VERSION "Arrival Ver 3.3"

NS_ :

BS_:

BU_: VCU EPS IBC
VAL_TABLE_ GlobalRealTime 1 "Valid" 0 "Invalid" ;
VAL_TABLE_ Driver_Intervention 3 "SNA" 2 "ERROR" 1 "INTERVENTION" 0 "NO INTERVENTION" ;
VAL_TABLE_ DM_AD_Activation 3 "SNA" 2 "ERROR" 1 "ON" 0 "OFF" ;
VAL_TABLE_ DM_Mode_AD_HMI 4 "AD ERROR" 3 "AD MEAS ON" 2 "AD ON" 1 "AD READY" 0 "AD OFF" ;
VAL_TABLE_ MOTLmtd 1 "MOT_Limited" 0 "MOT_NotLimited" ;
VAL_TABLE_ SPCLmtd 1 "SPC_Limited" 0 "SPC_NotLimited" ;
VAL_TABLE_ BCUIntLghtSt 3 "sna" 2 "on" 1 "dimmed" 0 "off" ;
VAL_TABLE_ CCUClInf 1 "active" 0 "not active" ;
VAL_TABLE_ PositiveNegative 1 "Negative" 0 "Positive" ;
VAL_TABLE_ ActiveNot 1 "Active" 0 "Not Active" ;
VAL_TABLE_ EPSTrqOvrly 3 "Permanently Failed" 2 "Temporarily Limited" 1 "Active" 0 "Inactive" ;
VAL_TABLE_ HandsOnDetected 1 "TakeOverDetected" 0 "NoTakeOverDetected" ;
VAL_TABLE_ EPSCurrState 9 "EPS_Failed" 8 "EPS_ShutDown" 7 "EPS_ReadyToSleep" 6 "EPS_AutoAndPosHold" 5 "EPS_AutoAndPosServoActive" 4 "EPS_ManualAndPosServoFail" 3 "EPS_ManualAndPosServoInhibit" 2 "EPS_ManualAndPosServoReady" 1 "EPS_Init" 0 "EPS_Off" ;
VAL_TABLE_ Vldt1 1 "Invalid" 0 "Valid" ;
VAL_TABLE_ Vldt2 3 "sna" 2 "error" 1 "Invalid" 0 "Valid" ;
VAL_TABLE_ ADSt 15 "sna" 14 "error" 5 "Autonomous Drive" 4 "Failure" 3 "Shutdown" 2 "Inhibit" 1 "Active" 0 "Init" ;
VAL_TABLE_ SNAERRneg 1 "error" 0 "sna" ;
VAL_TABLE_ SNAERR3 7 "sna" 6 "error" ;
VAL_TABLE_ SNAERR4 15 "sna" 14 "error" ;
VAL_TABLE_ SNAERR5 31 "sna" 30 "error" ;
VAL_TABLE_ SNAERR6 63 "sna" 62 "error" ;
VAL_TABLE_ SNAERR7 127 "sna" 126 "error" ;
VAL_TABLE_ SNAERR8 255 "sna" 254 "error" ;
VAL_TABLE_ SNAERR9 511 "sna" 510 "error" ;
VAL_TABLE_ SNAERR10 1023 "sna" 1022 "error" ;
VAL_TABLE_ SNAERR11 2047 "sna" 2046 "error" ;
VAL_TABLE_ SNAERR12 4095 "sna" 4094 "error" ;
VAL_TABLE_ SNAERR13 8191 "sna" 8190 "error" ;
VAL_TABLE_ SNAERR14 16383 "sna" 16382 "error" ;
VAL_TABLE_ SNAERR15 32767 "sna" 32766 "error" ;
VAL_TABLE_ SNAERR16 65535 "sna" 65534 "error" ;
VAL_TABLE_ SNAERR17 131071 "sna" 131070 "error" ;
VAL_TABLE_ SNAERR18 262143 "sna" 262142 "error" ;
VAL_TABLE_ SNAERR19 524287 "sna" 524286 "error" ;
VAL_TABLE_ SNAERR20 1048575 "sna" 1048574 "error" ;
VAL_TABLE_ SNAERR21 2097151 "sna" 2097150 "error" ;
VAL_TABLE_ SNAERR22 4194303 "sna" 4194302 "error" ;
VAL_TABLE_ SNAERR23 8388607 "sna" 8388606 "error" ;
VAL_TABLE_ SNAERR24 16777215 "sna" 16777214 "error" ;
VAL_TABLE_ SNAERR32 -1 "sna" -2 "error" ;
VAL_TABLE_ IBCRegenBrkSt 1 "active" 0 "passive" ;
VAL_TABLE_ IntErr 3 "sna" 2 "red" 1 "yellow" 0 "green" ;
VAL_TABLE_ VhclLckSt 1 "locked" 0 "unlocked" ;

BO_ 1 New_Message_59: 8 Vector__XXX
 SG_ New_Signal_483 : 32|8@1+ (1,0) [0|0] "" Vector__XXX

BO_ 0 New_Message_58: 8 Vector__XXX
 SG_ New_Signal_482 : 0|8@1+ (1,0) [0|0] "" Vector__XXX

BO_ 168 EPS_FD_Data: 8 EPS
 SG_ EPS_Data_Export_1 : 39|32@0+ (1,0) [0|4294967295] "" Vector__XXX
 SG_ EPS_Data_Export_0 : 7|32@0+ (1,0) [0|4294967295] "" Vector__XXX

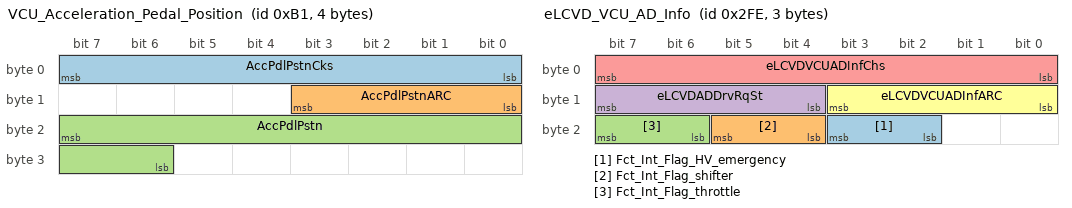
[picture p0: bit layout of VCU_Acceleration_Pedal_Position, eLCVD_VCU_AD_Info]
BO_ 177 VCU_Acceleration_Pedal_Position: 4 VCU
 SG_ AccPdlPstnCks : 7|8@0+ (1,0) [0|255] ""  IBC
 SG_ AccPdlPstnARC : 11|4@0+ (1,0) [0|15] ""  IBC
 SG_ AccPdlPstn : 23|10@0+ (0.1,0) [0|102.3] "%"  IBC

BO_ 766 eLCVD_VCU_AD_Info: 3 VCU
 SG_ Fct_Int_Flag_HV_emergency : 19|2@0+ (1,0) [0|3] ""  EPS,IBC
 SG_ Fct_Int_Flag_shifter : 21|2@0+ (1,0) [0|3] ""  EPS,IBC
 SG_ Fct_Int_Flag_throttle : 23|2@0+ (1,0) [0|3] ""  EPS,IBC
 SG_ eLCVDADDrvRqSt : 15|4@0+ (1,0) [0|15] ""  EPS,IBC
 SG_ eLCVDVCUADInfChs : 7|8@0+ (1,0) [0|255] ""  EPS,IBC
 SG_ eLCVDVCUADInfARC : 11|4@0+ (1,0) [0|15] ""  EPS,IBC

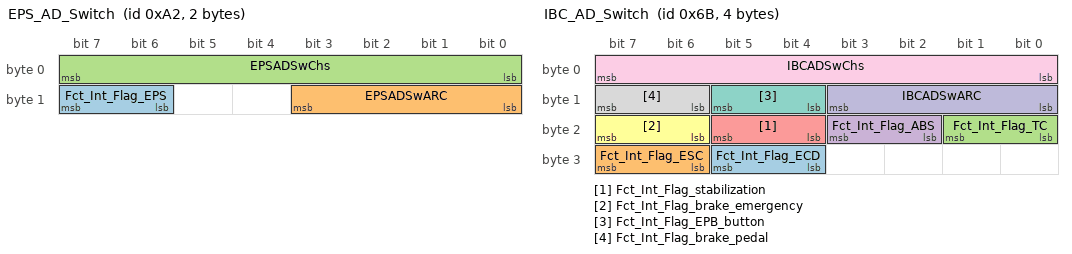
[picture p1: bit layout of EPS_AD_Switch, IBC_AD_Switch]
BO_ 162 EPS_AD_Switch: 2 EPS
 SG_ Fct_Int_Flag_EPS : 15|2@0+ (1,0) [0|3] ""  IBC,VCU
 SG_ EPSADSwARC : 11|4@0+ (1,0) [0|15] ""  IBC,VCU
 SG_ EPSADSwChs : 7|8@0+ (1,0) [0|255] ""  IBC,VCU

BO_ 107 IBC_AD_Switch: 4 IBC
 SG_ Fct_Int_Flag_ECD : 29|2@0+ (1,0) [0|3] ""  EPS,VCU
 SG_ Fct_Int_Flag_ESC : 31|2@0+ (1,0) [0|3] ""  EPS,VCU
 SG_ Fct_Int_Flag_TC : 17|2@0+ (1,0) [0|3] ""  EPS,VCU
 SG_ Fct_Int_Flag_ABS : 19|2@0+ (1,0) [0|3] ""  EPS,VCU
 SG_ Fct_Int_Flag_stabilization : 21|2@0+ (1,0) [0|3] ""  EPS,VCU
 SG_ Fct_Int_Flag_brake_emergency : 23|2@0+ (1,0) [0|3] ""  EPS,VCU
 SG_ Fct_Int_Flag_EPB_button : 13|2@0+ (1,0) [0|3] ""  EPS,VCU
 SG_ Fct_Int_Flag_brake_pedal : 15|2@0+ (1,0) [0|3] ""  EPS,VCU
 SG_ IBCADSwChs : 7|8@0+ (1,0) [0|255] ""  EPS,VCU
 SG_ IBCADSwARC : 11|4@0+ (1,0) [0|15] ""  EPS,VCU

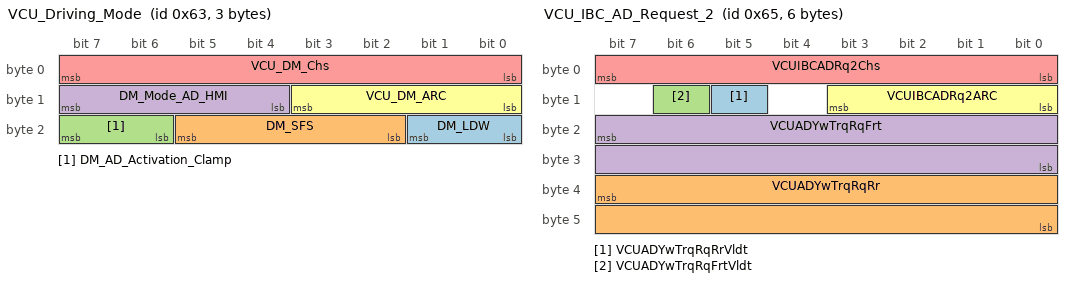
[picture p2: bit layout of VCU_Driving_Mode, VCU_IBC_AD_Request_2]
BO_ 99 VCU_Driving_Mode: 3 VCU
 SG_ DM_LDW : 17|2@0+ (1,0) [0|3] ""  EPS,IBC
 SG_ DM_SFS : 21|4@0+ (1,0) [0|15] ""  EPS,IBC
 SG_ DM_AD_Activation_Clamp : 23|2@0+ (1,0) [0|3] ""  EPS,IBC
 SG_ DM_Mode_AD_HMI : 15|4@0+ (1,0) [0|15] ""  EPS,IBC
 SG_ VCU_DM_Chs : 7|8@0+ (1,0) [0|255] ""  EPS,IBC
 SG_ VCU_DM_ARC : 11|4@0+ (1,0) [0|15] ""  EPS,IBC

BO_ 101 VCU_IBC_AD_Request_2: 6 VCU
 SG_ VCUADYwTrqRqRrVldt : 13|1@0+ (1,0) [0|1] ""  IBC
 SG_ VCUADYwTrqRqRr : 39|16@0+ (1,-32768) [-32768|32767] "Nm"  IBC
 SG_ VCUADYwTrqRqFrtVldt : 14|1@0+ (1,0) [0|1] ""  IBC
 SG_ VCUADYwTrqRqFrt : 23|16@0+ (1,-32768) [-32768|32767] "Nm"  IBC
 SG_ VCUIBCADRq2Chs : 7|8@0+ (1,0) [0|255] ""  IBC
 SG_ VCUIBCADRq2ARC : 11|4@0+ (1,0) [0|15] ""  IBC

BO_ 800 TPMS_Info: 8 VCU
 SG_ ExTirePressSupport : 38|2@1+ (1,0) [0|3] ""  IBC
 SG_ TirePressThresholdDetection_13 m19 : 61|3@1+ (1,0) [0|7] ""  IBC
 SG_ TirePressThresholdDetection_12 m18 : 61|3@1+ (1,0) [0|7] ""  IBC
 SG_ TirePressThresholdDetection_11 m17 : 61|3@1+ (1,0) [0|7] ""  IBC
 SG_ TirePressThresholdDetection_10 m16 : 61|3@1+ (1,0) [0|7] ""  IBC
 SG_ TirePressThresholdDetection_01 m1 : 61|3@1+ (1,0) [0|7] ""  IBC
 SG_ TirePress_33 m51 : 8|8@1+ (4,0) [0|1000] "kPa"  IBC
 SG_ TirePress_32 m50 : 8|8@1+ (4,0) [0|1000] "kPa"  IBC
 SG_ TirePress_31 m49 : 8|8@1+ (4,0) [0|1000] "kPa"  IBC
 SG_ TirePress_30 m48 : 8|8@1+ (4,0) [0|1000] "kPa"  IBC
 SG_ TirePress_23 m35 : 8|8@1+ (4,0) [0|1000] "kPa"  IBC
 SG_ TirePress_22 m34 : 8|8@1+ (4,0) [0|1000] "kPa"  IBC
 SG_ TirePress_21 m33 : 8|8@1+ (4,0) [0|1000] "kPa"  IBC
 SG_ TirePress_20 m32 : 8|8@1+ (4,0) [0|1000] "kPa"  IBC
 SG_ TirePress_13 m19 : 8|8@1+ (4,0) [0|1000] "kPa"  IBC
 SG_ TirePress_12 m18 : 8|8@1+ (4,0) [0|1000] "kPa"  IBC
 SG_ TirePress_11 m17 : 8|8@1+ (4,0) [0|1000] "kPa"  IBC
 SG_ TirePress_10 m16 : 8|8@1+ (4,0) [0|1000] "kPa"  IBC
 SG_ TireAirLeakageRate_33 m51 : 40|16@1+ (0.1,0) [0|6425.5] "Pa/s"  IBC
 SG_ TireAirLeakageRate_32 m50 : 40|16@1+ (0.1,0) [0|6425.5] "Pa/s"  IBC
 SG_ TireAirLeakageRate_31 m49 : 40|16@1+ (0.1,0) [0|6425.5] "Pa/s"  IBC
 SG_ TireAirLeakageRate_30 m48 : 40|16@1+ (0.1,0) [0|6425.5] "Pa/s"  IBC
 SG_ TireAirLeakageRate_23 m35 : 40|16@1+ (0.1,0) [0|6425.5] "Pa/s"  IBC
 SG_ TireAirLeakageRate_22 m34 : 40|16@1+ (0.1,0) [0|6425.5] "Pa/s"  IBC
 SG_ TireAirLeakageRate_21 m33 : 40|16@1+ (0.1,0) [0|6425.5] "Pa/s"  IBC
 SG_ TireAirLeakageRate_20 m32 : 40|16@1+ (0.1,0) [0|6425.5] "Pa/s"  IBC
 SG_ TireAirLeakageRate_13 m19 : 40|16@1+ (0.1,0) [0|6425.5] "Pa/s"  IBC
 SG_ TireAirLeakageRate_12 m18 : 40|16@1+ (0.1,0) [0|6425.5] "Pa/s"  IBC
 SG_ TireAirLeakageRate_11 m17 : 40|16@1+ (0.1,0) [0|6425.5] "Pa/s"  IBC
 SG_ TireAirLeakageRate_10 m16 : 40|16@1+ (0.1,0) [0|6425.5] "Pa/s"  IBC
 SG_ TireAirLeakageRate_01 m1 : 40|16@1+ (0.1,0) [0|6425.5] "Pa/s"  IBC
 SG_ TireAirLeakageRate_00 m0 : 40|16@1+ (0.1,0) [0|6425.5] "Pa/s"  IBC
 SG_ CTIWheelSensorStatus_33 m51 : 32|2@1+ (1,0) [0|3] ""  IBC
 SG_ CTIWheelSensorStatus_32 m50 : 32|2@1+ (1,0) [0|3] ""  IBC
 SG_ CTIWheelSensorStatus_31 m49 : 32|2@1+ (1,0) [0|3] ""  IBC
 SG_ CTIWheelSensorStatus_30 m48 : 32|2@1+ (1,0) [0|3] ""  IBC
 SG_ CTIWheelSensorStatus_23 m35 : 32|2@1+ (1,0) [0|3] ""  IBC
 SG_ CTIWheelSensorStatus_22 m34 : 32|2@1+ (1,0) [0|3] ""  IBC
 SG_ CTIWheelSensorStatus_21 m33 : 32|2@1+ (1,0) [0|3] ""  IBC
 SG_ CTIWheelSensorStatus_20 m32 : 32|2@1+ (1,0) [0|3] ""  IBC
 SG_ CTIWheelSensorStatus_13 m19 : 32|2@1+ (1,0) [0|3] ""  IBC
 SG_ CTIWheelSensorStatus_12 m18 : 32|2@1+ (1,0) [0|3] ""  IBC
 SG_ CTIWheelSensorStatus_11 m17 : 32|2@1+ (1,0) [0|3] ""  IBC
 SG_ CTIWheelSensorStatus_10 m16 : 32|2@1+ (1,0) [0|3] ""  IBC
 SG_ CTIWheelSensorStatus_01 m1 : 32|2@1+ (1,0) [0|3] ""  IBC
 SG_ CTIWheelEndElectricalFault_33 m51 : 36|2@1+ (1,0) [0|3] ""  IBC
 SG_ CTIWheelEndElectricalFault_32 m50 : 36|2@1+ (1,0) [0|3] ""  IBC
 SG_ CTIWheelEndElectricalFault_31 m49 : 36|2@1+ (1,0) [0|3] ""  IBC
 SG_ CTIWheelEndElectricalFault_30 m48 : 36|2@1+ (1,0) [0|3] ""  IBC
 SG_ CTIWheelEndElectricalFault_23 m35 : 36|2@1+ (1,0) [0|3] ""  IBC
 SG_ CTIWheelEndElectricalFault_22 m34 : 36|2@1+ (1,0) [0|3] ""  IBC
 SG_ CTIWheelEndElectricalFault_21 m33 : 36|2@1+ (1,0) [0|3] ""  IBC
 SG_ CTIWheelEndElectricalFault_20 m32 : 36|2@1+ (1,0) [0|3] ""  IBC
 SG_ CTIWheelEndElectricalFault_13 m19 : 36|2@1+ (1,0) [0|3] ""  IBC
 SG_ CTIWheelEndElectricalFault_12 m18 : 36|2@1+ (1,0) [0|3] ""  IBC
 SG_ CTIWheelEndElectricalFault_11 m17 : 36|2@1+ (1,0) [0|3] ""  IBC
 SG_ CTIWheelEndElectricalFault_10 m16 : 36|2@1+ (1,0) [0|3] ""  IBC
 SG_ CTIWheelEndElectricalFault_01 m1 : 36|2@1+ (1,0) [0|3] ""  IBC
 SG_ CTITireStatus_33 m51 : 34|2@1+ (1,0) [0|3] ""  IBC
 SG_ CTITireStatus_32 m50 : 34|2@1+ (1,0) [0|3] ""  IBC
 SG_ CTITireStatus_31 m49 : 34|2@1+ (1,0) [0|3] ""  IBC
 SG_ CTITireStatus_30 m48 : 34|2@1+ (1,0) [0|3] ""  IBC
 SG_ CTITireStatus_23 m35 : 34|2@1+ (1,0) [0|3] ""  IBC
 SG_ CTITireStatus_22 m34 : 34|2@1+ (1,0) [0|3] ""  IBC
 SG_ CTITireStatus_21 m33 : 34|2@1+ (1,0) [0|3] ""  IBC
 SG_ CTITireStatus_20 m32 : 34|2@1+ (1,0) [0|3] ""  IBC
 SG_ CTITireStatus_13 m19 : 34|2@1+ (1,0) [0|3] ""  IBC
 SG_ CTITireStatus_12 m18 : 34|2@1+ (1,0) [0|3] ""  IBC
 SG_ CTITireStatus_11 m17 : 34|2@1+ (1,0) [0|3] ""  IBC
 SG_ CTITireStatus_10 m16 : 34|2@1+ (1,0) [0|3] ""  IBC
 SG_ CTITireStatus_01 m1 : 34|2@1+ (1,0) [0|3] ""  IBC
 SG_ TireTemp_11 m17 : 16|16@1+ (0.03125,-273) [-273|1735] "°C"  IBC
 SG_ TireTemp_33 m51 : 16|16@1+ (0.03125,-273) [-273|1735] "°C"  IBC
 SG_ TireTemp_32 m50 : 16|16@1+ (0.03125,-273) [-273|1735] "°C"  IBC
 SG_ TireTemp_31 m49 : 16|16@1+ (0.03125,-273) [-273|1735] "°C"  IBC
 SG_ TireTemp_30 m48 : 16|16@1+ (0.03125,-273) [-273|1735] "°C"  IBC
 SG_ TireTemp_23 m35 : 16|16@1+ (0.03125,-273) [-273|1735] "°C"  IBC
 SG_ TireTemp_22 m34 : 16|16@1+ (0.03125,-273) [-273|1735] "°C"  IBC
 SG_ TireTemp_21 m33 : 16|16@1+ (0.03125,-273) [-273|1735] "°C"  IBC
 SG_ TireTemp_20 m32 : 16|16@1+ (0.03125,-273) [-273|1735] "°C"  IBC
 SG_ TireTemp_13 m19 : 16|16@1+ (0.03125,-273) [-273|1735] "°C"  IBC
 SG_ TireTemp_12 m18 : 16|16@1+ (0.03125,-273) [-273|1735] "°C"  IBC
 SG_ TireTemp_10 m16 : 16|16@1+ (0.03125,-273) [-273|1735] "°C"  IBC
 SG_ TireTemp_01 m1 : 16|16@1+ (0.03125,-273) [-273|1735] "°C"  IBC
 SG_ TireTemp_00 m0 : 16|16@1+ (0.03125,-273) [-273|1735] "°C"  IBC
 SG_ TirePressThresholdDetection_33 m51 : 61|3@1+ (1,0) [0|7] ""  IBC
 SG_ TirePressThresholdDetection_32 m50 : 61|3@1+ (1,0) [0|7] ""  IBC
 SG_ TirePressThresholdDetection_31 m49 : 61|3@1+ (1,0) [0|7] ""  IBC
 SG_ TirePressThresholdDetection_30 m48 : 61|3@1+ (1,0) [0|7] ""  IBC
 SG_ TirePressThresholdDetection_23 m35 : 61|3@1+ (1,0) [0|7] ""  IBC
 SG_ TirePressThresholdDetection_22 m34 : 61|3@1+ (1,0) [0|7] ""  IBC
 SG_ TirePressThresholdDetection_21 m33 : 61|3@1+ (1,0) [0|7] ""  IBC
 SG_ TirePressThresholdDetection_20 m32 : 61|3@1+ (1,0) [0|7] ""  IBC
 SG_ TirePressThresholdDetection_00 m0 : 61|3@1+ (1,0) [0|7] ""  IBC
 SG_ TirePress_01 m1 : 8|8@1+ (4,0) [0|1000] "kPa"  IBC
 SG_ TirePress_00 m0 : 8|8@1+ (4,0) [0|1000] "kPa"  IBC
 SG_ CTIWheelSensorStatus_00 m0 : 32|2@1+ (1,0) [0|3] ""  IBC
 SG_ CTIWheelEndElectricalFault_00 m0 : 36|2@1+ (1,0) [0|3] ""  IBC
 SG_ CTITireStatus_00 m0 : 34|2@1+ (1,0) [0|3] ""  IBC
 SG_ TireLocation M : 0|8@1+ (1,0) [0|255] ""  IBC

BO_ 1985 EPS_CCP_RX_CRO: 8 Vector__XXX
 SG_ CRO_data_field : 23|48@0+ (1,0) [0|0] ""  EPS
 SG_ CTR : 15|8@0+ (1,0) [0|0] ""  EPS
 SG_ CMD : 7|8@0+ (1,0) [0|0] ""  EPS

BO_ 2001 EPS_CCP_TX_DTO: 8 EPS
 SG_ PID : 7|8@0+ (1,0) [0|0] "" Vector__XXX

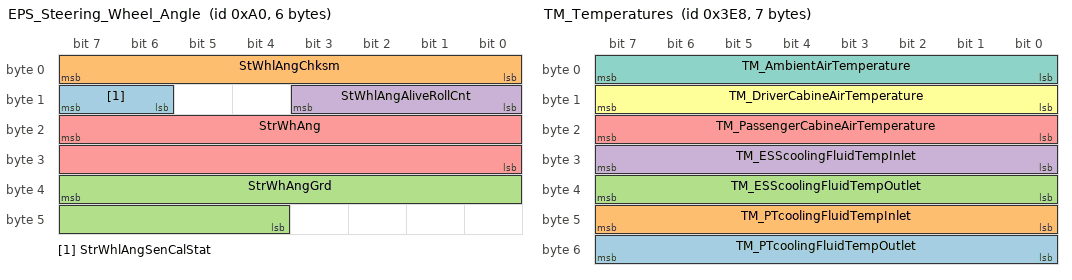
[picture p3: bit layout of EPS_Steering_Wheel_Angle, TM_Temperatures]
BO_ 160 EPS_Steering_Wheel_Angle: 6 EPS
 SG_ StrWhlAngSenCalStat : 15|2@0+ (1,0) [0|3] ""  IBC,VCU
 SG_ StWhlAngChksm : 7|8@0+ (1,0) [0|255] ""  VCU,IBC
 SG_ StrWhAngGrd : 39|12@0+ (1,-2048) [-2048|2047] "deg/sec"  VCU,IBC
 SG_ StWhlAngAliveRollCnt : 11|4@0+ (1,0) [0|15] ""  VCU,IBC
 SG_ StrWhAng : 23|16@0+ (0.025,-819) [-819|819.375] "deg"  VCU,IBC

BO_ 1000 TM_Temperatures: 7 VCU
 SG_ TM_PTcoolingFluidTempOutlet : 55|8@0+ (1,-40) [-40|215] "°C"  IBC
 SG_ TM_PTcoolingFluidTempInlet : 47|8@0+ (1,-40) [-40|215] "°C"  IBC
 SG_ TM_ESScoolingFluidTempOutlet : 39|8@0+ (1,-40) [-40|215] "°C"  IBC
 SG_ TM_ESScoolingFluidTempInlet : 31|8@0+ (1,-40) [-40|215] "°C"  IBC
 SG_ TM_PassengerCabineAirTemperature : 23|8@0+ (1,-40) [-40|215] "°C"  IBC
 SG_ TM_DriverCabineAirTemperature : 15|8@0+ (1,-40) [-40|215] "°C"  IBC
 SG_ TM_AmbientAirTemperature : 7|8@0+ (1,-40) [-40|215] "°C"  IBC

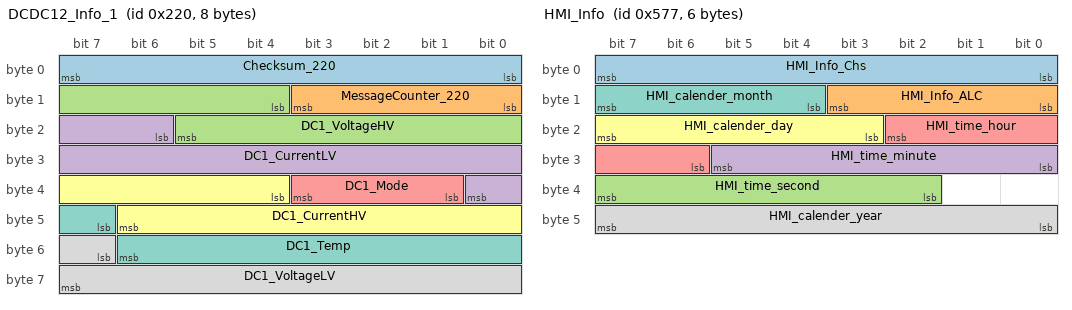
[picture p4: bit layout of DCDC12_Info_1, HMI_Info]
BO_ 544 DCDC12_Info_1: 8 VCU
 SG_ Checksum_220 : 0|8@1+ (1,0) [0|255] "-"  EPS,IBC
 SG_ MessageCounter_220 : 8|4@1+ (1,0) [0|15] "-"  EPS,IBC
 SG_ DC1_VoltageHV : 12|10@1+ (1,0) [0|1021] "V"  EPS,IBC
 SG_ DC1_CurrentLV : 22|11@1+ (1,-1023) [-1023|1022] "A"  EPS,IBC
 SG_ DC1_Mode : 33|3@1+ (1,0) [0|7] "-"  EPS,IBC
 SG_ DC1_CurrentHV : 36|11@1+ (0.0625,-63.90625) [-63.90625|63.90625] "A"  EPS,IBC
 SG_ DC1_Temp : 47|8@1+ (1,-40) [-40|213] "°C"  EPS,IBC
 SG_ DC1_VoltageLV : 55|9@1+ (0.125,0) [0|63.625] "V"  EPS,IBC

BO_ 1399 HMI_Info: 6 VCU
 SG_ HMI_Info_Chs : 7|8@0+ (1,0) [0|255] ""  EPS,IBC
 SG_ HMI_Info_ALC : 11|4@0+ (1,0) [0|15] "Counts"  EPS,IBC
 SG_ HMI_time_second : 39|6@0+ (1,1) [1|64] "s"  EPS,IBC
 SG_ HMI_time_minute : 29|6@0+ (1,1) [1|64] "min"  EPS,IBC
 SG_ HMI_time_hour : 18|5@0+ (1,1) [1|32] "h"  EPS,IBC
 SG_ HMI_calender_day : 23|5@0+ (1,1) [1|32] ""  EPS,IBC
 SG_ HMI_calender_month : 15|4@0+ (1,1) [1|16] ""  EPS,IBC
 SG_ HMI_calender_year : 47|8@0+ (1,2000) [2000|2255] ""  EPS,IBC

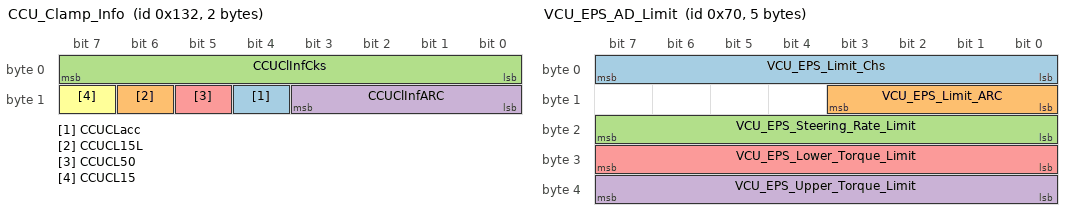
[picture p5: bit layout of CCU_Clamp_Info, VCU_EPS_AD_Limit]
BO_ 306 CCU_Clamp_Info: 2 VCU
 SG_ CCUCLacc : 12|1@0+ (1,0) [0|1] ""  IBC
 SG_ CCUCL15L : 14|1@0+ (1,0) [0|1] ""  IBC
 SG_ CCUClInfCks : 7|8@0+ (1,0) [0|255] ""  IBC
 SG_ CCUClInfARC : 11|4@0+ (1,0) [0|15] ""  IBC
 SG_ CCUCL50 : 13|1@0+ (1,0) [0|1] ""  IBC
 SG_ CCUCL15 : 15|1@0+ (1,0) [0|1] ""  IBC

BO_ 112 VCU_EPS_AD_Limit: 5 VCU
 SG_ VCU_EPS_Limit_Chs : 7|8@0+ (1,0) [0|255] "" Vector__XXX
 SG_ VCU_EPS_Limit_ARC : 11|4@0+ (1,0) [0|15] "" Vector__XXX
 SG_ VCU_EPS_Steering_Rate_Limit : 23|8@0+ (10,-1275) [-1275|1275] "Deg/s" Vector__XXX
 SG_ VCU_EPS_Upper_Torque_Limit : 39|8@0+ (0.1,-12.8) [-12.8|12.7] "Nm" Vector__XXX
 SG_ VCU_EPS_Lower_Torque_Limit : 31|8@0+ (0.1,-12.8) [-12.8|12.7] "Nm" Vector__XXX

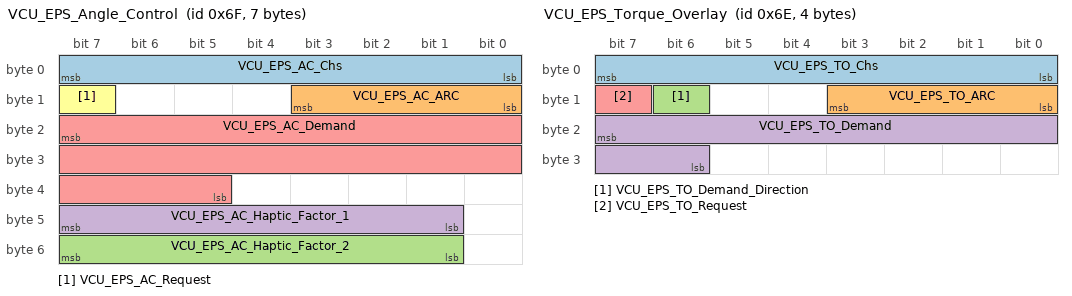
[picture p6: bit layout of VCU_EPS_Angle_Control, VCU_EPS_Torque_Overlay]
BO_ 111 VCU_EPS_Angle_Control: 7 VCU
 SG_ VCU_EPS_AC_Chs : 7|8@0+ (1,0) [0|255] ""  EPS
 SG_ VCU_EPS_AC_ARC : 11|4@0+ (1,0) [0|15] ""  EPS
 SG_ VCU_EPS_AC_Haptic_Factor_2 : 55|7@0+ (0.00787402,0) [0|1.00000054] ""  EPS
 SG_ VCU_EPS_AC_Haptic_Factor_1 : 47|7@0+ (0.00787402,0) [0|1.00000054] ""  EPS
 SG_ VCU_EPS_AC_Demand : 23|19@0+ (0.005,-1310.72) [-720|720] "Deg"  EPS
 SG_ VCU_EPS_AC_Request : 15|1@0+ (1,0) [0|1] ""  EPS

BO_ 110 VCU_EPS_Torque_Overlay: 4 VCU
 SG_ VCU_EPS_TO_Chs : 7|8@0+ (1,0) [0|255] "" Vector__XXX
 SG_ VCU_EPS_TO_ARC : 11|4@0+ (1,0) [0|15] "" Vector__XXX
 SG_ VCU_EPS_TO_Demand_Direction : 14|1@0+ (1,0) [0|1] "" Vector__XXX
 SG_ VCU_EPS_TO_Demand : 23|10@0+ (0.01,0) [0|10.23] "Nm" Vector__XXX
 SG_ VCU_EPS_TO_Request : 15|1@0+ (1,0) [0|1] "" Vector__XXX

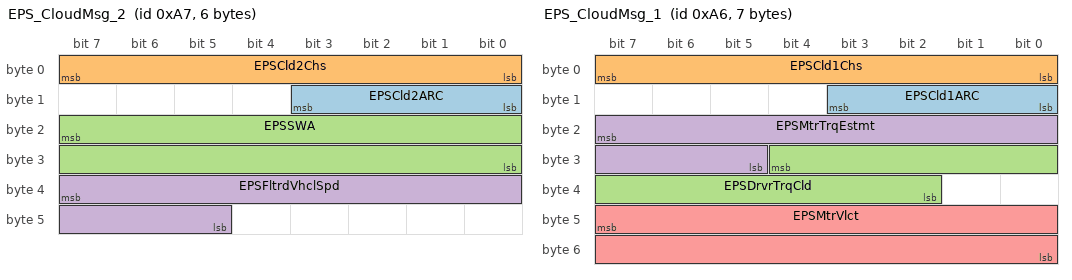
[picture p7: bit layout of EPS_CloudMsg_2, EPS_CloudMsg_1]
BO_ 167 EPS_CloudMsg_2: 6 EPS
 SG_ EPSCld2ARC : 11|4@0+ (1,0) [0|15] ""  VCU
 SG_ EPSCld2Chs : 7|8@0+ (1,0) [0|255] ""  VCU
 SG_ EPSSWA : 23|16@0+ (0.025,-819) [-819|819.375] "Deg"  VCU
 SG_ EPSFltrdVhclSpd : 39|11@0+ (0.1,0) [0|204.7] "km/h"  VCU

BO_ 166 EPS_CloudMsg_1: 7 EPS
 SG_ EPSCld1ARC : 11|4@0+ (1,0) [0|15] ""  VCU
 SG_ EPSCld1Chs : 7|8@0+ (1,0) [0|255] ""  VCU
 SG_ EPSDrvrTrqCld : 28|11@0+ (0.01,-10.23) [-10.23|10.24] "Nm"  VCU
 SG_ EPSMtrTrqEstmt : 23|11@0+ (0.01,-10.23) [-10.23|10.24] "Nm"  VCU
 SG_ EPSMtrVlct : 47|16@0+ (0.005,-163.34) [-163.34|164.335] "rev/s"  VCU

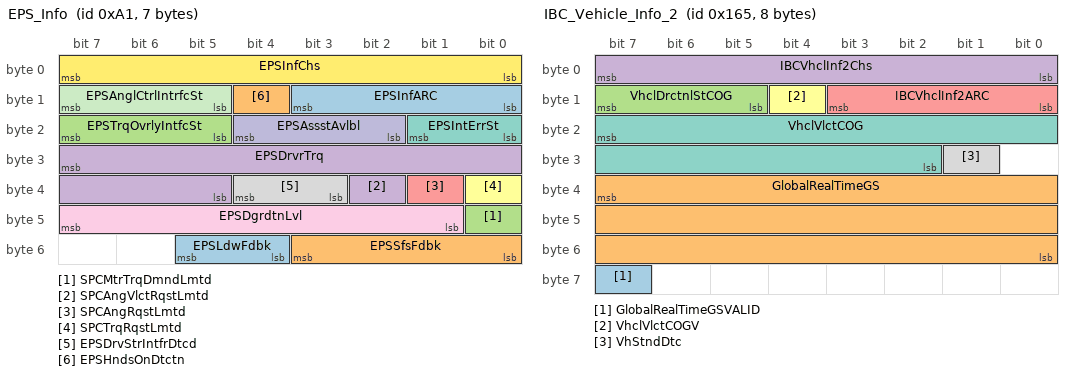
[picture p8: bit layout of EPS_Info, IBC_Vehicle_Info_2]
BO_ 161 EPS_Info: 7 EPS
 SG_ EPSLdwFdbk : 53|2@0+ (1,0) [0|3] "" Vector__XXX
 SG_ EPSSfsFdbk : 51|4@0+ (1,0) [0|15] ""  VCU
 SG_ SPCMtrTrqDmndLmtd : 40|1@0+ (1,0) [0|1] ""  VCU
 SG_ SPCAngVlctRqstLmtd : 34|1@0+ (1,0) [0|1] ""  VCU
 SG_ SPCAngRqstLmtd : 33|1@0+ (1,0) [0|1] ""  VCU
 SG_ SPCTrqRqstLmtd : 32|1@0+ (1,0) [0|1] ""  VCU
 SG_ EPSIntErrSt : 17|2@0+ (1,0) [0|3] ""  VCU
 SG_ EPSDrvStrIntfrDtcd : 36|2@0+ (1,0) [0|3] ""  VCU
 SG_ EPSDgrdtnLvl : 47|7@0+ (1,0) [0|100] "%"  VCU
 SG_ EPSAssstAvlbl : 20|3@0+ (1,0) [0|7] ""  VCU
 SG_ EPSAnglCtrlIntrfcSt : 15|3@0+ (1,0) [0|4] ""  VCU
 SG_ EPSInfChs : 7|8@0+ (1,0) [0|255] ""  VCU
 SG_ EPSInfARC : 11|4@0+ (1,0) [0|15] "Counts"  VCU
 SG_ EPSHndsOnDtctn : 12|1@0+ (1,0) [0|1] ""  VCU
 SG_ EPSTrqOvrlyIntfcSt : 23|3@0+ (1,0) [0|3] ""  VCU
 SG_ EPSDrvrTrq : 31|11@0+ (0.01,-10.24) [-10.24|10.23] "Nm"  VCU

BO_ 357 IBC_Vehicle_Info_2: 8 IBC
 SG_ GlobalRealTimeGSVALID : 63|1@0+ (1,0) [0|1] ""  EPS
 SG_ GlobalRealTimeGS : 39|24@0+ (1,0) [0|16777215] "min"  EPS
 SG_ VhclDrctnlStCOG : 15|3@0+ (1,0) [0|7] ""  EPS,VCU
 SG_ IBCVhclInf2Chs : 7|8@0+ (1,0) [0|255] ""  VCU,EPS
 SG_ IBCVhclInf2ARC : 11|4@0+ (1,0) [0|15] ""  VCU,EPS
 SG_ VhclVlctCOGV : 12|1@0+ (1,0) [0|1] ""  VCU,EPS
 SG_ VhclVlctCOG : 23|14@0+ (0.03125,0) [0|511.96875] "km / h"  VCU,EPS
 SG_ VhStndDtc : 25|1@0+ (1,0) [0|1] ""  EPS,VCU

BO_ 106 IBC_VCU_AD_Info_2: 4 IBC
 SG_ IBCADVhclActBrkTrq : 23|16@0+ (1,-32768) [-32768|32767] "Nm"  VCU
 SG_ IBCVCUADInf2Chs : 7|8@0+ (1,0) [0|255] ""  VCU
 SG_ IBCVCUADInf2ARC : 11|4@0+ (1,0) [0|15] ""  VCU

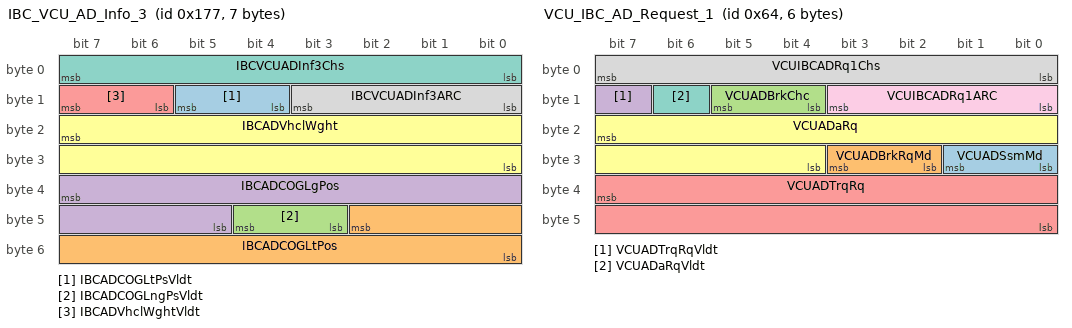
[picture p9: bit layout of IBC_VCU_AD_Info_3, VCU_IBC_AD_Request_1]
BO_ 375 IBC_VCU_AD_Info_3: 7 IBC
 SG_ IBCADCOGLtPsVldt : 13|2@0+ (1,0) [0|3] ""  VCU
 SG_ IBCADCOGLtPos : 42|11@0+ (0.01,-10.24) [-10.24|10.23] "m"  VCU
 SG_ IBCADCOGLngPsVldt : 44|2@0+ (1,0) [0|3] ""  VCU
 SG_ IBCADCOGLgPos : 39|11@0+ (0.01,-10.24) [-10.24|10.23] "m"  VCU
 SG_ IBCADVhclWghtVldt : 15|2@0+ (1,0) [0|3] ""  VCU
 SG_ IBCADVhclWght : 23|16@0+ (1,0) [0|65535] "kg"  VCU
 SG_ IBCVCUADInf3Chs : 7|8@0+ (1,0) [0|255] ""  VCU
 SG_ IBCVCUADInf3ARC : 11|4@0+ (1,0) [0|15] ""  VCU

BO_ 100 VCU_IBC_AD_Request_1: 6 VCU
 SG_ VCUADSsmMd : 25|2@0+ (1,0) [0|3] ""  IBC
 SG_ VCUADBrkRqMd : 27|2@0+ (1,0) [0|3] ""  IBC
 SG_ VCUADBrkChc : 13|2@0+ (1,0) [0|3] ""  IBC
 SG_ VCUADTrqRqVldt : 15|1@0+ (1,0) [0|1] ""  IBC
 SG_ VCUADTrqRq : 39|16@0+ (1,-32768) [-32768|32767] "Nm"  IBC
 SG_ VCUADaRq : 23|12@0+ (0.01,-20.48) [-20.48|20.47] "m/s^2"  IBC
 SG_ VCUADaRqVldt : 14|1@0+ (1,0) [0|1] ""  IBC
 SG_ VCUIBCADRq1Chs : 7|8@0+ (1,0) [0|255] ""  IBC
 SG_ VCUIBCADRq1ARC : 11|4@0+ (1,0) [0|15] ""  IBC

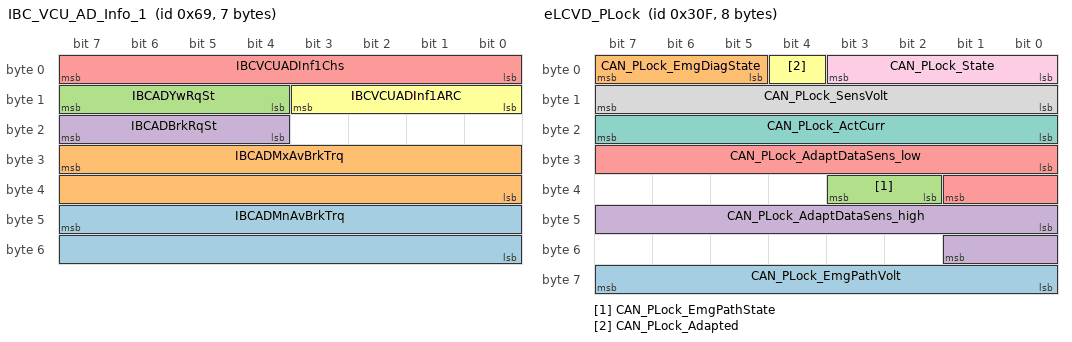
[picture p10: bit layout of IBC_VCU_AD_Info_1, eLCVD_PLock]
BO_ 105 IBC_VCU_AD_Info_1: 7 IBC
 SG_ IBCADMnAvBrkTrq : 47|16@0+ (1,-32768) [-32768|32767] "Nm"  VCU
 SG_ IBCADMxAvBrkTrq : 31|16@0+ (1,-32768) [-32768|32767] "Nm"  VCU
 SG_ IBCADYwRqSt : 15|4@0+ (1,0) [0|15] ""  VCU
 SG_ IBCADBrkRqSt : 23|4@0+ (1,0) [0|15] ""  VCU
 SG_ IBCVCUADInf1Chs : 7|8@0+ (1,0) [0|255] ""  VCU
 SG_ IBCVCUADInf1ARC : 11|4@0+ (1,0) [0|15] ""  VCU

BO_ 777 eLCVD_Driver_Torque_Request: 4 VCU
 SG_ eLCVDDrvTrqRqChs : 7|8@0+ (1,0) [0|255] ""  IBC
 SG_ eLCVDDrvTrqRqARC : 11|4@0+ (1,0) [0|15] ""  IBC
 SG_ eLCVDDrvTrqRq : 23|14@0+ (1,-16383) [-16383|0] "Nm"  IBC

BO_ 783 eLCVD_PLock: 8 VCU
 SG_ CAN_PLock_EmgPathVolt : 56|8@1+ (0.1,0) [0|24] "V"  IBC
 SG_ CAN_PLock_EmgDiagState : 5|3@1+ (1,0) [0|15] ""  IBC
 SG_ CAN_PLock_EmgPathState : 34|2@1+ (1,0) [0|3] ""  IBC
 SG_ CAN_PLock_AdaptDataSens_high : 40|10@1+ (0.005,0) [0|5] "V"  IBC
 SG_ CAN_PLock_AdaptDataSens_low : 24|10@1+ (0.005,0) [0|5] "V"  IBC
 SG_ CAN_PLock_Adapted : 4|1@1+ (1,0) [0|1] ""  IBC
 SG_ CAN_PLock_ActCurr : 16|8@1+ (0.04,0) [0|10] "A"  IBC
 SG_ CAN_PLock_SensVolt : 8|8@1+ (0.02,0) [0|5] "V"  IBC
 SG_ CAN_PLock_State : 0|4@1+ (1,0) [0|15] ""  IBC

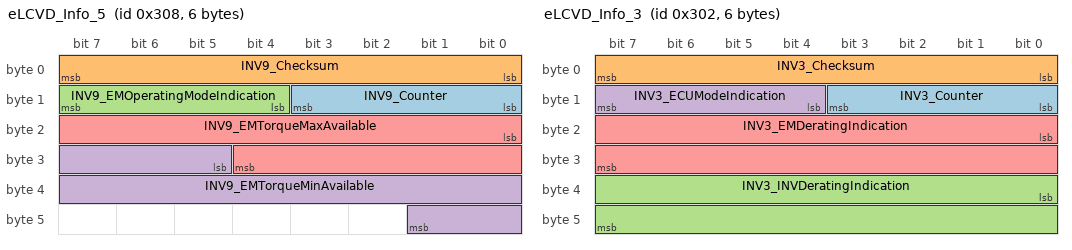
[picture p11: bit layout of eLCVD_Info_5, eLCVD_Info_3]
BO_ 776 eLCVD_Info_5: 6 VCU
 SG_ INV9_Counter : 8|4@1+ (1,0) [0|15] ""  IBC
 SG_ INV9_Checksum : 0|8@1+ (1,0) [0|255] ""  IBC
 SG_ INV9_EMOperatingModeIndication : 12|4@1+ (1,0) [0|15] "Coded"  IBC
 SG_ INV9_EMTorqueMinAvailable : 29|13@1+ (0.25,-2047) [-2047|0] "Nm"  IBC
 SG_ INV9_EMTorqueMaxAvailable : 16|13@1+ (0.25,0) [0|2047] "Nm"  IBC

BO_ 770 eLCVD_Info_3: 6 VCU
 SG_ INV3_Counter : 8|4@1+ (1,0) [0|15] ""  IBC
 SG_ INV3_Checksum : 0|8@1+ (1,0) [0|255] ""  IBC
 SG_ INV3_INVDeratingIndication : 32|16@1+ (1,0) [0|65535] "Coded"  IBC
 SG_ INV3_ECUModeIndication : 12|4@1+ (1,0) [0|15] "Coded"  IBC
 SG_ INV3_EMDeratingIndication : 16|16@1+ (1,0) [0|65535] "Coded"  IBC

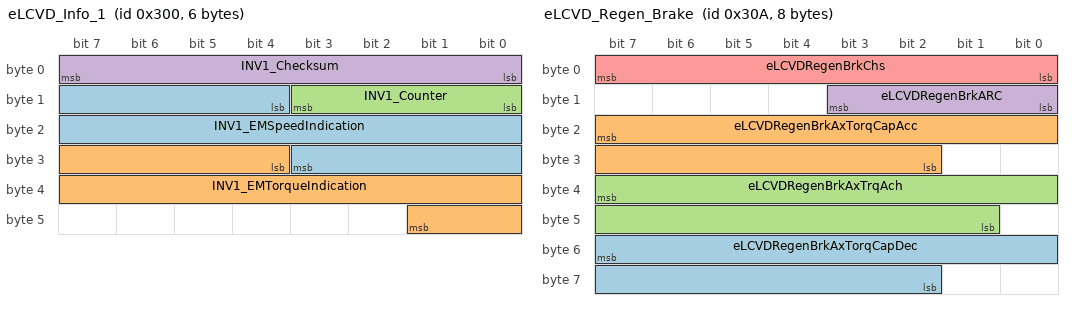
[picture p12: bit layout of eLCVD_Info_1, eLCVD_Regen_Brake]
BO_ 768 eLCVD_Info_1: 6 VCU
 SG_ INV1_EMSpeedIndication : 12|16@1+ (1,-32765) [-32765|32765] "1/min"  IBC
 SG_ INV1_EMTorqueIndication : 28|14@1+ (0.25,-2048) [-2048|2047] "Nm"  IBC
 SG_ INV1_Counter : 8|4@1+ (1,0) [0|15] ""  IBC
 SG_ INV1_Checksum : 0|8@1+ (1,0) [0|255] ""  IBC

BO_ 778 eLCVD_Regen_Brake: 8 VCU
 SG_ eLCVDRegenBrkAxTorqCapDec : 55|14@0+ (1,-16383) [-16383|0] "Nm"  IBC
 SG_ eLCVDRegenBrkAxTorqCapAcc : 23|14@0+ (1,0) [0|16383] "Nm"  IBC
 SG_ eLCVDRegenBrkAxTrqAch : 39|15@0+ (1,-16383) [-16383|16384] ""  IBC
 SG_ eLCVDRegenBrkARC : 11|4@0+ (1,0) [0|15] ""  IBC
 SG_ eLCVDRegenBrkChs : 7|8@0+ (1,0) [0|255] ""  IBC

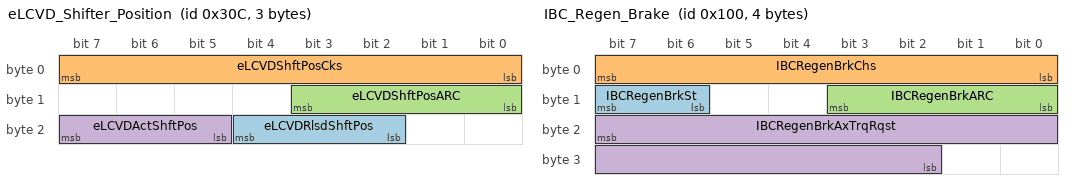
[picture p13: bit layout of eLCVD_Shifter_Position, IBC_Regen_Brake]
BO_ 780 eLCVD_Shifter_Position: 3 VCU
 SG_ eLCVDRlsdShftPos : 20|3@0+ (1,0) [0|7] ""  IBC
 SG_ eLCVDShftPosCks : 7|8@0+ (1,0) [0|255] ""  IBC
 SG_ eLCVDShftPosARC : 11|4@0+ (1,0) [0|15] ""  IBC
 SG_ eLCVDActShftPos : 23|3@0+ (1,0) [0|7] ""  IBC

BO_ 1402 IBC_Error: 2 IBC
 SG_ IBCIntErrChs : 7|8@0+ (1,0) [0|255] ""  VCU
 SG_ IBCIntErrARC : 11|4@0+ (1,0) [0|15] "Counts"  VCU
 SG_ IBCIntErrSt : 15|2@0+ (1,0) [0|3] ""  VCU

BO_ 256 IBC_Regen_Brake: 4 IBC
 SG_ IBCRegenBrkSt : 15|2@0+ (1,0) [0|3] ""  VCU
 SG_ IBCRegenBrkChs : 7|8@0+ (1,0) [0|255] ""  VCU
 SG_ IBCRegenBrkARC : 11|4@0+ (1,0) [0|15] ""  VCU
 SG_ IBCRegenBrkAxTrqRqst : 23|14@0+ (1,-16383) [-16383|0] "Nm"  VCU

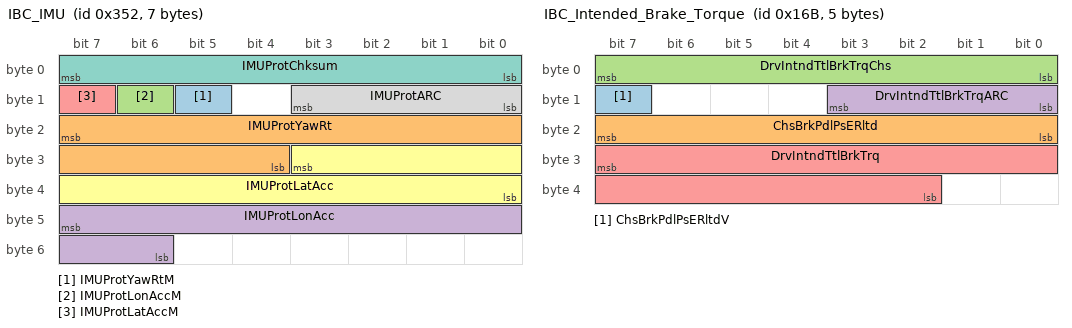
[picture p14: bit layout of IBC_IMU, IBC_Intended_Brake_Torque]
BO_ 850 IBC_IMU: 7 IBC
 SG_ IMUProtYawRtM : 13|1@0+ (1,0) [0|1] ""  EPS,VCU
 SG_ IMUProtYawRt : 23|12@0+ (0.0625,-128) [-128|127.9375] "deg/sec"  EPS,VCU
 SG_ IMUProtLonAccM : 14|1@0+ (1,0) [0|1] ""  EPS,VCU
 SG_ IMUProtLonAcc : 47|10@0+ (0.03,-15.36) [-15.36|15.33] "m/s^2"  EPS,VCU
 SG_ IMUProtLatAccM : 15|1@0+ (1,0) [0|1] ""  EPS,VCU
 SG_ IMUProtLatAcc : 27|12@0+ (0.015625,-32) [-32|31.984375] "m/s^2"  EPS,VCU
 SG_ IMUProtChksum : 7|8@0+ (1,0) [0|255] ""  EPS,VCU
 SG_ IMUProtARC : 11|4@0+ (1,0) [0|15] ""  EPS,VCU

BO_ 363 IBC_Intended_Brake_Torque: 5 IBC
 SG_ ChsBrkPdlPsERltdV : 15|1@0+ (1,0) [0|1] ""  VCU
 SG_ ChsBrkPdlPsERltd : 23|8@0+ (0.392157,0) [0|100.000035] "%"  VCU
 SG_ DrvIntndTtlBrkTrqChs : 7|8@0+ (1,0) [0|255] ""  VCU
 SG_ DrvIntndTtlBrkTrqARC : 11|4@0+ (1,0) [0|15] ""  VCU
 SG_ DrvIntndTtlBrkTrq : 31|14@0+ (2,0) [0|32766] "Nm"  VCU

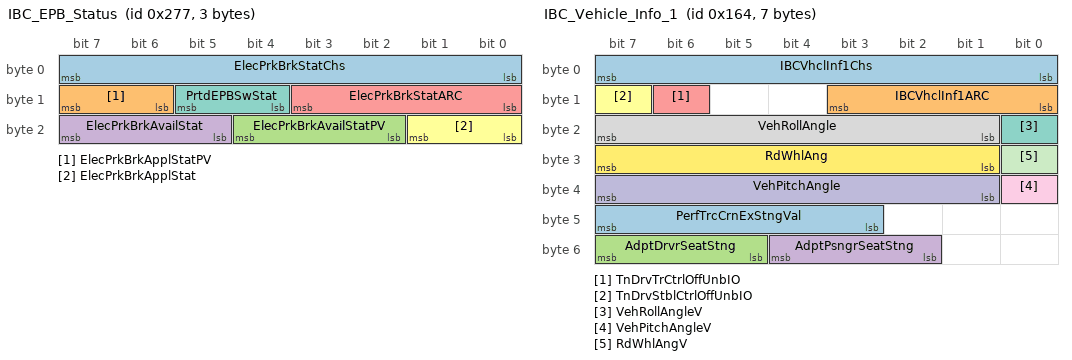
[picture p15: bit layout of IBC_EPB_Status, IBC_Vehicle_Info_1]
BO_ 631 IBC_EPB_Status: 3 IBC
 SG_ ElecPrkBrkStatChs : 7|8@0+ (1,0) [0|255] ""  VCU
 SG_ ElecPrkBrkApplStatPV : 15|2@0+ (1,0) [0|3] ""  VCU
 SG_ ElecPrkBrkAvailStatPV : 20|3@0+ (1,0) [0|7] ""  VCU
 SG_ ElecPrkBrkAvailStat : 23|3@0+ (1,0) [0|7] ""  VCU
 SG_ ElecPrkBrkStatARC : 11|4@0+ (1,0) [0|15] ""  VCU
 SG_ ElecPrkBrkApplStat : 17|2@0+ (1,0) [0|3] ""  VCU
 SG_ PrtdEPBSwStat : 13|2@0+ (1,0) [0|3] ""  VCU

BO_ 356 IBC_Vehicle_Info_1: 7 IBC
 SG_ IBCVhclInf1Chs : 7|8@0+ (1,0) [0|255] ""  VCU
 SG_ IBCVhclInf1ARC : 11|4@0+ (1,0) [0|15] ""  VCU
 SG_ AdptDrvrSeatStng : 55|3@0+ (1,0) [0|7] ""  VCU
 SG_ AdptPsngrSeatStng : 52|3@0+ (1,0) [0|7] ""  VCU
 SG_ TnDrvTrCtrlOffUnbIO : 14|1@0+ (1,0) [0|1] ""  VCU
 SG_ TnDrvStblCtrlOffUnbIO : 15|1@0+ (1,0) [0|1] ""  VCU
 SG_ VehRollAngleV : 16|1@0+ (1,0) [0|1] ""  VCU
 SG_ VehRollAngle : 23|7@0+ (0.703125,-45) [-45|44.296875] "deg"  VCU
 SG_ VehPitchAngleV : 32|1@0+ (1,0) [0|1] ""  VCU
 SG_ VehPitchAngle : 39|7@0+ (0.703125,-45) [-45|44.296875] "deg"  VCU
 SG_ RdWhlAngV : 24|1@0+ (1,0) [0|1] ""  VCU
 SG_ RdWhlAng : 31|7@0+ (0.703125,-45) [-45|44.296875] "deg"  VCU
 SG_ PerfTrcCrnExStngVal : 47|5@0+ (1,0) [0|31] ""  VCU

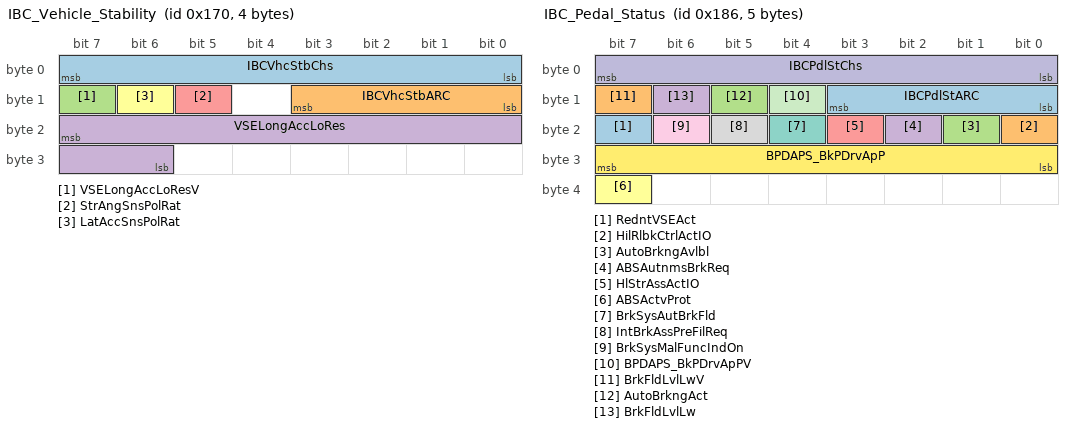
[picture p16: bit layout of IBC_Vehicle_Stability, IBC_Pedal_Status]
BO_ 368 IBC_Vehicle_Stability: 4 IBC
 SG_ IBCVhcStbChs : 7|8@0+ (1,0) [0|255] ""  VCU
 SG_ IBCVhcStbARC : 11|4@0+ (1,0) [0|15] ""  VCU
 SG_ VSELongAccLoResV : 15|1@0+ (1,0) [0|1] ""  VCU
 SG_ VSELongAccLoRes : 23|10@0+ (0.03,-15.36) [-15.36|15.33] "m/s^2"  VCU
 SG_ StrAngSnsPolRat : 13|1@0+ (1,0) [0|1] ""  VCU
 SG_ LatAccSnsPolRat : 14|1@0+ (1,0) [0|1] ""  VCU

BO_ 390 IBC_Pedal_Status: 5 IBC
 SG_ RedntVSEAct : 23|1@0+ (1,0) [0|1] ""  VCU
 SG_ HilRlbkCtrlActIO : 16|1@0+ (1,0) [0|1] ""  VCU
 SG_ AutoBrkngAvlbl : 17|1@0+ (1,0) [0|1] ""  VCU
 SG_ ABSAutnmsBrkReq : 18|1@0+ (1,0) [0|1] ""  VCU
 SG_ HlStrAssActIO : 19|1@0+ (1,0) [0|1] ""  VCU
 SG_ ABSActvProt : 39|1@0+ (1,0) [0|1] ""  VCU
 SG_ BrkSysAutBrkFld : 20|1@0+ (1,0) [0|1] ""  VCU
 SG_ IntBrkAssPreFilReq : 21|1@0+ (1,0) [0|1] "N/A"  VCU
 SG_ BrkSysMalFuncIndOn : 22|1@0+ (1,0) [0|1] ""  VCU
 SG_ IBCPdlStChs : 7|8@0+ (1,0) [0|255] ""  VCU
 SG_ BPDAPS_BkPDrvApPV : 12|1@0+ (1,0) [0|1] ""  VCU
 SG_ BPDAPS_BkPDrvApP : 31|8@0+ (75,0) [0|19125] "kPa"  VCU
 SG_ IBCPdlStARC : 11|4@0+ (1,0) [0|15] ""  VCU
 SG_ BrkFldLvlLwV : 15|1@0+ (1,0) [0|1] ""  VCU
 SG_ AutoBrkngAct : 13|1@0+ (1,0) [0|1] ""  VCU
 SG_ BrkFldLvlLw : 14|1@0+ (1,0) [0|1] ""  VCU

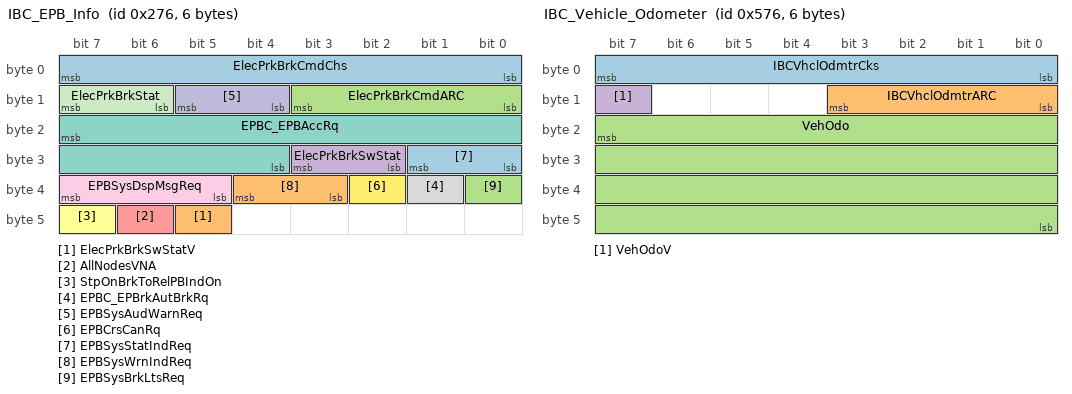
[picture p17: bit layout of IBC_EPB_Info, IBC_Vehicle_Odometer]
BO_ 630 IBC_EPB_Info: 6 IBC
 SG_ ElecPrkBrkCmdChs : 7|8@0+ (1,0) [0|255] ""  VCU
 SG_ ElecPrkBrkSwStatV : 45|1@0+ (1,0) [0|1] ""  VCU
 SG_ ElecPrkBrkCmdARC : 11|4@0+ (1,0) [0|15] ""  VCU
 SG_ ElecPrkBrkSwStat : 27|2@0+ (1,0) [0|3] ""  VCU
 SG_ AllNodesVNA : 46|1@0+ (1,0) [0|1] ""  VCU
 SG_ StpOnBrkToRelPBIndOn : 47|1@0+ (1,0) [0|1] ""  VCU
 SG_ EPBC_EPBAccRq : 23|12@0+ (0.01,-20.48) [-20.48|20.47] "m/s^2"  VCU
 SG_ EPBC_EPBrkAutBrkRq : 33|1@0+ (1,0) [0|1] ""  VCU
 SG_ EPBSysDspMsgReq : 39|3@0+ (1,0) [0|7] ""  VCU
 SG_ EPBSysAudWarnReq : 13|2@0+ (1,0) [0|3] ""  VCU
 SG_ ElecPrkBrkStat : 15|2@0+ (1,0) [0|3] ""  VCU
 SG_ EPBCrsCanRq : 34|1@0+ (1,0) [0|1] ""  VCU
 SG_ EPBSysStatIndReq : 25|2@0+ (1,0) [0|3] ""  VCU
 SG_ EPBSysWrnIndReq : 36|2@0+ (1,0) [0|3] ""  VCU
 SG_ EPBSysBrkLtsReq : 32|1@0+ (1,0) [0|1] ""  VCU

BO_ 1825 Tester_EPS_Request: 8 VCU
 SG_ DgnInf : 7|64@0+ (1,0) [0|1.84467440737096E+019] ""  EPS

BO_ 1502 Tester_IBC_Request: 8 VCU
 SG_ DgnInf : 7|64@0+ (1,0) [0|1.84467440737096E+019] ""  IBC

BO_ 1602 IBC_Tester_Response: 8 IBC
 SG_ DgnInf : 7|64@0+ (1,0) [0|1.84467440737096E+019] ""  VCU

BO_ 300 BCU_Info: 6 VCU
 SG_ WndscrnWshWtrSt : 44|1@0+ (1,0) [0|1] ""  IBC
 SG_ BCUIntLghtSt : 46|2@0+ (1,0) [0|3] ""  IBC
 SG_ DrStOccpncV : 47|1@0+ (1,0) [0|1] ""  IBC
 SG_ DrStOccpnc : 32|1@0+ (1,0) [0|1] ""  IBC
 SG_ BCUIntErrSt : 34|2@0+ (1,0) [0|3] ""  IBC
 SG_ BrkLtsAtv : 35|1@0+ (1,0) [0|1] ""  IBC
 SG_ RrFogLmpsAct : 36|1@0+ (1,0) [0|1] ""  IBC
 SG_ TrnSwAct : 38|2@0+ (1,0) [0|3] ""  IBC
 SG_ OtsdAmbtLtLvlStatV : 39|1@0+ (1,0) [0|1] ""  IBC
 SG_ OtsdAmbtLtLvlStat : 25|2@0+ (1,0) [0|3] ""  IBC
 SG_ MainLghtSw : 27|2@0+ (1,0) [0|3] "N/A"  IBC
 SG_ LowBmAct : 28|1@0+ (1,0) [0|1] ""  IBC
 SG_ HighBmAct : 18|1@0+ (1,0) [0|1] ""  IBC
 SG_ HdlmpBmSelectStat : 20|2@0+ (1,0) [0|3] ""  IBC
 SG_ FlToPsSwAtv : 21|1@0+ (1,0) [0|1] ""  IBC
 SG_ FrFogLmpsAct : 22|1@0+ (1,0) [0|1] ""  IBC
 SG_ AutLghtCtrl : 23|1@0+ (1,0) [0|1] "N/A"  IBC
 SG_ TCSysDisSwAtvV : 12|1@0+ (1,0) [0|1] ""  IBC
 SG_ TCSysDisSwAtv : 13|1@0+ (1,0) [0|1] ""  IBC
 SG_ WSWprAct : 14|1@0+ (1,0) [0|1] ""  IBC
 SG_ WSWshSwAtv : 15|1@0+ (1,0) [0|1] ""  IBC
 SG_ BCUInfCks : 7|8@0+ (1,0) [0|255] ""  IBC
 SG_ VhclLckSt : 29|1@0+ (1,0) [0|1] ""  IBC
 SG_ BCUInfARC : 11|4@0+ (1,0) [0|15] ""  IBC
 SG_ PsSbltAtcV : 30|1@0+ (1,0) [0|1] ""  IBC
 SG_ PsSbltAtc : 31|1@0+ (1,0) [0|1] ""  IBC
 SG_ DrSbltAtcV : 16|1@0+ (1,0) [0|1] ""  IBC
 SG_ DrSbltAtc : 17|1@0+ (1,0) [0|1] ""  IBC

BO_ 1350 BCU_VIN_Digits_2_to_9: 8 VCU
 SG_ VehIdNmDig2_9 : 7|64@0+ (1,0) [0|1.84467440737096E+019] ""  IBC

BO_ 1398 IBC_Vehicle_Odometer: 6 IBC
 SG_ IBCVhclOdmtrCks : 7|8@0+ (1,0) [0|255] ""  EPS,VCU
 SG_ IBCVhclOdmtrARC : 11|4@0+ (1,0) [0|15] ""  EPS,VCU
 SG_ VehOdo : 23|32@0+ (0.015625,0) [0|67108863.984375] "km"  EPS,VCU
 SG_ VehOdoV : 15|1@0+ (1,0) [0|1] ""  EPS,VCU

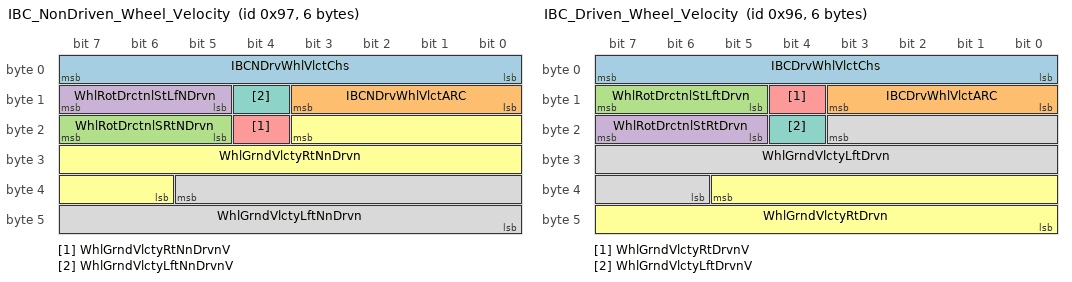
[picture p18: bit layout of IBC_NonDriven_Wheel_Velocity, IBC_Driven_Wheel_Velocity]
BO_ 151 IBC_NonDriven_Wheel_Velocity: 6 IBC
 SG_ IBCNDrvWhlVlctChs : 7|8@0+ (1,0) [0|255] ""  EPS,VCU
 SG_ IBCNDrvWhlVlctARC : 11|4@0+ (1,0) [0|15] ""  EPS,VCU
 SG_ WhlRotDrctnlSRtNDrvn : 23|3@0+ (1,0) [0|7] ""  EPS,VCU
 SG_ WhlRotDrctnlStLfNDrvn : 15|3@0+ (1,0) [0|7] ""  EPS,VCU
 SG_ WhlGrndVlctyRtNnDrvnV : 20|1@0+ (1,0) [0|1] ""  EPS,VCU
 SG_ WhlGrndVlctyRtNnDrvn : 19|14@0+ (0.03125,0) [0|511.96875] "km / h"  EPS,VCU
 SG_ WhlGrndVlctyLftNnDrvnV : 12|1@0+ (1,0) [0|1] ""  EPS,VCU
 SG_ WhlGrndVlctyLftNnDrvn : 37|14@0+ (0.03125,0) [0|511.96875] "km / h"  EPS,VCU

BO_ 1888 Tester_All_ECUs_Request: 8 VCU
 SG_ DgnInf : 7|64@0+ (1,0) [0|1.84467440737096E+019] ""  EPS,IBC

BO_ 1351 BCU_VIN_Digits_10_to_17: 8 VCU
 SG_ VehIdNmDig10_17 : 7|64@0+ (1,0) [0|1.84467440737096E+019] ""  IBC

BO_ 150 IBC_Driven_Wheel_Velocity: 6 IBC
 SG_ IBCDrvWhlVlctChs : 7|8@0+ (1,0) [0|255] ""  EPS,VCU
 SG_ IBCDrvWhlVlctARC : 11|4@0+ (1,0) [0|15] ""  EPS,VCU
 SG_ WhlRotDrctnlStLftDrvn : 15|3@0+ (1,0) [0|7] ""  EPS,VCU
 SG_ WhlRotDrctnlStRtDrvn : 23|3@0+ (1,0) [0|7] ""  EPS,VCU
 SG_ WhlGrndVlctyRtDrvnV : 12|1@0+ (1,0) [0|1] ""  EPS,VCU
 SG_ WhlGrndVlctyRtDrvn : 37|14@0+ (0.03125,0) [0|511.96875] "km / h"  EPS,VCU
 SG_ WhlGrndVlctyLftDrvnV : 20|1@0+ (1,0) [0|1] ""  EPS,VCU
 SG_ WhlGrndVlctyLftDrvn : 19|14@0+ (0.03125,0) [0|511.96875] "km / h"  EPS,VCU

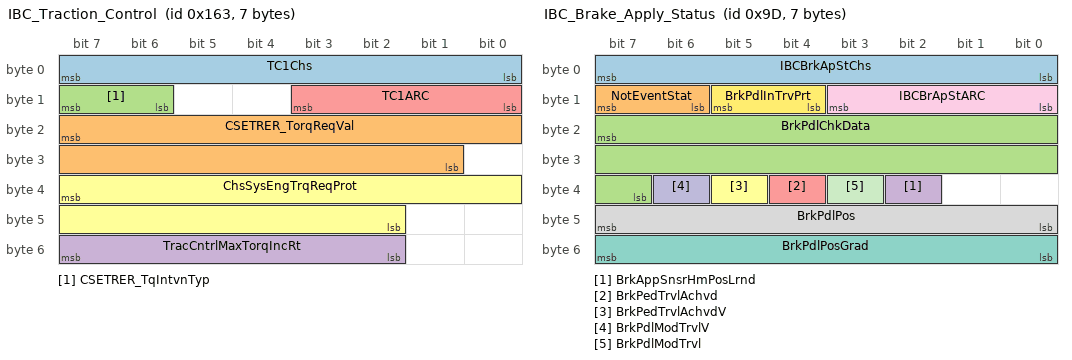
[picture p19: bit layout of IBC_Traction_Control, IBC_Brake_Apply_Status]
BO_ 355 IBC_Traction_Control: 7 IBC
 SG_ TC1Chs : 7|8@0+ (1,0) [0|255] ""  VCU
 SG_ CSETRER_TorqReqVal : 23|15@0+ (1,-16383) [-16383|16384] "Nm"  VCU
 SG_ CSETRER_TqIntvnTyp : 15|2@0+ (1,0) [0|3] ""  VCU
 SG_ TracCntrlMaxTorqIncRt : 55|6@0+ (16,0) [0|1008] "Nm/s"  VCU
 SG_ TC1ARC : 11|4@0+ (1,0) [0|15] ""  VCU
 SG_ ChsSysEngTrqReqProt : 39|14@0+ (1,0) [0|16383] ""  VCU

BO_ 360 IBC_Chassis_Status: 8 IBC
 SG_ EnhDrvMdSwChUseRq : 11|1@0+ (1,0) [0|1] ""  VCU
 SG_ IMUDataMsk : 12|1@0+ (1,0) [0|1] ""  VCU
 SG_ DrvIndpntBrkAppAct : 13|1@0+ (1,0) [0|1] ""  VCU
 SG_ WhlSlpSt : 61|2@0+ (1,0) [0|3] ""  VCU
 SG_ BSTGRReqdGear : 27|4@0+ (1,0) [0|15] ""  VCU
 SG_ BSTGRReqType : 42|2@0+ (1,0) [0|3] ""  VCU
 SG_ VehDynOvrUndrStr : 55|10@0+ (0.5,-256) [-256|255.5] "%"  VCU
 SG_ VSELatAccV : 14|1@0+ (1,0) [0|1] ""  VCU
 SG_ VSELatAcc : 39|12@0+ (0.015625,-32) [-32|31.984375] "m/s^2"  VCU
 SG_ VSEAct : 15|1@0+ (1,0) [0|1] ""  VCU
 SG_ VhDynCntlSysSt : 10|3@0+ (1,0) [0|7] ""  VCU
 SG_ VehDynYawRateV : 0|1@0+ (1,0) [0|1] ""  VCU
 SG_ VehDynYawRate : 23|12@0+ (0.0625,-128) [-128|127.9375] "deg/sec"  VCU
 SG_ TrnsBrkSysCltchRelRqd : 1|1@0+ (1,0) [0|1] ""  VCU
 SG_ TracCntrlSysDrIntnt : 2|1@0+ (1,0) [0|1] ""  VCU
 SG_ VehDynOvrUndrStrV : 3|1@0+ (1,0) [0|1] ""  VCU
 SG_ TCSysEnbld : 4|1@0+ (1,0) [0|1] ""  VCU
 SG_ TCSysAtv : 5|1@0+ (1,0) [0|1] ""  VCU
 SG_ BrkPdlDrvAppPrsDetcdV : 6|1@0+ (1,0) [0|1] ""  VCU
 SG_ BrkPdlDrvAppPrsDetcd : 7|1@0+ (1,0) [0|1] ""  VCU
 SG_ ACCBrkngAct : 59|1@0+ (1,0) [0|1] ""  VCU
 SG_ ABSFld : 40|1@0+ (1,0) [0|1] ""  VCU
 SG_ ABSAtv : 43|1@0+ (1,0) [0|1] ""  VCU

BO_ 350 IBC_ABS_Status: 8 IBC
 SG_ IBCABSStChs : 7|8@0+ (1,0) [0|255] ""  VCU
 SG_ IBCABSStARC : 11|4@0+ (1,0) [0|15] ""  VCU
 SG_ HillDesCtrlRedVehSpIO : 28|1@0+ (1,0) [0|1] ""  VCU
 SG_ EBDFailed : 29|1@0+ (1,0) [0|1] ""  VCU
 SG_ StWhAnVDA : 30|1@0+ (1,0) [0|1] ""  VCU
 SG_ TirePrsLowIO : 31|1@0+ (1,0) [0|1] ""  VCU
 SG_ VaccBoostFailure : 16|1@0+ (1,0) [0|1] ""  VCU
 SG_ VSESysPrs : 17|1@0+ (1,0) [0|1] ""  VCU
 SG_ HalfSysFail : 18|1@0+ (1,0) [0|1] ""  VCU
 SG_ ActVehAccel : 55|12@0+ (0.01,-20.48) [-20.48|20.47] "m/s^2"  VCU
 SG_ ActVehAccelV : 19|1@0+ (1,0) [0|1] ""  VCU
 SG_ BksOvht : 20|1@0+ (1,0) [0|1] ""  VCU
 SG_ TCSysPr : 21|1@0+ (1,0) [0|1] ""  VCU
 SG_ ABSPr : 22|1@0+ (1,0) [0|1] ""  VCU
 SG_ TreInfMonSysRstPrfmd : 23|1@0+ (1,0) [0|1] ""  VCU
 SG_ ABSIO : 27|1@0+ (1,0) [0|1] ""  VCU
 SG_ BrkPadWrnIO : 12|1@0+ (1,0) [0|1] ""  VCU
 SG_ VehStabEnhmntMd : 26|3@0+ (1,0) [0|7] ""  VCU
 SG_ VehStabEnhmntStat : 15|3@0+ (1,0) [0|7] ""  VCU
 SG_ TCSysOpMd : 44|3@0+ (1,0) [0|7] ""  VCU
 SG_ TCSysOpStat : 47|3@0+ (1,0) [0|7] ""  VCU
 SG_ BrkSysVTopSpdLimVal : 39|8@0+ (2,0) [0|510] "km / h"  VCU
 SG_ BrkSysRedBrkTlltlReq : 40|1@0+ (1,0) [0|1] ""  VCU
 SG_ BrkSysBrkLtsReqd : 41|1@0+ (1,0) [0|1] ""  VCU

BO_ 157 IBC_Brake_Apply_Status: 7 IBC
 SG_ IBCBrkApStChs : 7|8@0+ (1,0) [0|255] ""  VCU
 SG_ NotEventStat : 15|2@0+ (1,0) [0|3] ""  VCU
 SG_ BrkPdlChkData : 23|17@0+ (1,0) [0|131071] ""  VCU
 SG_ BrkAppSnsrHmPosLrnd : 34|1@0+ (1,0) [0|1] ""  VCU
 SG_ BrkPedTrvlAchvd : 36|1@0+ (1,0) [0|1] ""  VCU
 SG_ BrkPedTrvlAchvdV : 37|1@0+ (1,0) [0|1] ""  VCU
 SG_ BrkPdlPosGrad : 55|8@0+ (40,-5120) [-5120|5080] "%/s"  VCU
 SG_ BrkPdlPos : 47|8@0+ (0.392157,0) [0|100.000035] "% full"  VCU
 SG_ IBCBrApStARC : 11|4@0+ (1,0) [0|15] ""  VCU
 SG_ BrkPdlModTrvlV : 38|1@0+ (1,0) [0|1] ""  VCU
 SG_ BrkPdlModTrvl : 35|1@0+ (1,0) [0|1] ""  VCU
 SG_ BrkPdlInTrvPrt : 13|2@0+ (1,0) [0|3] ""  VCU

BO_ 1833 EPS_Tester_Response: 8 EPS
 SG_ DgnInf : 7|64@0+ (1,0) [0|1.84467440737096E+019] ""  VCU

CM_ "v3.9";
CM_ BU_ VCU "Vehicle Control Unit";
CM_ BU_ EPS "Electronic Power Steering";
CM_ BU_ IBC "Integrated Brake Control";
CM_ SG_ 99 DM_LDW "Signal to request Lane Departure Warning feature.";
CM_ BO_ 800 "Tire Condition Message 1
Tire Condition Message
NOTE – Multiple instances of this message will be required to transmit data for all tire locations.  When reporting data for multiple tire locations, each successive message, which provides data for ...";
CM_ SG_ 800 ExTirePressSupport "Defines the choice of using the tire pressure (PGN 65268) or Extended Tire Pressure (PGN 64578). The state value '01' indicates the extended tire pressure SPN is used for the pressure data. Any other value indicates the extended tire pressure SPN is ...";
CM_ SG_ 800 TirePressThresholdDetection_13 "Signal indicating the pressure level of the tire.";
CM_ SG_ 800 TirePressThresholdDetection_12 "Signal indicating the pressure level of the tire.";
CM_ SG_ 800 TirePressThresholdDetection_11 "Signal indicating the pressure level of the tire.";
CM_ SG_ 800 TirePressThresholdDetection_10 "Signal indicating the pressure level of the tire.";
CM_ SG_ 800 TirePressThresholdDetection_01 "Signal indicating the pressure level of the tire.";
CM_ SG_ 800 TirePress_33 "Pressure at which air is contained in cavity formed by tire and rim.";
CM_ SG_ 800 TirePress_32 "Pressure at which air is contained in cavity formed by tire and rim.";
CM_ SG_ 800 TirePress_31 "Pressure at which air is contained in cavity formed by tire and rim.";
CM_ SG_ 800 TirePress_30 "Pressure at which air is contained in cavity formed by tire and rim.";
CM_ SG_ 800 TirePress_23 "Pressure at which air is contained in cavity formed by tire and rim.";
CM_ SG_ 800 TirePress_22 "Pressure at which air is contained in cavity formed by tire and rim.";
CM_ SG_ 800 TirePress_21 "Pressure at which air is contained in cavity formed by tire and rim.";
CM_ SG_ 800 TirePress_20 "Pressure at which air is contained in cavity formed by tire and rim.";
CM_ SG_ 800 TirePress_13 "Pressure at which air is contained in cavity formed by tire and rim.";
CM_ SG_ 800 TirePress_12 "Pressure at which air is contained in cavity formed by tire and rim.";
CM_ SG_ 800 TirePress_11 "Pressure at which air is contained in cavity formed by tire and rim.";
CM_ SG_ 800 TirePress_10 "Pressure at which air is contained in cavity formed by tire and rim.";
CM_ SG_ 800 TireAirLeakageRate_33 "The pressure loss rate of a tire.";
CM_ SG_ 800 TireAirLeakageRate_32 "The pressure loss rate of a tire.";
CM_ SG_ 800 TireAirLeakageRate_31 "The pressure loss rate of a tire.";
CM_ SG_ 800 TireAirLeakageRate_30 "The pressure loss rate of a tire.";
CM_ SG_ 800 TireAirLeakageRate_23 "The pressure loss rate of a tire.";
CM_ SG_ 800 TireAirLeakageRate_22 "The pressure loss rate of a tire.";
CM_ SG_ 800 TireAirLeakageRate_21 "The pressure loss rate of a tire.";
CM_ SG_ 800 TireAirLeakageRate_20 "The pressure loss rate of a tire.";
CM_ SG_ 800 TireAirLeakageRate_13 "The pressure loss rate of a tire.";
CM_ SG_ 800 TireAirLeakageRate_12 "The pressure loss rate of a tire.";
CM_ SG_ 800 TireAirLeakageRate_11 "The pressure loss rate of a tire.";
CM_ SG_ 800 TireAirLeakageRate_10 "The pressure loss rate of a tire.";
CM_ SG_ 800 TireAirLeakageRate_01 "The pressure loss rate of a tire.";
CM_ SG_ 800 TireAirLeakageRate_00 "The pressure loss rate of a tire.";
CM_ SG_ 800 CTIWheelSensorStatus_33 "Indicates whether the wheel is being monitored by the CTI controller.";
CM_ SG_ 800 CTIWheelSensorStatus_32 "Indicates whether the wheel is being monitored by the CTI controller.";
CM_ SG_ 800 CTIWheelSensorStatus_31 "Indicates whether the wheel is being monitored by the CTI controller.";
CM_ SG_ 800 CTIWheelSensorStatus_30 "Indicates whether the wheel is being monitored by the CTI controller.";
CM_ SG_ 800 CTIWheelSensorStatus_23 "Indicates whether the wheel is being monitored by the CTI controller.";
CM_ SG_ 800 CTIWheelSensorStatus_22 "Indicates whether the wheel is being monitored by the CTI controller.";
CM_ SG_ 800 CTIWheelSensorStatus_21 "Indicates whether the wheel is being monitored by the CTI controller.";
CM_ SG_ 800 CTIWheelSensorStatus_20 "Indicates whether the wheel is being monitored by the CTI controller.";
CM_ SG_ 800 CTIWheelSensorStatus_13 "Indicates whether the wheel is being monitored by the CTI controller.";
CM_ SG_ 800 CTIWheelSensorStatus_12 "Indicates whether the wheel is being monitored by the CTI controller.";
CM_ SG_ 800 CTIWheelSensorStatus_11 "Indicates whether the wheel is being monitored by the CTI controller.";
CM_ SG_ 800 CTIWheelSensorStatus_10 "Indicates whether the wheel is being monitored by the CTI controller.";
CM_ SG_ 800 CTIWheelSensorStatus_01 "Indicates whether the wheel is being monitored by the CTI controller.";
CM_ SG_ 800 CTIWheelEndElectricalFault_33 "Indicates the status of electrical fault on CTI wheel interface.";
CM_ SG_ 800 CTIWheelEndElectricalFault_32 "Indicates the status of electrical fault on CTI wheel interface.";
CM_ SG_ 800 CTIWheelEndElectricalFault_31 "Indicates the status of electrical fault on CTI wheel interface.";
CM_ SG_ 800 CTIWheelEndElectricalFault_30 "Indicates the status of electrical fault on CTI wheel interface.";
CM_ SG_ 800 CTIWheelEndElectricalFault_23 "Indicates the status of electrical fault on CTI wheel interface.";
CM_ SG_ 800 CTIWheelEndElectricalFault_22 "Indicates the status of electrical fault on CTI wheel interface.";
CM_ SG_ 800 CTIWheelEndElectricalFault_21 "Indicates the status of electrical fault on CTI wheel interface.";
CM_ SG_ 800 CTIWheelEndElectricalFault_20 "Indicates the status of electrical fault on CTI wheel interface.";
CM_ SG_ 800 CTIWheelEndElectricalFault_13 "Indicates the status of electrical fault on CTI wheel interface.";
CM_ SG_ 800 CTIWheelEndElectricalFault_12 "Indicates the status of electrical fault on CTI wheel interface.";
CM_ SG_ 800 CTIWheelEndElectricalFault_11 "Indicates the status of electrical fault on CTI wheel interface.";
CM_ SG_ 800 CTIWheelEndElectricalFault_10 "Indicates the status of electrical fault on CTI wheel interface.";
CM_ SG_ 800 CTIWheelEndElectricalFault_01 "Indicates the status of electrical fault on CTI wheel interface.";
CM_ SG_ 800 CTITireStatus_33 "Indicates the status of the tire.";
CM_ SG_ 800 CTITireStatus_32 "Indicates the status of the tire.";
CM_ SG_ 800 CTITireStatus_31 "Indicates the status of the tire.";
CM_ SG_ 800 CTITireStatus_30 "Indicates the status of the tire.";
CM_ SG_ 800 CTITireStatus_23 "Indicates the status of the tire.";
CM_ SG_ 800 CTITireStatus_22 "Indicates the status of the tire.";
CM_ SG_ 800 CTITireStatus_21 "Indicates the status of the tire.";
CM_ SG_ 800 CTITireStatus_20 "Indicates the status of the tire.";
CM_ SG_ 800 CTITireStatus_13 "Indicates the status of the tire.";
CM_ SG_ 800 CTITireStatus_12 "Indicates the status of the tire.";
CM_ SG_ 800 CTITireStatus_11 "Indicates the status of the tire.";
CM_ SG_ 800 CTITireStatus_10 "Indicates the status of the tire.";
CM_ SG_ 800 CTITireStatus_01 "Indicates the status of the tire.";
CM_ SG_ 800 TireTemp_11 "Temperature at the surface of the tire sidewall.";
CM_ SG_ 800 TireTemp_33 "Temperature at the surface of the tire sidewall.";
CM_ SG_ 800 TireTemp_32 "Temperature at the surface of the tire sidewall.";
CM_ SG_ 800 TireTemp_31 "Temperature at the surface of the tire sidewall.";
CM_ SG_ 800 TireTemp_30 "Temperature at the surface of the tire sidewall.";
CM_ SG_ 800 TireTemp_23 "Temperature at the surface of the tire sidewall.";
CM_ SG_ 800 TireTemp_22 "Temperature at the surface of the tire sidewall.";
CM_ SG_ 800 TireTemp_21 "Temperature at the surface of the tire sidewall.";
CM_ SG_ 800 TireTemp_20 "Temperature at the surface of the tire sidewall.";
CM_ SG_ 800 TireTemp_13 "Temperature at the surface of the tire sidewall.";
CM_ SG_ 800 TireTemp_12 "Temperature at the surface of the tire sidewall.";
CM_ SG_ 800 TireTemp_10 "Temperature at the surface of the tire sidewall.";
CM_ SG_ 800 TireTemp_01 "Temperature at the surface of the tire sidewall.";
CM_ SG_ 800 TireTemp_00 "Temperature at the surface of the tire sidewall.";
CM_ SG_ 800 TirePressThresholdDetection_33 "Signal indicating the pressure level of the tire.";
CM_ SG_ 800 TirePressThresholdDetection_32 "Signal indicating the pressure level of the tire.";
CM_ SG_ 800 TirePressThresholdDetection_31 "Signal indicating the pressure level of the tire.";
CM_ SG_ 800 TirePressThresholdDetection_30 "Signal indicating the pressure level of the tire.";
CM_ SG_ 800 TirePressThresholdDetection_23 "Signal indicating the pressure level of the tire.";
CM_ SG_ 800 TirePressThresholdDetection_22 "Signal indicating the pressure level of the tire.";
CM_ SG_ 800 TirePressThresholdDetection_21 "Signal indicating the pressure level of the tire.";
CM_ SG_ 800 TirePressThresholdDetection_20 "Signal indicating the pressure level of the tire.";
CM_ SG_ 800 TirePressThresholdDetection_00 "Signal indicating the pressure level of the tire.";
CM_ SG_ 800 TirePress_01 "Pressure at which air is contained in cavity formed by tire and rim.";
CM_ SG_ 800 TirePress_00 "Pressure at which air is contained in cavity formed by tire and rim.";
CM_ SG_ 800 CTIWheelSensorStatus_00 "Indicates whether the wheel is being monitored by the CTI controller.";
CM_ SG_ 800 CTIWheelEndElectricalFault_00 "Indicates the status of electrical fault on CTI wheel interface.";
CM_ SG_ 800 CTITireStatus_00 "Indicates the status of the tire.";
CM_ SG_ 800 TireLocation "Identifies which tire is associated with the parametric data in this PGN.
The low order 4 bits represent a position number, counting left to right when facing in the direction of normal vehicle travel (forward).
The high order 4 bits represent a ...";
CM_ BO_ 160 "6443-Power Steering Indication On in this frame not used by GlobalA /JD";
CM_ BO_ 544 "Inverter1 DCDC Information Frame - Present Status";
CM_ SG_ 544 Checksum_220 "Checksum signal for frame";
CM_ SG_ 544 MessageCounter_220 "Message counter signal for frame";
CM_ SG_ 544 DC1_VoltageHV "Voltage at high voltage side";
CM_ SG_ 544 DC1_CurrentLV "Current on low voltage side";
CM_ SG_ 544 DC1_Mode "State DC/DC converter";
CM_ SG_ 544 DC1_CurrentHV "Current at high voltage side";
CM_ SG_ 544 DC1_Temp "Temperature of DCDC";
CM_ SG_ 544 DC1_VoltageLV "Voltage on low voltage side";
CM_ SG_ 357 GlobalRealTimeGSVALID "This signal indicates the status of the GlobalRealTimeGS signal";
CM_ SG_ 357 GlobalRealTimeGS "Rolling time counter in mins";
CM_ SG_ 100 VCUADaRq "In Arrival only values <= 0 m/s^2 are used.";
CM_ SG_ 390 BrkSysAutBrkFld "BrakeSystemAutomaticBrakingFailed";
CM_ SG_ 390 IntBrkAssPreFilReq "IntelligentBrakeAssistPreFillRequest";
CM_ SG_ 300 MainLghtSw "Operator selection for the main lighting switch";
CM_ SG_ 300 AutLghtCtrl "This signal represents if Automatic Lights Control feature is active/inactive";
CM_ SG_ 1350 VehIdNmDig2_9 "Desc: 8 ASCII Characters";
CM_ SG_ 1351 VehIdNmDig10_17 "Desc: 8 ASCII Characters";
CM_ BO_ 360 "Changed for PPEI 3.6";
CM_ SG_ 350 BrkSysRedBrkTlltlReq "Added acc to Björn 0410";
CM_ SG_ 157 BrkPdlModTrvlV "Indicates that the brake pedal position has passed a threshold for brake torque management and some 2 channel Vehicle Dynamics Control systems.";
CM_ SG_ 157 BrkPdlModTrvl "Indicates that the brake pedal position has passed a threshold for brake torque management and some 2 channel Vehicle Dynamics Control systems.";
BA_DEF_  "BusType" STRING ;
BA_DEF_ SG_  "VNSigSLHS_VNReq" ENUM  "No","Yes";
BA_DEF_ SG_  "VNSigSLHSSharedDiagnostic" ENUM  "No","Yes";
BA_DEF_ SG_  "SignalType" STRING ;
BA_DEF_ SG_  "PacketOrder" INT 0 65535;
BA_DEF_ SG_  "SignalLongName" STRING ;
BA_DEF_ SG_  "GenSigStartValue" INT 0 65535;
BA_DEF_ SG_  "VNSigAllNodes" ENUM  "No","Yes";
BA_DEF_ SG_  "GenSigSendType" ENUM  "cyclicX","spontanX","NotUsed","OnChange","NotUsed","NotUsed","NotUsed","NoSigSendType";
BA_DEF_ SG_  "GenSigSendOnInit" ENUM  "Not Initialized","Application","Handler";
BA_DEF_ SG_  "SigType" ENUM  "Default","Range","RangeSigned","ASCII","Discrete","Control","ReferencePGN","DTC","StringDelimiter","StringLength","StringLengthControl","MessageCounter","MessageChecksum";
BA_DEF_ SG_  "SPN" INT 0 524287;
BA_DEF_ BO_  "GenMsgILSupport" ENUM  "No","Yes";
BA_DEF_ BO_  "Prio" INT 0 7;
BA_DEF_ BO_  "MessageSubnet" ENUM  "Chassis";
BA_DEF_ BO_  "DiagState" ENUM  "No","Yes";
BA_DEF_ BO_  "GenMsgDelayTime" INT 0 100000;
BA_DEF_ BO_  "GenMsgCycleTime" INT 0 100000;
BA_DEF_ BO_  "GenMsgSendType" ENUM  "Cyclic","NotUsed","NotUsed","NotUsed","NotUsed","NotUsed","NotUsed","NotUsed","NoMsgSendType";
BA_DEF_ BO_  "DiagResponse" ENUM  "No","Yes";
BA_DEF_ BO_  "DiagRequest" ENUM  "No","Yes";
BA_DEF_ BO_  "NmMessage" ENUM  "No","Yes";
BA_DEF_ BU_  "MessageManagerUsed" ENUM  "No","Yes";
BA_DEF_ BU_  "NmNode" ENUM  "No","Yes";
BA_DEF_ BU_  "ILUsed" ENUM  "No","Yes";
BA_DEF_ BU_  "VNECUSLHS_VNReq" ENUM  "None","Activator","Remoted","Activator and Remoted","Shared Local";
BA_DEF_ BU_  "VNECUSLHSSharedDiagnostic" ENUM  "None","Activator","Remoted","Activator and Remoted","Shared Local";
BA_DEF_ BU_  "D22_FRdDataByPID" ENUM  "No","Yes";
BA_DEF_ BU_  "D22_N12" ENUM  "No","Yes";
BA_DEF_ BU_  "D22_ReqType" ENUM  "Functional","Physical","Both";
BA_DEF_ BU_  "D2D_ReqType" ENUM  "Functional","Physical","Both";
BA_DEF_ BU_  "DAE_ReqType" ENUM  "Functional","Physical","Both";
BA_DEF_ BU_  "DAE_NE3" ENUM  "No","Yes";
BA_DEF_ BU_  "DAE_N78" ENUM  "No","Yes";
BA_DEF_ BU_  "DAE_N31" ENUM  "No","Yes";
BA_DEF_ BU_  "DAE_N12" ENUM  "No","Yes";
BA_DEF_ BU_  "DAE_FDevCtrl" ENUM  "No","Yes","vector_leerstring";
BA_DEF_ BU_  "DAA_ReqType" ENUM  "Functional","Physical","Both";
BA_DEF_ BU_  "DAA_N81" ENUM  "No","Yes";
BA_DEF_ BU_  "DAA_N78" ENUM  "No","Yes";
BA_DEF_ BU_  "DAA_N31" ENUM  "No","Yes";
BA_DEF_ BU_  "DAA_N12" ENUM  "No","Yes";
BA_DEF_ BU_  "DAA_L04_FastRate" ENUM  "No","Yes";
BA_DEF_ BU_  "DAA_L03_MedRate" ENUM  "No","Yes";
BA_DEF_ BU_  "DAA_L02_SlowRate" ENUM  "No","Yes";
BA_DEF_ BU_  "DAA_L01_SndOneRsp" ENUM  "No","Yes";
BA_DEF_ BU_  "DAA_L00_StopSnd" ENUM  "No","Yes";
BA_DEF_ BU_  "DAA_FRdDPID" ENUM  "No","Yes","vector_leerstring";
BA_DEF_ BU_  "DA9_ReqType" ENUM  "Functional","Physical","Both";
BA_DEF_ BU_  "DA9_N78" ENUM  "No","Yes";
BA_DEF_ BU_  "DA9_N31" ENUM  "No","Yes";
BA_DEF_ BU_  "DA9_N12" ENUM  "No","Yes";
BA_DEF_ BU_  "DA9_L82_SndChgDTC" ENUM  "No","Yes";
BA_DEF_ BU_  "DA9_L80_RdStatDTCbyNum" ENUM  "No","Yes";
BA_DEF_ BU_  "DA9_FRdDiagInfo" ENUM  "No","Yes","vector_leerstring";
BA_DEF_ BU_  "DA5_ReqType" ENUM  "Functional","Physical","Both";
BA_DEF_ BU_  "DA5_N22" ENUM  "No","Yes";
BA_DEF_ BU_  "DA5_N12" ENUM  "No","Yes";
BA_DEF_ BU_  "DA5_L03_EnabProgMode" ENUM  "No","Yes";
BA_DEF_ BU_  "DA5_L01_ReqProgMode" ENUM  "No","Yes";
BA_DEF_ BU_  "DA5_FProgMode" ENUM  "No","Yes","vector_leerstring";
BA_DEF_ BU_  "DA2_ReqType" ENUM  "Functional","Physical","Both";
BA_DEF_ BU_  "DA2_N12" ENUM  "No","Yes";
BA_DEF_ BU_  "DA2_FRptPrgStat" ENUM  "No","Yes","vector_leerstring";
BA_DEF_ BU_  "D3E_ReqType" ENUM  "Functional","Physical","Both";
BA_DEF_ BU_  "D3E_N12" ENUM  "No","Yes";
BA_DEF_ BU_  "D3E_FTstrPres" ENUM  "No","Yes","vector_leerstring";
BA_DEF_ BU_  "D3B_ReqType" ENUM  "Functional","Physical","Both";
BA_DEF_ BU_  "D3B_N78" ENUM  "No","Yes";
BA_DEF_ BU_  "D3B_N31" ENUM  "No","Yes";
BA_DEF_ BU_  "D3B_N22" ENUM  "No","Yes";
BA_DEF_ BU_  "D3B_N12" ENUM  "No","Yes";
BA_DEF_ BU_  "D3B_FWrtBlk" ENUM  "No","Yes","vector_leerstring";
BA_DEF_ BU_  "D36_ReqType" ENUM  "Functional","Physical","Both";
BA_DEF_ BU_  "D36_N85" ENUM  "No","Yes";
BA_DEF_ BU_  "D36_N83" ENUM  "No","Yes";
BA_DEF_ BU_  "D36_N78" ENUM  "No","Yes";
BA_DEF_ BU_  "D36_N31" ENUM  "No","Yes";
BA_DEF_ BU_  "D36_N22" ENUM  "No","Yes";
BA_DEF_ BU_  "D36_N12" ENUM  "No","Yes";
BA_DEF_ BU_  "D36_L80_DwnldExec" ENUM  "No","Yes";
BA_DEF_ BU_  "D36_L00_DownLoad" ENUM  "No","Yes";
BA_DEF_ BU_  "D36_FXfrData" ENUM  "No","Yes","vector_leerstring";
BA_DEF_ BU_  "D34_ReqType" ENUM  "Functional","Physical","Both";
BA_DEF_ BU_  "D34_N99" ENUM  "No","Yes";
BA_DEF_ BU_  "D34_N78" ENUM  "No","Yes";
BA_DEF_ BU_  "D34_N22" ENUM  "No","Yes";
BA_DEF_ BU_  "D34_N12" ENUM  "No","Yes";
BA_DEF_ BU_  "D34_FReqDwnld" ENUM  "No","Yes";
BA_DEF_ BU_  "D2C_ReqType" ENUM  "Functional","Physical","Both";
BA_DEF_ BU_  "D2C_N78" ENUM  "No","Yes";
BA_DEF_ BU_  "D2C_N31" ENUM  "No","Yes";
BA_DEF_ BU_  "D2C_N12" ENUM  "No","Yes";
BA_DEF_ BU_  "D2C_FDynMsg" ENUM  "No","Yes","vector_leerstring";
BA_DEF_ BU_  "D28_ReqType" ENUM  "Functional","Physical","Both";
BA_DEF_ BU_  "D28_N22" ENUM  "No","Yes";
BA_DEF_ BU_  "D28_N12" ENUM  "No","Yes";
BA_DEF_ BU_  "D28_FDisNormComm" ENUM  "No","Yes","vector_leerstring";
BA_DEF_ BU_  "D27_ReqType" ENUM  "Functional","Physical","Both";
BA_DEF_ BU_  "D27_N78" ENUM  "No","Yes";
BA_DEF_ BU_  "D27_N37" ENUM  "No","Yes";
BA_DEF_ BU_  "D27_N36" ENUM  "No","Yes";
BA_DEF_ BU_  "D27_N35" ENUM  "No","Yes";
BA_DEF_ BU_  "D27_N22" ENUM  "No","Yes";
BA_DEF_ BU_  "D27_N12" ENUM  "No","Yes";
BA_DEF_ BU_  "D27_L04_DevCtrlSeedKey" ENUM  "No","Yes";
BA_DEF_ BU_  "D27_L03_CtrlReqSeed" ENUM  "No","Yes";
BA_DEF_ BU_  "D27_L02_SndKey" ENUM  "No","Yes";
BA_DEF_ BU_  "D27_L01_ReqSeed" ENUM  "No","Yes";
BA_DEF_ BU_  "D27_FSecAcc" ENUM  "No","Yes","vector_leerstring";
BA_DEF_ BU_  "D23_ReqType" ENUM  "Functional","Physical","Both";
BA_DEF_ BU_  "D23_N31" ENUM  "No","Yes";
BA_DEF_ BU_  "D23_N12" ENUM  "No","Yes";
BA_DEF_ BU_  "D23_FRdMemAddr" ENUM  "No","Yes","vector_leerstring";
BA_DEF_ BU_  "D20_ReqType" ENUM  "Functional","Physical","Both";
BA_DEF_ BU_  "D20_N12" ENUM  "No","Yes";
BA_DEF_ BU_  "D20_FRtnNormComm" ENUM  "No","Yes","vector_leerstring";
BA_DEF_ BU_  "D1A_ReqType" ENUM  "Functional","Physical","Both";
BA_DEF_ BU_  "D1A_N78" ENUM  "No","Yes";
BA_DEF_ BU_  "D1A_N31" ENUM  "No","Yes";
BA_DEF_ BU_  "D1A_N22" ENUM  "No","Yes";
BA_DEF_ BU_  "D1A_N12" ENUM  "No","Yes";
BA_DEF_ BU_  "D1A_FRdDataID" ENUM  "No","Yes","vector_leerstring";
BA_DEF_ BU_  "D12_ReqType" ENUM  "Functional","Physical","Both";
BA_DEF_ BU_  "D12_N78" ENUM  "No","Yes";
BA_DEF_ BU_  "D12_N31" ENUM  "No","Yes";
BA_DEF_ BU_  "D12_N12" ENUM  "No","Yes";
BA_DEF_ BU_  "D12_L02_RdFRcdParam" ENUM  "No","Yes";
BA_DEF_ BU_  "D12_L01_RdFRcdData" ENUM  "No","Yes";
BA_DEF_ BU_  "D12_FRdFailRec" ENUM  "No","Yes","vector_leerstring";
BA_DEF_ BU_  "D10_ReqType" ENUM  "Functional","Physical ","Both";
BA_DEF_ BU_  "D10_N22" ENUM  "No","Yes","vector_leerstring";
BA_DEF_ BU_  "D10_N12" ENUM  "No","Yes","vector_leerstring";
BA_DEF_ BU_  "D10_L03_DTCsDurDevCtrl" ENUM  "No","Yes","vector_leerstring";
BA_DEF_ BU_  "D10_L02_DisAllDTCs" ENUM  "No","Yes","vector_leerstring";
BA_DEF_ BU_  "D10_FInitDiagOp" ENUM  "No","Yes","vector_leerstring";
BA_DEF_ BU_  "D04_ReqType" ENUM  "Functional","Physical","Both","vector_leerstring";
BA_DEF_ BU_  "D04_N22" ENUM  "No","Yes","vector_leerstring";
BA_DEF_ BU_  "D04_N12" ENUM  "No","Yes","vector_leerstring";
BA_DEF_ BU_  "D04_FClrDTC" ENUM  "No","Yes","vector_leerstring";
BA_DEF_  "SyncJumpWidthMax" INT 0 255;
BA_DEF_  "SyncJumpWidthMin" INT 0 255;
BA_DEF_  "SamplePointMax" FLOAT 0 100;
BA_DEF_  "SamplePointMin" FLOAT 0 100;
BA_DEF_  "Baudrate" INT 0 1000000;
BA_DEF_  "VehicleArchitecture" STRING ;
BA_DEF_  "VN_SLHS_VNReq" INT 0 255;
BA_DEF_  "VN_SLHSSharedDiagnostic" INT 0 255;
BA_DEF_  "VersionNumber" INT 0 65535;
BA_DEF_  "NmMessageCount" INT 0 32;
BA_DEF_  "NmBaseAddress" HEX 0 2032;
BA_DEF_  "NetworkType" STRING ;
BA_DEF_  "BusWakeUpDelay" INT 0 65535;
BA_DEF_  "BusOffRecoveryTime" INT 0 65535;
BA_DEF_  "NodeStatusMsgID" HEX 0 536870911;
BA_DEF_  "NodeStatusMsgCycleTime" INT 0 65535;
BA_DEF_  "NodeStatusMsgTimeoutTime" INT 0 65535;
BA_DEF_  "VersionWeek" INT 0 255;
BA_DEF_  "VersionYear" INT 0 255;
BA_DEF_  "VN_AllNodes" INT 0 255;
BA_DEF_  "Manufacturer" ENUM  "Arrival";
BA_DEF_  "NmType" STRING ;
BA_DEF_REL_ BU_SG_REL_  "GenSigSuprvRespComment" STRING "";
BA_DEF_REL_ BU_SG_REL_  "GenSigVBitRespComment" STRING "";
BA_DEF_REL_ BU_SG_REL_  "GenSigVDAFailComment" STRING "";
BA_DEF_REL_ BU_SG_REL_  "GenSigSuprvResp" ENUM  "None","Notify App","Substitute Default";
BA_DEF_REL_ BU_SG_REL_  "GenSigTimeoutMsg" HEX -2147483648 268435455;
BA_DEF_REL_ BU_SG_REL_  "GenSigTimeoutTime" INT 0 15000;
BA_DEF_DEF_  "BusType" "";
BA_DEF_DEF_  "VNSigSLHS_VNReq" "No";
BA_DEF_DEF_  "VNSigSLHSSharedDiagnostic" "No";
BA_DEF_DEF_  "SignalType" "";
BA_DEF_DEF_  "PacketOrder" 0;
BA_DEF_DEF_  "SignalLongName" "";
BA_DEF_DEF_  "GenSigStartValue" 0;
BA_DEF_DEF_  "VNSigAllNodes" "No";
BA_DEF_DEF_  "GenSigSendType" "NoSigSendType";
BA_DEF_DEF_  "GenSigSendOnInit" "Not Initialized";
BA_DEF_DEF_  "SigType" "";
BA_DEF_DEF_  "SPN" 0;
BA_DEF_DEF_  "GenMsgILSupport" "Yes";
BA_DEF_DEF_  "Prio" 4;
BA_DEF_DEF_  "MessageSubnet" "Chassis";
BA_DEF_DEF_  "DiagState" "No";
BA_DEF_DEF_  "GenMsgDelayTime" 0;
BA_DEF_DEF_  "GenMsgCycleTime" 0;
BA_DEF_DEF_  "GenMsgSendType" "NoMsgSendType";
BA_DEF_DEF_  "DiagResponse" "No";
BA_DEF_DEF_  "DiagRequest" "No";
BA_DEF_DEF_  "NmMessage" "No";
BA_DEF_DEF_  "MessageManagerUsed" "Yes";
BA_DEF_DEF_  "NmNode" "Yes";
BA_DEF_DEF_  "ILUsed" "Yes";
BA_DEF_DEF_  "VNECUSLHS_VNReq" "None";
BA_DEF_DEF_  "VNECUSLHSSharedDiagnostic" "None";
BA_DEF_DEF_  "D22_FRdDataByPID" "No";
BA_DEF_DEF_  "D22_N12" "No";
BA_DEF_DEF_  "D22_ReqType" "Both";
BA_DEF_DEF_  "D2D_ReqType" "Both";
BA_DEF_DEF_  "DAE_ReqType" "Both";
BA_DEF_DEF_  "DAE_NE3" "No";
BA_DEF_DEF_  "DAE_N78" "No";
BA_DEF_DEF_  "DAE_N31" "No";
BA_DEF_DEF_  "DAE_N12" "No";
BA_DEF_DEF_  "DAE_FDevCtrl" "No";
BA_DEF_DEF_  "DAA_ReqType" "Both";
BA_DEF_DEF_  "DAA_N81" "No";
BA_DEF_DEF_  "DAA_N78" "No";
BA_DEF_DEF_  "DAA_N31" "No";
BA_DEF_DEF_  "DAA_N12" "No";
BA_DEF_DEF_  "DAA_L04_FastRate" "No";
BA_DEF_DEF_  "DAA_L03_MedRate" "No";
BA_DEF_DEF_  "DAA_L02_SlowRate" "No";
BA_DEF_DEF_  "DAA_L01_SndOneRsp" "No";
BA_DEF_DEF_  "DAA_L00_StopSnd" "No";
BA_DEF_DEF_  "DAA_FRdDPID" "No";
BA_DEF_DEF_  "DA9_ReqType" "Both";
BA_DEF_DEF_  "DA9_N78" "No";
BA_DEF_DEF_  "DA9_N31" "No";
BA_DEF_DEF_  "DA9_N12" "No";
BA_DEF_DEF_  "DA9_L82_SndChgDTC" "No";
BA_DEF_DEF_  "DA9_L80_RdStatDTCbyNum" "No";
BA_DEF_DEF_  "DA9_FRdDiagInfo" "Yes";
BA_DEF_DEF_  "DA5_ReqType" "Both";
BA_DEF_DEF_  "DA5_N22" "No";
BA_DEF_DEF_  "DA5_N12" "No";
BA_DEF_DEF_  "DA5_L03_EnabProgMode" "No";
BA_DEF_DEF_  "DA5_L01_ReqProgMode" "No";
BA_DEF_DEF_  "DA5_FProgMode" "Yes";
BA_DEF_DEF_  "DA2_ReqType" "Both";
BA_DEF_DEF_  "DA2_N12" "No";
BA_DEF_DEF_  "DA2_FRptPrgStat" "Yes";
BA_DEF_DEF_  "D3E_ReqType" "Both";
BA_DEF_DEF_  "D3E_N12" "No";
BA_DEF_DEF_  "D3E_FTstrPres" "Yes";
BA_DEF_DEF_  "D3B_ReqType" "Both";
BA_DEF_DEF_  "D3B_N78" "No";
BA_DEF_DEF_  "D3B_N31" "No";
BA_DEF_DEF_  "D3B_N22" "No";
BA_DEF_DEF_  "D3B_N12" "No";
BA_DEF_DEF_  "D3B_FWrtBlk" "No";
BA_DEF_DEF_  "D36_ReqType" "Both";
BA_DEF_DEF_  "D36_N85" "No";
BA_DEF_DEF_  "D36_N83" "No";
BA_DEF_DEF_  "D36_N78" "No";
BA_DEF_DEF_  "D36_N31" "No";
BA_DEF_DEF_  "D36_N22" "No";
BA_DEF_DEF_  "D36_N12" "No";
BA_DEF_DEF_  "D36_L80_DwnldExec" "No";
BA_DEF_DEF_  "D36_L00_DownLoad" "No";
BA_DEF_DEF_  "D36_FXfrData" "Yes";
BA_DEF_DEF_  "D34_ReqType" "Both";
BA_DEF_DEF_  "D34_N99" "No";
BA_DEF_DEF_  "D34_N78" "No";
BA_DEF_DEF_  "D34_N22" "No";
BA_DEF_DEF_  "D34_N12" "No";
BA_DEF_DEF_  "D34_FReqDwnld" "Yes";
BA_DEF_DEF_  "D2C_ReqType" "Both";
BA_DEF_DEF_  "D2C_N78" "No";
BA_DEF_DEF_  "D2C_N31" "No";
BA_DEF_DEF_  "D2C_N12" "No";
BA_DEF_DEF_  "D2C_FDynMsg" "No";
BA_DEF_DEF_  "D28_ReqType" "Both";
BA_DEF_DEF_  "D28_N22" "No";
BA_DEF_DEF_  "D28_N12" "No";
BA_DEF_DEF_  "D28_FDisNormComm" "Yes";
BA_DEF_DEF_  "D27_ReqType" "Both";
BA_DEF_DEF_  "D27_N78" "No";
BA_DEF_DEF_  "D27_N37" "No";
BA_DEF_DEF_  "D27_N36" "No";
BA_DEF_DEF_  "D27_N35" "No";
BA_DEF_DEF_  "D27_N22" "No";
BA_DEF_DEF_  "D27_N12" "No";
BA_DEF_DEF_  "D27_L04_DevCtrlSeedKey" "No";
BA_DEF_DEF_  "D27_L03_CtrlReqSeed" "No";
BA_DEF_DEF_  "D27_L02_SndKey" "No";
BA_DEF_DEF_  "D27_L01_ReqSeed" "No";
BA_DEF_DEF_  "D27_FSecAcc" "No";
BA_DEF_DEF_  "D23_ReqType" "Both";
BA_DEF_DEF_  "D23_N31" "No";
BA_DEF_DEF_  "D23_N12" "No";
BA_DEF_DEF_  "D23_FRdMemAddr" "No";
BA_DEF_DEF_  "D20_ReqType" "Both";
BA_DEF_DEF_  "D20_N12" "No";
BA_DEF_DEF_  "D20_FRtnNormComm" "Yes";
BA_DEF_DEF_  "D1A_ReqType" "Both";
BA_DEF_DEF_  "D1A_N78" "No";
BA_DEF_DEF_  "D1A_N31" "No";
BA_DEF_DEF_  "D1A_N22" "No";
BA_DEF_DEF_  "D1A_N12" "No";
BA_DEF_DEF_  "D1A_FRdDataID" "Yes";
BA_DEF_DEF_  "D12_ReqType" "Both";
BA_DEF_DEF_  "D12_N78" "No";
BA_DEF_DEF_  "D12_N31" "No";
BA_DEF_DEF_  "D12_N12" "No";
BA_DEF_DEF_  "D12_L02_RdFRcdParam" "No";
BA_DEF_DEF_  "D12_L01_RdFRcdData" "No";
BA_DEF_DEF_  "D12_FRdFailRec" "No";
BA_DEF_DEF_  "D10_ReqType" "Both";
BA_DEF_DEF_  "D10_N22" "No";
BA_DEF_DEF_  "D10_N12" "No";
BA_DEF_DEF_  "D10_L03_DTCsDurDevCtrl" "No";
BA_DEF_DEF_  "D10_L02_DisAllDTCs" "No";
BA_DEF_DEF_  "D10_FInitDiagOp" "Yes";
BA_DEF_DEF_  "D04_ReqType" "Both";
BA_DEF_DEF_  "D04_N22" "No";
BA_DEF_DEF_  "D04_N12" "No";
BA_DEF_DEF_  "D04_FClrDTC" "Yes";
BA_DEF_DEF_  "SyncJumpWidthMax" 0;
BA_DEF_DEF_  "SyncJumpWidthMin" 0;
BA_DEF_DEF_  "SamplePointMax" 0;
BA_DEF_DEF_  "SamplePointMin" 0;
BA_DEF_DEF_  "Baudrate" 0;
BA_DEF_DEF_  "VehicleArchitecture" "";
BA_DEF_DEF_  "VN_SLHS_VNReq" 2;
BA_DEF_DEF_  "VN_SLHSSharedDiagnostic" 0;
BA_DEF_DEF_  "VersionNumber" 0;
BA_DEF_DEF_  "NmMessageCount" 32;
BA_DEF_DEF_  "NmBaseAddress" 1568;
BA_DEF_DEF_  "NetworkType" "";
BA_DEF_DEF_  "BusWakeUpDelay" 100;
BA_DEF_DEF_  "BusOffRecoveryTime" 0;
BA_DEF_DEF_  "NodeStatusMsgID" 268427264;
BA_DEF_DEF_  "NodeStatusMsgCycleTime" 1200;
BA_DEF_DEF_  "NodeStatusMsgTimeoutTime" 0;
BA_DEF_DEF_  "VersionWeek" 0;
BA_DEF_DEF_  "VersionYear" 0;
BA_DEF_DEF_  "VN_AllNodes" 1;
BA_DEF_DEF_  "Manufacturer" "Arrival";
BA_DEF_DEF_  "NmType" "";
BA_DEF_DEF_REL_ "GenSigSuprvRespComment" "";
BA_DEF_DEF_REL_ "GenSigVBitRespComment" "";
BA_DEF_DEF_REL_ "GenSigVDAFailComment" "";
BA_DEF_DEF_REL_ "GenSigSuprvResp" "None";
BA_DEF_DEF_REL_ "GenSigTimeoutMsg" 0;
BA_DEF_DEF_REL_ "GenSigTimeoutTime" 0;
BA_ "VersionNumber" 32;
BA_ "SyncJumpWidthMax" 4;
BA_ "SyncJumpWidthMin" 2;
BA_ "SamplePointMax" 82;
BA_ "SamplePointMin" 78;
BA_ "Baudrate" 500000;
BA_ "VehicleArchitecture" "Mk2";
BA_ "NmMessageCount" 16;
BA_ "NmBaseAddress" 1536;
BA_ "NetworkType" "Chassis";
BA_ "BusOffRecoveryTime" 160;
BA_ "NodeStatusMsgID" 0;
BA_ "BusType" "CAN";
BA_ "NmType" "0";
BA_ "VersionWeek" 21;
BA_ "VersionYear" 19;
BA_ "VNECUSLHS_VNReq" BU_ VCU 4;
BA_ "VNECUSLHSSharedDiagnostic" BU_ VCU 4;
BA_ "VNECUSLHS_VNReq" BU_ EPS 4;
BA_ "VNECUSLHSSharedDiagnostic" BU_ EPS 4;
BA_ "VNECUSLHS_VNReq" BU_ IBC 4;
BA_ "VNECUSLHSSharedDiagnostic" BU_ IBC 4;
BA_ "D22_FRdDataByPID" BU_ IBC 1;
BA_ "D22_N12" BU_ IBC 1;
BA_ "DAE_NE3" BU_ IBC 1;
BA_ "DAE_N78" BU_ IBC 1;
BA_ "DAE_N31" BU_ IBC 1;
BA_ "DAE_N12" BU_ IBC 1;
BA_ "DAE_FDevCtrl" BU_ IBC 1;
BA_ "DAA_N81" BU_ IBC 1;
BA_ "DAA_N78" BU_ IBC 1;
BA_ "DAA_N31" BU_ IBC 1;
BA_ "DAA_N12" BU_ IBC 1;
BA_ "DAA_L04_FastRate" BU_ IBC 1;
BA_ "DAA_L03_MedRate" BU_ IBC 1;
BA_ "DAA_L02_SlowRate" BU_ IBC 1;
BA_ "DAA_L01_SndOneRsp" BU_ IBC 1;
BA_ "DAA_L00_StopSnd" BU_ IBC 1;
BA_ "DAA_FRdDPID" BU_ IBC 1;
BA_ "DA9_N78" BU_ IBC 1;
BA_ "DA9_N31" BU_ IBC 1;
BA_ "DA9_N12" BU_ IBC 1;
BA_ "DA9_L82_SndChgDTC" BU_ IBC 1;
BA_ "DA9_L80_RdStatDTCbyNum" BU_ IBC 1;
BA_ "DA5_N22" BU_ IBC 1;
BA_ "DA5_N12" BU_ IBC 1;
BA_ "DA5_L03_EnabProgMode" BU_ IBC 1;
BA_ "DA5_L01_ReqProgMode" BU_ IBC 1;
BA_ "DA2_N12" BU_ IBC 1;
BA_ "D3E_N12" BU_ IBC 1;
BA_ "D3B_N78" BU_ IBC 1;
BA_ "D3B_N31" BU_ IBC 1;
BA_ "D3B_N22" BU_ IBC 1;
BA_ "D3B_N12" BU_ IBC 1;
BA_ "D3B_FWrtBlk" BU_ IBC 1;
BA_ "D36_N85" BU_ IBC 1;
BA_ "D36_N83" BU_ IBC 1;
BA_ "D36_N78" BU_ IBC 1;
BA_ "D36_N31" BU_ IBC 1;
BA_ "D36_N22" BU_ IBC 1;
BA_ "D36_N12" BU_ IBC 1;
BA_ "D36_L80_DwnldExec" BU_ IBC 1;
BA_ "D36_L00_DownLoad" BU_ IBC 1;
BA_ "D34_N99" BU_ IBC 1;
BA_ "D34_N78" BU_ IBC 1;
BA_ "D34_N22" BU_ IBC 1;
BA_ "D34_N12" BU_ IBC 1;
BA_ "D2C_N78" BU_ IBC 1;
BA_ "D2C_N31" BU_ IBC 1;
BA_ "D2C_N12" BU_ IBC 1;
BA_ "D2C_FDynMsg" BU_ IBC 1;
BA_ "D28_N22" BU_ IBC 1;
BA_ "D28_N12" BU_ IBC 1;
BA_ "D27_N78" BU_ IBC 1;
BA_ "D27_N37" BU_ IBC 1;
BA_ "D27_N36" BU_ IBC 1;
BA_ "D27_N35" BU_ IBC 1;
BA_ "D27_N22" BU_ IBC 1;
BA_ "D27_N12" BU_ IBC 1;
BA_ "D27_L04_DevCtrlSeedKey" BU_ IBC 1;
BA_ "D27_L03_CtrlReqSeed" BU_ IBC 1;
BA_ "D27_L02_SndKey" BU_ IBC 1;
BA_ "D27_L01_ReqSeed" BU_ IBC 1;
BA_ "D27_FSecAcc" BU_ IBC 1;
BA_ "D23_N31" BU_ IBC 1;
BA_ "D23_N12" BU_ IBC 1;
BA_ "D23_FRdMemAddr" BU_ IBC 1;
BA_ "D20_N12" BU_ IBC 1;
BA_ "D1A_N78" BU_ IBC 1;
BA_ "D1A_N31" BU_ IBC 1;
BA_ "D1A_N22" BU_ IBC 1;
BA_ "D1A_N12" BU_ IBC 1;
BA_ "D12_N78" BU_ IBC 1;
BA_ "D12_N31" BU_ IBC 1;
BA_ "D12_N12" BU_ IBC 1;
BA_ "D12_L02_RdFRcdParam" BU_ IBC 1;
BA_ "D12_L01_RdFRcdData" BU_ IBC 1;
BA_ "D12_FRdFailRec" BU_ IBC 1;
BA_ "D10_N22" BU_ IBC 1;
BA_ "D10_N12" BU_ IBC 1;
BA_ "D10_L03_DTCsDurDevCtrl" BU_ IBC 1;
BA_ "D10_L02_DisAllDTCs" BU_ IBC 1;
BA_ "D04_N22" BU_ IBC 1;
BA_ "D04_N12" BU_ IBC 1;
BA_ "Prio" BO_ 168 0;
BA_ "GenMsgCycleTime" BO_ 168 20;
BA_ "Prio" BO_ 177 0;
BA_ "GenMsgCycleTime" BO_ 177 50;
BA_ "GenMsgSendType" BO_ 177 0;
BA_ "GenMsgSendType" BO_ 766 0;
BA_ "GenMsgCycleTime" BO_ 766 10;
BA_ "Prio" BO_ 766 0;
BA_ "Prio" BO_ 162 0;
BA_ "GenMsgCycleTime" BO_ 162 10;
BA_ "GenMsgSendType" BO_ 162 0;
BA_ "Prio" BO_ 107 0;
BA_ "GenMsgCycleTime" BO_ 107 10;
BA_ "GenMsgSendType" BO_ 107 0;
BA_ "Prio" BO_ 99 0;
BA_ "GenMsgCycleTime" BO_ 99 10;
BA_ "GenMsgSendType" BO_ 99 0;
BA_ "GenMsgSendType" BO_ 101 0;
BA_ "GenMsgCycleTime" BO_ 101 10;
BA_ "Prio" BO_ 101 0;
BA_ "Prio" BO_ 800 0;
BA_ "GenMsgCycleTime" BO_ 800 10;
BA_ "GenMsgSendType" BO_ 800 0;
BA_ "GenMsgILSupport" BO_ 1985 0;
BA_ "Prio" BO_ 1985 0;
BA_ "GenMsgDelayTime" BO_ 1985 20;
BA_ "GenMsgCycleTime" BO_ 1985 100;
BA_ "GenMsgSendType" BO_ 1985 0;
BA_ "Prio" BO_ 2001 0;
BA_ "GenMsgILSupport" BO_ 2001 0;
BA_ "GenMsgDelayTime" BO_ 2001 20;
BA_ "GenMsgCycleTime" BO_ 2001 100;
BA_ "GenMsgSendType" BO_ 2001 0;
BA_ "GenMsgSendType" BO_ 160 0;
BA_ "GenMsgCycleTime" BO_ 160 10;
BA_ "Prio" BO_ 160 0;
BA_ "Prio" BO_ 1000 0;
BA_ "GenMsgCycleTime" BO_ 1000 1000;
BA_ "GenMsgSendType" BO_ 1000 0;
BA_ "Prio" BO_ 544 0;
BA_ "GenMsgCycleTime" BO_ 544 10;
BA_ "GenMsgSendType" BO_ 544 0;
BA_ "GenMsgSendType" BO_ 1399 0;
BA_ "GenMsgCycleTime" BO_ 1399 1000;
BA_ "Prio" BO_ 1399 0;
BA_ "Prio" BO_ 306 0;
BA_ "GenMsgCycleTime" BO_ 306 20;
BA_ "GenMsgSendType" BO_ 306 0;
BA_ "Prio" BO_ 112 0;
BA_ "GenMsgCycleTime" BO_ 112 100;
BA_ "GenMsgSendType" BO_ 112 0;
BA_ "Prio" BO_ 111 0;
BA_ "GenMsgCycleTime" BO_ 111 10;
BA_ "GenMsgSendType" BO_ 111 0;
BA_ "Prio" BO_ 110 0;
BA_ "GenMsgCycleTime" BO_ 110 20;
BA_ "GenMsgSendType" BO_ 110 0;
BA_ "Prio" BO_ 167 0;
BA_ "GenMsgCycleTime" BO_ 167 10;
BA_ "GenMsgSendType" BO_ 167 0;
BA_ "GenMsgSendType" BO_ 166 0;
BA_ "GenMsgCycleTime" BO_ 166 10;
BA_ "Prio" BO_ 166 0;
BA_ "GenMsgSendType" BO_ 161 0;
BA_ "GenMsgCycleTime" BO_ 161 10;
BA_ "Prio" BO_ 161 0;
BA_ "GenMsgSendType" BO_ 357 0;
BA_ "GenMsgCycleTime" BO_ 357 20;
BA_ "Prio" BO_ 357 0;
BA_ "Prio" BO_ 106 0;
BA_ "GenMsgCycleTime" BO_ 106 10;
BA_ "GenMsgSendType" BO_ 106 0;
BA_ "GenMsgSendType" BO_ 375 0;
BA_ "GenMsgCycleTime" BO_ 375 1000;
BA_ "Prio" BO_ 375 0;
BA_ "Prio" BO_ 100 0;
BA_ "GenMsgCycleTime" BO_ 100 10;
BA_ "GenMsgSendType" BO_ 100 0;
BA_ "GenMsgSendType" BO_ 105 0;
BA_ "GenMsgCycleTime" BO_ 105 10;
BA_ "Prio" BO_ 105 0;
BA_ "GenMsgSendType" BO_ 777 0;
BA_ "GenMsgCycleTime" BO_ 777 10;
BA_ "Prio" BO_ 777 0;
BA_ "Prio" BO_ 783 0;
BA_ "GenMsgCycleTime" BO_ 783 20;
BA_ "GenMsgSendType" BO_ 783 0;
BA_ "Prio" BO_ 776 0;
BA_ "GenMsgCycleTime" BO_ 776 10;
BA_ "GenMsgSendType" BO_ 776 0;
BA_ "Prio" BO_ 770 0;
BA_ "GenMsgCycleTime" BO_ 770 20;
BA_ "GenMsgSendType" BO_ 770 0;
BA_ "Prio" BO_ 768 0;
BA_ "GenMsgCycleTime" BO_ 768 10;
BA_ "GenMsgSendType" BO_ 768 0;
BA_ "GenMsgSendType" BO_ 778 0;
BA_ "GenMsgCycleTime" BO_ 778 10;
BA_ "Prio" BO_ 778 0;
BA_ "Prio" BO_ 780 0;
BA_ "GenMsgCycleTime" BO_ 780 20;
BA_ "GenMsgSendType" BO_ 780 0;
BA_ "Prio" BO_ 1402 0;
BA_ "GenMsgILSupport" BO_ 1402 0;
BA_ "GenMsgCycleTime" BO_ 1402 20;
BA_ "GenMsgSendType" BO_ 1402 0;
BA_ "GenMsgSendType" BO_ 256 0;
BA_ "GenMsgCycleTime" BO_ 256 10;
BA_ "Prio" BO_ 256 0;
BA_ "Prio" BO_ 850 0;
BA_ "GenMsgCycleTime" BO_ 850 50;
BA_ "GenMsgSendType" BO_ 850 0;
BA_ "Prio" BO_ 363 0;
BA_ "GenMsgCycleTime" BO_ 363 10;
BA_ "GenMsgSendType" BO_ 363 0;
BA_ "Prio" BO_ 631 0;
BA_ "GenMsgCycleTime" BO_ 631 100;
BA_ "GenMsgSendType" BO_ 631 0;
BA_ "Prio" BO_ 356 0;
BA_ "GenMsgCycleTime" BO_ 356 100;
BA_ "GenMsgSendType" BO_ 356 0;
BA_ "Prio" BO_ 368 0;
BA_ "GenMsgCycleTime" BO_ 368 20;
BA_ "GenMsgSendType" BO_ 368 0;
BA_ "Prio" BO_ 390 0;
BA_ "GenMsgCycleTime" BO_ 390 50;
BA_ "GenMsgSendType" BO_ 390 0;
BA_ "Prio" BO_ 630 0;
BA_ "GenMsgCycleTime" BO_ 630 50;
BA_ "GenMsgSendType" BO_ 630 0;
BA_ "Prio" BO_ 1825 0;
BA_ "GenMsgSendType" BO_ 1825 1;
BA_ "DiagRequest" BO_ 1825 1;
BA_ "Prio" BO_ 1502 0;
BA_ "GenMsgSendType" BO_ 1502 1;
BA_ "DiagRequest" BO_ 1502 1;
BA_ "Prio" BO_ 1602 0;
BA_ "GenMsgSendType" BO_ 1602 1;
BA_ "DiagResponse" BO_ 1602 1;
BA_ "Prio" BO_ 300 0;
BA_ "GenMsgCycleTime" BO_ 300 100;
BA_ "GenMsgSendType" BO_ 300 0;
BA_ "Prio" BO_ 1350 0;
BA_ "GenMsgCycleTime" BO_ 1350 1000;
BA_ "GenMsgSendType" BO_ 1350 0;
BA_ "Prio" BO_ 1398 0;
BA_ "GenMsgCycleTime" BO_ 1398 5000;
BA_ "GenMsgSendType" BO_ 1398 0;
BA_ "Prio" BO_ 151 0;
BA_ "GenMsgCycleTime" BO_ 151 50;
BA_ "GenMsgSendType" BO_ 151 0;
BA_ "GenMsgILSupport" BO_ 1888 0;
BA_ "Prio" BO_ 1888 0;
BA_ "DiagState" BO_ 1888 1;
BA_ "GenMsgSendType" BO_ 1888 1;
BA_ "Prio" BO_ 1351 0;
BA_ "GenMsgCycleTime" BO_ 1351 1000;
BA_ "GenMsgSendType" BO_ 1351 0;
BA_ "Prio" BO_ 150 0;
BA_ "GenMsgCycleTime" BO_ 150 50;
BA_ "GenMsgSendType" BO_ 150 0;
BA_ "Prio" BO_ 355 0;
BA_ "GenMsgCycleTime" BO_ 355 20;
BA_ "GenMsgSendType" BO_ 355 0;
BA_ "Prio" BO_ 360 0;
BA_ "GenMsgCycleTime" BO_ 360 20;
BA_ "GenMsgSendType" BO_ 360 0;
BA_ "Prio" BO_ 350 0;
BA_ "GenMsgCycleTime" BO_ 350 100;
BA_ "GenMsgSendType" BO_ 350 0;
BA_ "Prio" BO_ 157 0;
BA_ "GenMsgCycleTime" BO_ 157 10;
BA_ "GenMsgSendType" BO_ 157 0;
BA_ "Prio" BO_ 1833 0;
BA_ "GenMsgSendType" BO_ 1833 1;
BA_ "DiagResponse" BO_ 1833 1;
BA_ "SignalLongName" SG_ 177 AccPdlPstnCks "Acceleration Pedal Position Checksum";
BA_ "GenSigSendType" SG_ 177 AccPdlPstnCks 0;
BA_ "SignalLongName" SG_ 177 AccPdlPstnARC "Acceleration Pedal Position Alive Rolling Count";
BA_ "GenSigSendType" SG_ 177 AccPdlPstnARC 0;
BA_ "GenSigStartValue" SG_ 177 AccPdlPstn 1023;
BA_ "SignalLongName" SG_ 177 AccPdlPstn "Acceleration Pedal Position";
BA_ "GenSigSendType" SG_ 177 AccPdlPstn 0;
BA_ "GenSigSendType" SG_ 766 Fct_Int_Flag_HV_emergency 0;
BA_ "GenSigSendType" SG_ 766 Fct_Int_Flag_shifter 0;
BA_ "GenSigSendType" SG_ 766 Fct_Int_Flag_throttle 0;
BA_ "GenSigSendType" SG_ 766 eLCVDADDrvRqSt 0;
BA_ "SignalLongName" SG_ 766 eLCVDADDrvRqSt "eLCVD AD Drive Request State";
BA_ "GenSigSendType" SG_ 766 eLCVDVCUADInfChs 0;
BA_ "VNSigAllNodes" SG_ 766 eLCVDVCUADInfChs 1;
BA_ "SignalLongName" SG_ 766 eLCVDVCUADInfChs "eLCVD VCU AD Info Checksum";
BA_ "SignalType" SG_ 766 eLCVDVCUADInfChs "UNM";
BA_ "GenSigSendType" SG_ 766 eLCVDVCUADInfARC 0;
BA_ "VNSigAllNodes" SG_ 766 eLCVDVCUADInfARC 1;
BA_ "SignalLongName" SG_ 766 eLCVDVCUADInfARC "eLCVD VCU AD Info Alive Rolling Count";
BA_ "SignalType" SG_ 766 eLCVDVCUADInfARC "UNM";
BA_ "GenSigSendType" SG_ 162 Fct_Int_Flag_EPS 0;
BA_ "SignalLongName" SG_ 162 EPSADSwARC "EPS AD Switch Alive Rolling Count";
BA_ "GenSigSendType" SG_ 162 EPSADSwARC 0;
BA_ "SignalLongName" SG_ 162 EPSADSwChs "EPS AD Switch Checksum";
BA_ "GenSigSendType" SG_ 162 EPSADSwChs 0;
BA_ "GenSigSendType" SG_ 107 Fct_Int_Flag_ECD 0;
BA_ "GenSigSendType" SG_ 107 Fct_Int_Flag_ESC 0;
BA_ "GenSigSendType" SG_ 107 Fct_Int_Flag_TC 0;
BA_ "GenSigSendType" SG_ 107 Fct_Int_Flag_ABS 0;
BA_ "GenSigSendType" SG_ 107 Fct_Int_Flag_stabilization 0;
BA_ "GenSigSendType" SG_ 107 Fct_Int_Flag_brake_emergency 0;
BA_ "GenSigSendType" SG_ 107 Fct_Int_Flag_EPB_button 0;
BA_ "GenSigSendType" SG_ 107 Fct_Int_Flag_brake_pedal 0;
BA_ "SignalLongName" SG_ 107 IBCADSwChs "IBC AD Switch Checksum";
BA_ "GenSigSendType" SG_ 107 IBCADSwChs 0;
BA_ "SignalLongName" SG_ 107 IBCADSwARC "IBC AD Switch Alive Rolling Count";
BA_ "GenSigSendType" SG_ 107 IBCADSwARC 0;
BA_ "GenSigSendType" SG_ 99 DM_AD_Activation_Clamp 0;
BA_ "GenSigSendType" SG_ 99 DM_Mode_AD_HMI 0;
BA_ "GenSigSendType" SG_ 99 VCU_DM_Chs 0;
BA_ "GenSigSendType" SG_ 99 VCU_DM_ARC 0;
BA_ "GenSigSendType" SG_ 101 VCUADYwTrqRqRrVldt 0;
BA_ "SignalLongName" SG_ 101 VCUADYwTrqRqRrVldt "VCU AD Yaw Torque Request Rear Validity";
BA_ "GenSigSendType" SG_ 101 VCUADYwTrqRqRr 0;
BA_ "SignalLongName" SG_ 101 VCUADYwTrqRqRr "VCU AD Yaw Torque Request Rear";
BA_ "GenSigStartValue" SG_ 101 VCUADYwTrqRqRr 32768;
BA_ "GenSigSendType" SG_ 101 VCUADYwTrqRqFrtVldt 0;
BA_ "SignalLongName" SG_ 101 VCUADYwTrqRqFrtVldt "VCU AD Yaw Torque Request Front Validity";
BA_ "GenSigSendType" SG_ 101 VCUADYwTrqRqFrt 0;
BA_ "SignalLongName" SG_ 101 VCUADYwTrqRqFrt "VCU AD Yaw Torque Request Front";
BA_ "GenSigStartValue" SG_ 101 VCUADYwTrqRqFrt 32768;
BA_ "GenSigSendType" SG_ 101 VCUIBCADRq2Chs 0;
BA_ "SignalLongName" SG_ 101 VCUIBCADRq2Chs "VCU IBC AD Request 2 Checksum";
BA_ "GenSigSendType" SG_ 101 VCUIBCADRq2ARC 0;
BA_ "SignalLongName" SG_ 101 VCUIBCADRq2ARC "VCU IBC AD Request 2 Alive Rolling Count";
BA_ "SPN" SG_ 800 ExTirePressSupport 6990;
BA_ "SigType" SG_ 800 ExTirePressSupport 4;
BA_ "SPN" SG_ 800 TirePressThresholdDetection_13 521613;
BA_ "SigType" SG_ 800 TirePressThresholdDetection_13 0;
BA_ "SPN" SG_ 800 TirePressThresholdDetection_12 521612;
BA_ "SigType" SG_ 800 TirePressThresholdDetection_12 0;
BA_ "SPN" SG_ 800 TirePressThresholdDetection_11 521611;
BA_ "SigType" SG_ 800 TirePressThresholdDetection_11 0;
BA_ "SPN" SG_ 800 TirePressThresholdDetection_10 521610;
BA_ "SigType" SG_ 800 TirePressThresholdDetection_10 0;
BA_ "SPN" SG_ 800 TirePressThresholdDetection_01 521601;
BA_ "SigType" SG_ 800 TirePressThresholdDetection_01 0;
BA_ "SPN" SG_ 800 TirePress_33 521033;
BA_ "SigType" SG_ 800 TirePress_33 1;
BA_ "SPN" SG_ 800 TirePress_32 521032;
BA_ "SigType" SG_ 800 TirePress_32 1;
BA_ "SPN" SG_ 800 TirePress_31 521031;
BA_ "SigType" SG_ 800 TirePress_31 1;
BA_ "SPN" SG_ 800 TirePress_30 521030;
BA_ "SigType" SG_ 800 TirePress_30 1;
BA_ "SPN" SG_ 800 TirePress_23 521023;
BA_ "SigType" SG_ 800 TirePress_23 1;
BA_ "SPN" SG_ 800 TirePress_22 521022;
BA_ "SigType" SG_ 800 TirePress_22 1;
BA_ "SPN" SG_ 800 TirePress_21 521021;
BA_ "SigType" SG_ 800 TirePress_21 1;
BA_ "SPN" SG_ 800 TirePress_20 521020;
BA_ "SigType" SG_ 800 TirePress_20 1;
BA_ "SPN" SG_ 800 TirePress_13 521013;
BA_ "SigType" SG_ 800 TirePress_13 1;
BA_ "SPN" SG_ 800 TirePress_12 521012;
BA_ "SigType" SG_ 800 TirePress_12 1;
BA_ "SPN" SG_ 800 TirePress_11 521011;
BA_ "SigType" SG_ 800 TirePress_11 1;
BA_ "SPN" SG_ 800 TirePress_10 521010;
BA_ "SigType" SG_ 800 TirePress_10 1;
BA_ "SPN" SG_ 800 TireAirLeakageRate_33 521533;
BA_ "SigType" SG_ 800 TireAirLeakageRate_33 1;
BA_ "SPN" SG_ 800 TireAirLeakageRate_32 521532;
BA_ "SigType" SG_ 800 TireAirLeakageRate_32 1;
BA_ "SPN" SG_ 800 TireAirLeakageRate_31 521531;
BA_ "SigType" SG_ 800 TireAirLeakageRate_31 1;
BA_ "SPN" SG_ 800 TireAirLeakageRate_30 521530;
BA_ "SigType" SG_ 800 TireAirLeakageRate_30 1;
BA_ "SPN" SG_ 800 TireAirLeakageRate_23 521523;
BA_ "SigType" SG_ 800 TireAirLeakageRate_23 1;
BA_ "SPN" SG_ 800 TireAirLeakageRate_22 521522;
BA_ "SigType" SG_ 800 TireAirLeakageRate_22 1;
BA_ "SPN" SG_ 800 TireAirLeakageRate_21 521521;
BA_ "SigType" SG_ 800 TireAirLeakageRate_21 1;
BA_ "SPN" SG_ 800 TireAirLeakageRate_20 521520;
BA_ "SigType" SG_ 800 TireAirLeakageRate_20 1;
BA_ "SPN" SG_ 800 TireAirLeakageRate_13 521513;
BA_ "SigType" SG_ 800 TireAirLeakageRate_13 1;
BA_ "SPN" SG_ 800 TireAirLeakageRate_12 521512;
BA_ "SigType" SG_ 800 TireAirLeakageRate_12 1;
BA_ "SPN" SG_ 800 TireAirLeakageRate_11 521511;
BA_ "SigType" SG_ 800 TireAirLeakageRate_11 1;
BA_ "SPN" SG_ 800 TireAirLeakageRate_10 521510;
BA_ "SigType" SG_ 800 TireAirLeakageRate_10 1;
BA_ "SPN" SG_ 800 TireAirLeakageRate_01 521501;
BA_ "SigType" SG_ 800 TireAirLeakageRate_01 1;
BA_ "SPN" SG_ 800 TireAirLeakageRate_00 521500;
BA_ "SigType" SG_ 800 TireAirLeakageRate_00 1;
BA_ "SPN" SG_ 800 CTIWheelSensorStatus_33 521433;
BA_ "SigType" SG_ 800 CTIWheelSensorStatus_33 4;
BA_ "SPN" SG_ 800 CTIWheelSensorStatus_32 521432;
BA_ "SigType" SG_ 800 CTIWheelSensorStatus_32 4;
BA_ "SPN" SG_ 800 CTIWheelSensorStatus_31 521431;
BA_ "SigType" SG_ 800 CTIWheelSensorStatus_31 4;
BA_ "SPN" SG_ 800 CTIWheelSensorStatus_30 521430;
BA_ "SigType" SG_ 800 CTIWheelSensorStatus_30 4;
BA_ "SPN" SG_ 800 CTIWheelSensorStatus_23 521423;
BA_ "SigType" SG_ 800 CTIWheelSensorStatus_23 4;
BA_ "SPN" SG_ 800 CTIWheelSensorStatus_22 521422;
BA_ "SigType" SG_ 800 CTIWheelSensorStatus_22 4;
BA_ "SPN" SG_ 800 CTIWheelSensorStatus_21 521421;
BA_ "SigType" SG_ 800 CTIWheelSensorStatus_21 4;
BA_ "SPN" SG_ 800 CTIWheelSensorStatus_20 521420;
BA_ "SigType" SG_ 800 CTIWheelSensorStatus_20 4;
BA_ "SPN" SG_ 800 CTIWheelSensorStatus_13 521413;
BA_ "SigType" SG_ 800 CTIWheelSensorStatus_13 4;
BA_ "SPN" SG_ 800 CTIWheelSensorStatus_12 521412;
BA_ "SigType" SG_ 800 CTIWheelSensorStatus_12 4;
BA_ "SPN" SG_ 800 CTIWheelSensorStatus_11 521411;
BA_ "SigType" SG_ 800 CTIWheelSensorStatus_11 4;
BA_ "SPN" SG_ 800 CTIWheelSensorStatus_10 521410;
BA_ "SigType" SG_ 800 CTIWheelSensorStatus_10 4;
BA_ "SPN" SG_ 800 CTIWheelSensorStatus_01 521401;
BA_ "SigType" SG_ 800 CTIWheelSensorStatus_01 4;
BA_ "SPN" SG_ 800 CTIWheelEndElectricalFault_33 521233;
BA_ "SigType" SG_ 800 CTIWheelEndElectricalFault_33 4;
BA_ "SPN" SG_ 800 CTIWheelEndElectricalFault_32 521232;
BA_ "SigType" SG_ 800 CTIWheelEndElectricalFault_32 4;
BA_ "SPN" SG_ 800 CTIWheelEndElectricalFault_31 521231;
BA_ "SigType" SG_ 800 CTIWheelEndElectricalFault_31 4;
BA_ "SPN" SG_ 800 CTIWheelEndElectricalFault_30 521230;
BA_ "SigType" SG_ 800 CTIWheelEndElectricalFault_30 4;
BA_ "SPN" SG_ 800 CTIWheelEndElectricalFault_23 521223;
BA_ "SigType" SG_ 800 CTIWheelEndElectricalFault_23 4;
BA_ "SPN" SG_ 800 CTIWheelEndElectricalFault_22 521222;
BA_ "SigType" SG_ 800 CTIWheelEndElectricalFault_22 4;
BA_ "SPN" SG_ 800 CTIWheelEndElectricalFault_21 521221;
BA_ "SigType" SG_ 800 CTIWheelEndElectricalFault_21 4;
BA_ "SPN" SG_ 800 CTIWheelEndElectricalFault_20 521220;
BA_ "SigType" SG_ 800 CTIWheelEndElectricalFault_20 4;
BA_ "SPN" SG_ 800 CTIWheelEndElectricalFault_13 521213;
BA_ "SigType" SG_ 800 CTIWheelEndElectricalFault_13 4;
BA_ "SPN" SG_ 800 CTIWheelEndElectricalFault_12 521212;
BA_ "SigType" SG_ 800 CTIWheelEndElectricalFault_12 4;
BA_ "SPN" SG_ 800 CTIWheelEndElectricalFault_11 521211;
BA_ "SigType" SG_ 800 CTIWheelEndElectricalFault_11 4;
BA_ "SPN" SG_ 800 CTIWheelEndElectricalFault_10 521210;
BA_ "SigType" SG_ 800 CTIWheelEndElectricalFault_10 4;
BA_ "SPN" SG_ 800 CTIWheelEndElectricalFault_01 521201;
BA_ "SigType" SG_ 800 CTIWheelEndElectricalFault_01 4;
BA_ "SPN" SG_ 800 CTITireStatus_33 521333;
BA_ "SigType" SG_ 800 CTITireStatus_33 4;
BA_ "SPN" SG_ 800 CTITireStatus_32 521332;
BA_ "SigType" SG_ 800 CTITireStatus_32 4;
BA_ "SPN" SG_ 800 CTITireStatus_31 521331;
BA_ "SigType" SG_ 800 CTITireStatus_31 4;
BA_ "SPN" SG_ 800 CTITireStatus_30 521330;
BA_ "SigType" SG_ 800 CTITireStatus_30 4;
BA_ "SPN" SG_ 800 CTITireStatus_23 521323;
BA_ "SigType" SG_ 800 CTITireStatus_23 4;
BA_ "SPN" SG_ 800 CTITireStatus_22 521322;
BA_ "SigType" SG_ 800 CTITireStatus_22 4;
BA_ "SPN" SG_ 800 CTITireStatus_21 521321;
BA_ "SigType" SG_ 800 CTITireStatus_21 4;
BA_ "SPN" SG_ 800 CTITireStatus_20 521320;
BA_ "SigType" SG_ 800 CTITireStatus_20 4;
BA_ "SPN" SG_ 800 CTITireStatus_13 521313;
BA_ "SigType" SG_ 800 CTITireStatus_13 4;
BA_ "SPN" SG_ 800 CTITireStatus_12 521312;
BA_ "SigType" SG_ 800 CTITireStatus_12 4;
BA_ "SPN" SG_ 800 CTITireStatus_11 521311;
BA_ "SigType" SG_ 800 CTITireStatus_11 4;
BA_ "SPN" SG_ 800 CTITireStatus_10 521310;
BA_ "SigType" SG_ 800 CTITireStatus_10 4;
BA_ "SPN" SG_ 800 CTITireStatus_01 521301;
BA_ "SigType" SG_ 800 CTITireStatus_01 4;
BA_ "SPN" SG_ 800 TireTemp_11 521111;
BA_ "SigType" SG_ 800 TireTemp_11 1;
BA_ "SPN" SG_ 800 TireTemp_33 521133;
BA_ "SigType" SG_ 800 TireTemp_33 1;
BA_ "SPN" SG_ 800 TireTemp_32 521132;
BA_ "SigType" SG_ 800 TireTemp_32 1;
BA_ "SPN" SG_ 800 TireTemp_31 521131;
BA_ "SigType" SG_ 800 TireTemp_31 1;
BA_ "SPN" SG_ 800 TireTemp_30 521130;
BA_ "SigType" SG_ 800 TireTemp_30 1;
BA_ "SPN" SG_ 800 TireTemp_23 521123;
BA_ "SigType" SG_ 800 TireTemp_23 1;
BA_ "SPN" SG_ 800 TireTemp_22 521122;
BA_ "SigType" SG_ 800 TireTemp_22 1;
BA_ "SPN" SG_ 800 TireTemp_21 521121;
BA_ "SigType" SG_ 800 TireTemp_21 1;
BA_ "SPN" SG_ 800 TireTemp_20 521120;
BA_ "SigType" SG_ 800 TireTemp_20 1;
BA_ "SPN" SG_ 800 TireTemp_13 521113;
BA_ "SigType" SG_ 800 TireTemp_13 1;
BA_ "SPN" SG_ 800 TireTemp_12 521112;
BA_ "SigType" SG_ 800 TireTemp_12 1;
BA_ "SPN" SG_ 800 TireTemp_10 521110;
BA_ "SigType" SG_ 800 TireTemp_10 1;
BA_ "SPN" SG_ 800 TireTemp_01 521101;
BA_ "SigType" SG_ 800 TireTemp_01 1;
BA_ "SPN" SG_ 800 TireTemp_00 521100;
BA_ "SigType" SG_ 800 TireTemp_00 1;
BA_ "SPN" SG_ 800 TirePressThresholdDetection_33 521633;
BA_ "SigType" SG_ 800 TirePressThresholdDetection_33 0;
BA_ "SPN" SG_ 800 TirePressThresholdDetection_32 521632;
BA_ "SigType" SG_ 800 TirePressThresholdDetection_32 0;
BA_ "SPN" SG_ 800 TirePressThresholdDetection_31 521631;
BA_ "SigType" SG_ 800 TirePressThresholdDetection_31 0;
BA_ "SPN" SG_ 800 TirePressThresholdDetection_30 521630;
BA_ "SigType" SG_ 800 TirePressThresholdDetection_30 0;
BA_ "SPN" SG_ 800 TirePressThresholdDetection_23 521623;
BA_ "SigType" SG_ 800 TirePressThresholdDetection_23 0;
BA_ "SPN" SG_ 800 TirePressThresholdDetection_22 521622;
BA_ "SigType" SG_ 800 TirePressThresholdDetection_22 0;
BA_ "SPN" SG_ 800 TirePressThresholdDetection_21 521621;
BA_ "SigType" SG_ 800 TirePressThresholdDetection_21 0;
BA_ "SPN" SG_ 800 TirePressThresholdDetection_20 521620;
BA_ "SigType" SG_ 800 TirePressThresholdDetection_20 0;
BA_ "SPN" SG_ 800 TirePressThresholdDetection_00 521600;
BA_ "SigType" SG_ 800 TirePressThresholdDetection_00 0;
BA_ "SPN" SG_ 800 TirePress_01 521001;
BA_ "SigType" SG_ 800 TirePress_01 1;
BA_ "SPN" SG_ 800 TirePress_00 521000;
BA_ "SigType" SG_ 800 TirePress_00 1;
BA_ "SPN" SG_ 800 CTIWheelSensorStatus_00 521400;
BA_ "SigType" SG_ 800 CTIWheelSensorStatus_00 4;
BA_ "SPN" SG_ 800 CTIWheelEndElectricalFault_00 521200;
BA_ "SigType" SG_ 800 CTIWheelEndElectricalFault_00 4;
BA_ "SPN" SG_ 800 CTITireStatus_00 521300;
BA_ "SigType" SG_ 800 CTITireStatus_00 4;
BA_ "SPN" SG_ 800 TireLocation 929;
BA_ "GenSigSendType" SG_ 1985 CRO_data_field 0;
BA_ "GenSigSendType" SG_ 1985 CTR 0;
BA_ "GenSigSendType" SG_ 1985 CMD 0;
BA_ "GenSigSendType" SG_ 2001 PID 0;
BA_ "GenSigSendType" SG_ 160 StrWhlAngSenCalStat 0;
BA_ "VNSigAllNodes" SG_ 160 StrWhlAngSenCalStat 1;
BA_ "SignalLongName" SG_ 160 StrWhlAngSenCalStat "Steering Wheel Angle Sensor Calibration Status";
BA_ "SignalType" SG_ 160 StrWhlAngSenCalStat "ENM";
BA_ "GenSigSendType" SG_ 160 StWhlAngChksm 0;
BA_ "VNSigAllNodes" SG_ 160 StWhlAngChksm 1;
BA_ "SignalLongName" SG_ 160 StWhlAngChksm "Steering Wheel Angle Checksum";
BA_ "SignalType" SG_ 160 StWhlAngChksm "UNM";
BA_ "GenSigSendType" SG_ 160 StrWhAngGrd 0;
BA_ "VNSigAllNodes" SG_ 160 StrWhAngGrd 1;
BA_ "SignalLongName" SG_ 160 StrWhAngGrd "Steering Wheel Angle Gradient";
BA_ "SignalType" SG_ 160 StrWhAngGrd "SNM";
BA_ "GenSigStartValue" SG_ 160 StrWhAngGrd 4095;
BA_ "GenSigSendType" SG_ 160 StWhlAngAliveRollCnt 0;
BA_ "VNSigAllNodes" SG_ 160 StWhlAngAliveRollCnt 1;
BA_ "SignalLongName" SG_ 160 StWhlAngAliveRollCnt "Steering Wheel Angle Alive Rolling Count";
BA_ "SignalType" SG_ 160 StWhlAngAliveRollCnt "UNM";
BA_ "GenSigSendType" SG_ 160 StrWhAng 0;
BA_ "VNSigAllNodes" SG_ 160 StrWhAng 1;
BA_ "SignalLongName" SG_ 160 StrWhAng "Steering Wheel Angle";
BA_ "SignalType" SG_ 160 StrWhAng "SNM";
BA_ "GenSigStartValue" SG_ 160 StrWhAng 65535;
BA_ "GenSigSendType" SG_ 1000 TM_PTcoolingFluidTempOutlet 0;
BA_ "SignalLongName" SG_ 1000 TM_PTcoolingFluidTempOutlet "TM_PTcoolingFluidTempOutlet";
BA_ "GenSigStartValue" SG_ 1000 TM_PTcoolingFluidTempOutlet 255;
BA_ "GenSigSendType" SG_ 1000 TM_PTcoolingFluidTempInlet 0;
BA_ "SignalLongName" SG_ 1000 TM_PTcoolingFluidTempInlet "TM_PTcoolingFluidTempInlet";
BA_ "GenSigStartValue" SG_ 1000 TM_PTcoolingFluidTempInlet 255;
BA_ "GenSigSendType" SG_ 1000 TM_ESScoolingFluidTempOutlet 0;
BA_ "SignalLongName" SG_ 1000 TM_ESScoolingFluidTempOutlet "TM_ESScoolingFluidTempOutlet";
BA_ "GenSigStartValue" SG_ 1000 TM_ESScoolingFluidTempOutlet 255;
BA_ "GenSigSendType" SG_ 1000 TM_ESScoolingFluidTempInlet 0;
BA_ "GenSigStartValue" SG_ 1000 TM_ESScoolingFluidTempInlet 255;
BA_ "SignalLongName" SG_ 1000 TM_ESScoolingFluidTempInlet "TM_ESScoolingFluidTempInlet";
BA_ "GenSigSendType" SG_ 1000 TM_PassengerCabineAirTemperature 0;
BA_ "GenSigStartValue" SG_ 1000 TM_PassengerCabineAirTemperature 255;
BA_ "SignalLongName" SG_ 1000 TM_PassengerCabineAirTemperature "TM_PassengerCabineAirTemperature";
BA_ "GenSigSendType" SG_ 1000 TM_DriverCabineAirTemperature 0;
BA_ "GenSigStartValue" SG_ 1000 TM_DriverCabineAirTemperature 255;
BA_ "SignalLongName" SG_ 1000 TM_DriverCabineAirTemperature "TM_DriverCabineAirTemperature";
BA_ "GenSigSendType" SG_ 1000 TM_AmbientAirTemperature 0;
BA_ "GenSigStartValue" SG_ 1000 TM_AmbientAirTemperature 255;
BA_ "SignalLongName" SG_ 1000 TM_AmbientAirTemperature "TM_AmbientAirTemperature";
BA_ "GenSigSendType" SG_ 544 Checksum_220 0;
BA_ "GenSigSendType" SG_ 544 MessageCounter_220 0;
BA_ "GenSigSendType" SG_ 544 DC1_VoltageHV 0;
BA_ "GenSigStartValue" SG_ 544 DC1_VoltageHV 1022;
BA_ "GenSigSendType" SG_ 544 DC1_CurrentLV 0;
BA_ "GenSigStartValue" SG_ 544 DC1_CurrentLV 2046;
BA_ "GenSigSendType" SG_ 544 DC1_Mode 0;
BA_ "GenSigSendType" SG_ 544 DC1_CurrentHV 0;
BA_ "GenSigStartValue" SG_ 544 DC1_CurrentHV 2046;
BA_ "GenSigSendType" SG_ 544 DC1_Temp 0;
BA_ "GenSigStartValue" SG_ 544 DC1_Temp 254;
BA_ "GenSigSendType" SG_ 544 DC1_VoltageLV 0;
BA_ "GenSigStartValue" SG_ 544 DC1_VoltageLV 510;
BA_ "GenSigSendType" SG_ 1399 HMI_Info_Chs 0;
BA_ "GenSigSendType" SG_ 1399 HMI_Info_ALC 0;
BA_ "GenSigSendType" SG_ 1399 HMI_time_second 0;
BA_ "GenSigSendType" SG_ 1399 HMI_time_minute 0;
BA_ "GenSigSendType" SG_ 1399 HMI_time_hour 0;
BA_ "GenSigSendType" SG_ 1399 HMI_calender_day 0;
BA_ "GenSigSendType" SG_ 1399 HMI_calender_month 0;
BA_ "GenSigSendType" SG_ 1399 HMI_calender_year 0;
BA_ "GenSigSendType" SG_ 306 CCUCLacc 0;
BA_ "GenSigSendType" SG_ 306 CCUCL15L 0;
BA_ "GenSigSendType" SG_ 306 CCUClInfCks 0;
BA_ "GenSigSendType" SG_ 306 CCUClInfARC 0;
BA_ "GenSigSendType" SG_ 306 CCUCL50 0;
BA_ "GenSigSendType" SG_ 306 CCUCL15 0;
BA_ "GenSigSendType" SG_ 112 VCU_EPS_Limit_Chs 0;
BA_ "GenSigSendType" SG_ 112 VCU_EPS_Limit_ARC 0;
BA_ "GenSigSendType" SG_ 112 VCU_EPS_Steering_Rate_Limit 0;
BA_ "GenSigStartValue" SG_ 112 VCU_EPS_Steering_Rate_Limit 127.5;
BA_ "GenSigSendType" SG_ 112 VCU_EPS_Upper_Torque_Limit 0;
BA_ "GenSigStartValue" SG_ 112 VCU_EPS_Upper_Torque_Limit 128;
BA_ "GenSigSendType" SG_ 112 VCU_EPS_Lower_Torque_Limit 0;
BA_ "GenSigStartValue" SG_ 112 VCU_EPS_Lower_Torque_Limit 128;
BA_ "GenSigSendType" SG_ 111 VCU_EPS_AC_Chs 0;
BA_ "GenSigSendType" SG_ 111 VCU_EPS_AC_ARC 0;
BA_ "GenSigSendType" SG_ 111 VCU_EPS_AC_Haptic_Factor_2 0;
BA_ "GenSigSendType" SG_ 111 VCU_EPS_AC_Haptic_Factor_1 0;
BA_ "GenSigSendType" SG_ 111 VCU_EPS_AC_Demand 0;
BA_ "GenSigSendType" SG_ 111 VCU_EPS_AC_Request 0;
BA_ "GenSigSendType" SG_ 110 VCU_EPS_TO_Chs 0;
BA_ "GenSigSendType" SG_ 110 VCU_EPS_TO_ARC 0;
BA_ "GenSigSendType" SG_ 110 VCU_EPS_TO_Demand_Direction 0;
BA_ "GenSigSendType" SG_ 110 VCU_EPS_TO_Demand 0;
BA_ "GenSigSendType" SG_ 110 VCU_EPS_TO_Request 0;
BA_ "GenSigSendType" SG_ 167 EPSCld2ARC 0;
BA_ "SignalLongName" SG_ 167 EPSCld2ARC "EPS Cloud 2 Alive Rolling Count";
BA_ "GenSigSendType" SG_ 167 EPSCld2Chs 0;
BA_ "SignalLongName" SG_ 167 EPSCld2Chs "EPS Cloud 2 Checksum";
BA_ "GenSigSendType" SG_ 167 EPSSWA 0;
BA_ "GenSigStartValue" SG_ 167 EPSSWA 65535;
BA_ "SignalLongName" SG_ 167 EPSSWA "EPS Steering Wheel Angle";
BA_ "GenSigSendType" SG_ 167 EPSFltrdVhclSpd 0;
BA_ "GenSigStartValue" SG_ 167 EPSFltrdVhclSpd 2047;
BA_ "SignalLongName" SG_ 167 EPSFltrdVhclSpd "EPS Filtered Vehicle Speed";
BA_ "SignalLongName" SG_ 166 EPSCld1ARC "EPS Cloud 1 Alive Rolling Count";
BA_ "GenSigSendType" SG_ 166 EPSCld1ARC 0;
BA_ "GenSigSendType" SG_ 166 EPSCld1Chs 0;
BA_ "SignalLongName" SG_ 166 EPSCld1Chs "EPS Cloud 1 Checksum";
BA_ "GenSigSendType" SG_ 166 EPSDrvrTrqCld 0;
BA_ "GenSigStartValue" SG_ 166 EPSDrvrTrqCld 2047;
BA_ "SignalLongName" SG_ 166 EPSDrvrTrqCld "EPS Driver Torque Cloud";
BA_ "GenSigSendType" SG_ 166 EPSMtrTrqEstmt 0;
BA_ "GenSigStartValue" SG_ 166 EPSMtrTrqEstmt 2047;
BA_ "SignalLongName" SG_ 166 EPSMtrTrqEstmt "EPS Motor Torque Estimate";
BA_ "GenSigSendType" SG_ 166 EPSMtrVlct 0;
BA_ "GenSigStartValue" SG_ 166 EPSMtrVlct 65535;
BA_ "SignalLongName" SG_ 166 EPSMtrVlct "EPS Motor Velocity";
BA_ "GenSigSendType" SG_ 161 SPCMtrTrqDmndLmtd 0;
BA_ "SignalLongName" SG_ 161 SPCMtrTrqDmndLmtd "SPC Motor Torque Demand Limited";
BA_ "GenSigSendType" SG_ 161 SPCAngVlctRqstLmtd 0;
BA_ "SignalLongName" SG_ 161 SPCAngVlctRqstLmtd "SPC Angular Velocity Request Limited";
BA_ "GenSigSendType" SG_ 161 SPCAngRqstLmtd 0;
BA_ "SignalLongName" SG_ 161 SPCAngRqstLmtd "SPC Angle Request Limited";
BA_ "GenSigSendType" SG_ 161 SPCTrqRqstLmtd 0;
BA_ "SignalLongName" SG_ 161 SPCTrqRqstLmtd "SPC Torque Request Limited";
BA_ "GenSigSendType" SG_ 161 EPSIntErrSt 0;
BA_ "GenSigStartValue" SG_ 161 EPSIntErrSt 3;
BA_ "SignalLongName" SG_ 161 EPSIntErrSt "EPS Internal Error Status";
BA_ "GenSigSendType" SG_ 161 EPSDrvStrIntfrDtcd 0;
BA_ "SignalLongName" SG_ 161 EPSDrvStrIntfrDtcd "EPS Driver Steering Intereference Detected";
BA_ "GenSigSendType" SG_ 161 EPSDgrdtnLvl 0;
BA_ "SignalLongName" SG_ 161 EPSDgrdtnLvl "EPS Degradation Level";
BA_ "GenSigSendType" SG_ 161 EPSAssstAvlbl 0;
BA_ "SignalLongName" SG_ 161 EPSAssstAvlbl "EPS Assist Available";
BA_ "GenSigSendType" SG_ 161 EPSAnglCtrlIntrfcSt 0;
BA_ "SignalLongName" SG_ 161 EPSAnglCtrlIntrfcSt "ESP Angle Control Interface Status";
BA_ "GenSigSendType" SG_ 161 EPSInfChs 0;
BA_ "SignalLongName" SG_ 161 EPSInfChs "EPS Info Checksum";
BA_ "GenSigSendType" SG_ 161 EPSInfARC 0;
BA_ "SignalLongName" SG_ 161 EPSInfARC "EPS Info Alive Rolling Count";
BA_ "GenSigSendType" SG_ 161 EPSHndsOnDtctn 0;
BA_ "SignalLongName" SG_ 161 EPSHndsOnDtctn "EPS Hands On Detection";
BA_ "GenSigSendType" SG_ 161 EPSTrqOvrlyIntfcSt 0;
BA_ "SignalLongName" SG_ 161 EPSTrqOvrlyIntfcSt "EPS Torque Overlay Interface Status";
BA_ "GenSigSendType" SG_ 161 EPSDrvrTrq 0;
BA_ "GenSigStartValue" SG_ 161 EPSDrvrTrq 2047;
BA_ "SignalLongName" SG_ 161 EPSDrvrTrq "EPS Driver Torque";
BA_ "GenSigSendType" SG_ 357 VhclDrctnlStCOG 0;
BA_ "SignalType" SG_ 357 VhclDrctnlStCOG "ENM";
BA_ "SignalLongName" SG_ 357 VhclDrctnlStCOG "Vehicle Directional Status COG";
BA_ "VNSigAllNodes" SG_ 357 VhclDrctnlStCOG 1;
BA_ "GenSigSendType" SG_ 357 IBCVhclInf2Chs 0;
BA_ "VNSigAllNodes" SG_ 357 IBCVhclInf2Chs 1;
BA_ "SignalLongName" SG_ 357 IBCVhclInf2Chs "IBC Vehicle Info 2 Checksum";
BA_ "SignalType" SG_ 357 IBCVhclInf2Chs "UNM";
BA_ "GenSigSendType" SG_ 357 IBCVhclInf2ARC 0;
BA_ "VNSigAllNodes" SG_ 357 IBCVhclInf2ARC 1;
BA_ "SignalLongName" SG_ 357 IBCVhclInf2ARC "IBC Vehicle Info 2 Alive Rolling Count";
BA_ "SignalType" SG_ 357 IBCVhclInf2ARC "UNM";
BA_ "GenSigSendType" SG_ 357 VhclVlctCOGV 0;
BA_ "VNSigAllNodes" SG_ 357 VhclVlctCOGV 1;
BA_ "SignalLongName" SG_ 357 VhclVlctCOGV "Vehicle Velocity COG Validity";
BA_ "SignalType" SG_ 357 VhclVlctCOGV "ENM";
BA_ "GenSigSendType" SG_ 357 VhclVlctCOG 0;
BA_ "VNSigAllNodes" SG_ 357 VhclVlctCOG 1;
BA_ "GenSigStartValue" SG_ 357 VhclVlctCOG 16383;
BA_ "SignalLongName" SG_ 357 VhclVlctCOG "Vehicle Velocity COG";
BA_ "SignalType" SG_ 357 VhclVlctCOG "UNM";
BA_ "GenSigSendType" SG_ 357 VhStndDtc 0;
BA_ "SignalLongName" SG_ 357 VhStndDtc "Vehicle Standstill Detected";
BA_ "GenSigSendType" SG_ 106 IBCADVhclActBrkTrq 0;
BA_ "SignalLongName" SG_ 106 IBCADVhclActBrkTrq "IBC AD Vehicle Actual Brake Torque";
BA_ "GenSigStartValue" SG_ 106 IBCADVhclActBrkTrq 32768;
BA_ "GenSigSendType" SG_ 106 IBCVCUADInf2Chs 0;
BA_ "SignalLongName" SG_ 106 IBCVCUADInf2Chs "IBC VCU AD Info 2 Checksum";
BA_ "GenSigSendType" SG_ 106 IBCVCUADInf2ARC 0;
BA_ "SignalLongName" SG_ 106 IBCVCUADInf2ARC "IBC VCU AD Info 2 Alive Rolling Count";
BA_ "GenSigSendType" SG_ 375 IBCADCOGLtPsVldt 0;
BA_ "SignalLongName" SG_ 375 IBCADCOGLtPsVldt "IBC AD COG Lateral Position Validity";
BA_ "GenSigSendType" SG_ 375 IBCADCOGLtPos 0;
BA_ "GenSigStartValue" SG_ 375 IBCADCOGLtPos 1024;
BA_ "SignalLongName" SG_ 375 IBCADCOGLtPos "IBC AD COG Lateral Position";
BA_ "GenSigSendType" SG_ 375 IBCADCOGLngPsVldt 0;
BA_ "SignalLongName" SG_ 375 IBCADCOGLngPsVldt "IBC AD COG Longitudinal Position Validity";
BA_ "GenSigSendType" SG_ 375 IBCADCOGLgPos 0;
BA_ "GenSigStartValue" SG_ 375 IBCADCOGLgPos 1024;
BA_ "SignalLongName" SG_ 375 IBCADCOGLgPos "IBC AD COG Longitudinal Position";
BA_ "GenSigSendType" SG_ 375 IBCADVhclWghtVldt 0;
BA_ "SignalLongName" SG_ 375 IBCADVhclWghtVldt "IBC AD Vehicle Weight Validity";
BA_ "GenSigSendType" SG_ 375 IBCADVhclWght 0;
BA_ "SignalLongName" SG_ 375 IBCADVhclWght "IBC AD Vehicle Weight";
BA_ "GenSigSendType" SG_ 375 IBCVCUADInf3Chs 0;
BA_ "SignalLongName" SG_ 375 IBCVCUADInf3Chs "IBC VCU AD Info 3 Checksum";
BA_ "GenSigSendType" SG_ 375 IBCVCUADInf3ARC 0;
BA_ "SignalLongName" SG_ 375 IBCVCUADInf3ARC "IBC VCU AD Info 3 Alive Rolling Count";
BA_ "GenSigSendType" SG_ 100 VCUADSsmMd 0;
BA_ "SignalLongName" SG_ 100 VCUADSsmMd "VCU AD Standstill Mode";
BA_ "GenSigSendType" SG_ 100 VCUADBrkRqMd 0;
BA_ "SignalLongName" SG_ 100 VCUADBrkRqMd "VCU AD Brake Request Mode";
BA_ "GenSigSendType" SG_ 100 VCUADBrkChc 0;
BA_ "SignalLongName" SG_ 100 VCUADBrkChc "VCU AD Brake Characteristic";
BA_ "GenSigSendType" SG_ 100 VCUADTrqRqVldt 0;
BA_ "SignalLongName" SG_ 100 VCUADTrqRqVldt "VCU AD Torque Request Validity";
BA_ "GenSigSendType" SG_ 100 VCUADTrqRq 0;
BA_ "GenSigStartValue" SG_ 100 VCUADTrqRq 32768;
BA_ "SignalLongName" SG_ 100 VCUADTrqRq "VCU AD Torque Request";
BA_ "GenSigStartValue" SG_ 100 VCUADaRq 2048;
BA_ "GenSigSendType" SG_ 100 VCUADaRq 0;
BA_ "SignalLongName" SG_ 100 VCUADaRq "VCU AD Acceleration Request";
BA_ "GenSigSendType" SG_ 100 VCUADaRqVldt 0;
BA_ "SignalLongName" SG_ 100 VCUADaRqVldt "VCU AD Acceleration Request Validity";
BA_ "GenSigSendType" SG_ 100 VCUIBCADRq1Chs 0;
BA_ "SignalLongName" SG_ 100 VCUIBCADRq1Chs "VCU IBC AD Request 1 Checksum";
BA_ "GenSigSendType" SG_ 100 VCUIBCADRq1ARC 0;
BA_ "SignalLongName" SG_ 100 VCUIBCADRq1ARC "VCU IBC AD Request 1 Alive Rolling Count";
BA_ "GenSigSendType" SG_ 105 IBCADMnAvBrkTrq 0;
BA_ "GenSigStartValue" SG_ 105 IBCADMnAvBrkTrq 65535;
BA_ "SignalLongName" SG_ 105 IBCADMnAvBrkTrq "IBC AD Min Available Brake Torque";
BA_ "GenSigSendType" SG_ 105 IBCADMxAvBrkTrq 0;
BA_ "SignalLongName" SG_ 105 IBCADMxAvBrkTrq "IBC AD Max Available Brake Torque";
BA_ "GenSigStartValue" SG_ 105 IBCADMxAvBrkTrq 65535;
BA_ "GenSigSendType" SG_ 105 IBCADYwRqSt 0;
BA_ "SignalLongName" SG_ 105 IBCADYwRqSt "IBC AD Yaw Request State";
BA_ "GenSigSendType" SG_ 105 IBCADBrkRqSt 0;
BA_ "SignalLongName" SG_ 105 IBCADBrkRqSt "IBC AD Brake Request State";
BA_ "GenSigSendType" SG_ 105 IBCVCUADInf1Chs 0;
BA_ "SignalLongName" SG_ 105 IBCVCUADInf1Chs "IBC VCU AD Info 1 Checksum";
BA_ "GenSigSendType" SG_ 105 IBCVCUADInf1ARC 0;
BA_ "SignalLongName" SG_ 105 IBCVCUADInf1ARC "IBC VCU AD Info 1 Alive Rolling Count";
BA_ "GenSigSendType" SG_ 777 eLCVDDrvTrqRqChs 0;
BA_ "SignalLongName" SG_ 777 eLCVDDrvTrqRqChs "eLCVD Driver Torque Request Checksum";
BA_ "GenSigSendType" SG_ 777 eLCVDDrvTrqRqARC 0;
BA_ "SignalLongName" SG_ 777 eLCVDDrvTrqRqARC "eLCVD Driver Torque Request Alive Rolling Count";
BA_ "GenSigSendType" SG_ 777 eLCVDDrvTrqRq 0;
BA_ "SignalLongName" SG_ 777 eLCVDDrvTrqRq "eLCVD Driver Torque Request";
BA_ "GenSigSendType" SG_ 783 CAN_PLock_EmgPathVolt 0;
BA_ "GenSigSendType" SG_ 783 CAN_PLock_EmgDiagState 0;
BA_ "GenSigSendType" SG_ 783 CAN_PLock_EmgPathState 0;
BA_ "GenSigSendType" SG_ 783 CAN_PLock_AdaptDataSens_high 0;
BA_ "GenSigSendType" SG_ 783 CAN_PLock_AdaptDataSens_low 0;
BA_ "GenSigSendType" SG_ 783 CAN_PLock_Adapted 0;
BA_ "GenSigSendType" SG_ 783 CAN_PLock_ActCurr 0;
BA_ "GenSigSendType" SG_ 783 CAN_PLock_SensVolt 0;
BA_ "GenSigSendType" SG_ 783 CAN_PLock_State 0;
BA_ "GenSigSendType" SG_ 776 INV9_Counter 0;
BA_ "GenSigSendType" SG_ 776 INV9_Checksum 0;
BA_ "GenSigSendType" SG_ 776 INV9_EMOperatingModeIndication 0;
BA_ "GenSigSendType" SG_ 776 INV9_EMTorqueMinAvailable 0;
BA_ "GenSigSendType" SG_ 776 INV9_EMTorqueMaxAvailable 0;
BA_ "GenSigSendType" SG_ 770 INV3_Counter 0;
BA_ "GenSigSendType" SG_ 770 INV3_Checksum 0;
BA_ "GenSigSendType" SG_ 770 INV3_INVDeratingIndication 0;
BA_ "GenSigSendType" SG_ 770 INV3_ECUModeIndication 0;
BA_ "GenSigSendType" SG_ 770 INV3_EMDeratingIndication 0;
BA_ "GenSigSendType" SG_ 768 INV1_EMSpeedIndication 0;
BA_ "GenSigSendType" SG_ 768 INV1_EMTorqueIndication 0;
BA_ "GenSigSendType" SG_ 768 INV1_Counter 0;
BA_ "GenSigSendType" SG_ 768 INV1_Checksum 0;
BA_ "GenSigSendType" SG_ 778 eLCVDRegenBrkAxTorqCapDec 0;
BA_ "SignalLongName" SG_ 778 eLCVDRegenBrkAxTorqCapDec "eLCVD Regenerative Braking Axle Torque Capability Decelerate";
BA_ "GenSigSendType" SG_ 778 eLCVDRegenBrkAxTorqCapAcc 0;
BA_ "SignalLongName" SG_ 778 eLCVDRegenBrkAxTorqCapAcc "eLCVD Regenerative Braking Axle Torque Capability Accelerate";
BA_ "GenSigSendType" SG_ 778 eLCVDRegenBrkAxTrqAch 0;
BA_ "GenSigStartValue" SG_ 778 eLCVDRegenBrkAxTrqAch 32766;
BA_ "SignalLongName" SG_ 778 eLCVDRegenBrkAxTrqAch "eLCVD Regenerative Braking Axle Torque Achieved";
BA_ "GenSigSendType" SG_ 778 eLCVDRegenBrkARC 0;
BA_ "SignalLongName" SG_ 778 eLCVDRegenBrkARC "eLCVD Regenerative Braking  Alive Rolling Count";
BA_ "GenSigSendType" SG_ 778 eLCVDRegenBrkChs 0;
BA_ "SignalLongName" SG_ 778 eLCVDRegenBrkChs "eLCVD Regenerative Braking Checksum";
BA_ "GenSigSendType" SG_ 780 eLCVDRlsdShftPos 0;
BA_ "SignalLongName" SG_ 780 eLCVDRlsdShftPos "eLCVD Released Shifter Position";
BA_ "GenSigSendType" SG_ 780 eLCVDShftPosCks 0;
BA_ "SignalLongName" SG_ 780 eLCVDShftPosCks "eLCVD Shifter Position Checksum";
BA_ "GenSigSendType" SG_ 780 eLCVDShftPosARC 0;
BA_ "SignalLongName" SG_ 780 eLCVDShftPosARC "eLCVD Shifter Position Alive Rolling Count";
BA_ "GenSigSendType" SG_ 780 eLCVDActShftPos 0;
BA_ "SignalLongName" SG_ 780 eLCVDActShftPos "eLCVD Actual Shifter Position";
BA_ "GenSigSendType" SG_ 1402 IBCIntErrChs 0;
BA_ "SignalLongName" SG_ 1402 IBCIntErrChs "IBC Internal Error Checksum";
BA_ "GenSigSendType" SG_ 1402 IBCIntErrARC 0;
BA_ "SignalLongName" SG_ 1402 IBCIntErrARC "IBC Internal Error Alive Rolling Count";
BA_ "GenSigSendType" SG_ 1402 IBCIntErrSt 0;
BA_ "GenSigStartValue" SG_ 1402 IBCIntErrSt 3;
BA_ "SignalLongName" SG_ 1402 IBCIntErrSt "IBC Internal Error Status";
BA_ "GenSigSendType" SG_ 256 IBCRegenBrkSt 0;
BA_ "SignalLongName" SG_ 256 IBCRegenBrkSt "IBC Regenerative Braking Status";
BA_ "GenSigSendType" SG_ 256 IBCRegenBrkChs 0;
BA_ "SignalLongName" SG_ 256 IBCRegenBrkChs "IBC Regenerative Braking Checksum";
BA_ "GenSigSendType" SG_ 256 IBCRegenBrkARC 0;
BA_ "SignalLongName" SG_ 256 IBCRegenBrkARC "IBC Regenerative Braking Alive Rolling Count";
BA_ "GenSigSendType" SG_ 256 IBCRegenBrkAxTrqRqst 0;
BA_ "SignalLongName" SG_ 256 IBCRegenBrkAxTrqRqst "IBC Regenerative Braking Axle Torque Request";
BA_ "GenSigSendType" SG_ 850 IMUProtYawRtM 0;
BA_ "SignalType" SG_ 850 IMUProtYawRtM "ENM";
BA_ "SignalLongName" SG_ 850 IMUProtYawRtM "Inertial Measurement Unit Protected Yaw Rate Mask";
BA_ "VNSigAllNodes" SG_ 850 IMUProtYawRtM 1;
BA_ "GenSigSendType" SG_ 850 IMUProtYawRt 0;
BA_ "GenSigStartValue" SG_ 850 IMUProtYawRt 4095;
BA_ "SignalType" SG_ 850 IMUProtYawRt "SNM";
BA_ "SignalLongName" SG_ 850 IMUProtYawRt "Inertial Measurement Unit Protected Yaw Rate";
BA_ "VNSigAllNodes" SG_ 850 IMUProtYawRt 1;
BA_ "GenSigSendType" SG_ 850 IMUProtLonAccM 0;
BA_ "SignalType" SG_ 850 IMUProtLonAccM "ENM";
BA_ "SignalLongName" SG_ 850 IMUProtLonAccM "Inertial Measurement Unit Protected Longitudinal Acceleration Mask";
BA_ "VNSigAllNodes" SG_ 850 IMUProtLonAccM 1;
BA_ "GenSigSendType" SG_ 850 IMUProtLonAcc 0;
BA_ "GenSigStartValue" SG_ 850 IMUProtLonAcc 1023;
BA_ "SignalType" SG_ 850 IMUProtLonAcc "SNM";
BA_ "SignalLongName" SG_ 850 IMUProtLonAcc "Inertial Measurement Unit Protected Longitudinal Acceleration";
BA_ "VNSigAllNodes" SG_ 850 IMUProtLonAcc 1;
BA_ "GenSigSendType" SG_ 850 IMUProtLatAccM 0;
BA_ "SignalType" SG_ 850 IMUProtLatAccM "ENM";
BA_ "SignalLongName" SG_ 850 IMUProtLatAccM "Inertial Measurement Unit Protected Lateral Acceleration Mask";
BA_ "VNSigAllNodes" SG_ 850 IMUProtLatAccM 1;
BA_ "GenSigSendType" SG_ 850 IMUProtLatAcc 0;
BA_ "GenSigStartValue" SG_ 850 IMUProtLatAcc 4095;
BA_ "SignalType" SG_ 850 IMUProtLatAcc "SNM";
BA_ "SignalLongName" SG_ 850 IMUProtLatAcc "Inertial Measurement Unit Protected Lateral Acceleration";
BA_ "VNSigAllNodes" SG_ 850 IMUProtLatAcc 1;
BA_ "GenSigSendType" SG_ 850 IMUProtChksum 0;
BA_ "SignalType" SG_ 850 IMUProtChksum "UNM";
BA_ "SignalLongName" SG_ 850 IMUProtChksum "Inertial Measurement Unit Protected Checksum";
BA_ "VNSigAllNodes" SG_ 850 IMUProtChksum 1;
BA_ "GenSigSendType" SG_ 850 IMUProtARC 0;
BA_ "SignalType" SG_ 850 IMUProtARC "UNM";
BA_ "SignalLongName" SG_ 850 IMUProtARC "Inertial Measurement Unit Protected Alive Rolling Count";
BA_ "VNSigAllNodes" SG_ 850 IMUProtARC 1;
BA_ "GenSigSendType" SG_ 363 ChsBrkPdlPsERltdV 0;
BA_ "SignalType" SG_ 363 ChsBrkPdlPsERltdV "ENM";
BA_ "SignalLongName" SG_ 363 ChsBrkPdlPsERltdV "Chassis Brake Pedal Position Emissions Related Validity";
BA_ "VNSigAllNodes" SG_ 363 ChsBrkPdlPsERltdV 1;
BA_ "GenSigSendType" SG_ 363 ChsBrkPdlPsERltd 0;
BA_ "SignalType" SG_ 363 ChsBrkPdlPsERltd "UNM";
BA_ "SignalLongName" SG_ 363 ChsBrkPdlPsERltd "Chassis Brake Pedal Position Emissions Related";
BA_ "VNSigAllNodes" SG_ 363 ChsBrkPdlPsERltd 1;
BA_ "GenSigSendType" SG_ 363 DrvIntndTtlBrkTrqChs 0;
BA_ "SignalType" SG_ 363 DrvIntndTtlBrkTrqChs "UNM";
BA_ "SignalLongName" SG_ 363 DrvIntndTtlBrkTrqChs "Driver Intended Total Brake Torque Checksum";
BA_ "VNSigAllNodes" SG_ 363 DrvIntndTtlBrkTrqChs 1;
BA_ "GenSigSendType" SG_ 363 DrvIntndTtlBrkTrqARC 0;
BA_ "SignalType" SG_ 363 DrvIntndTtlBrkTrqARC "UNM";
BA_ "SignalLongName" SG_ 363 DrvIntndTtlBrkTrqARC "Driver Intended Total Brake Torque Alive Rolling Count";
BA_ "VNSigAllNodes" SG_ 363 DrvIntndTtlBrkTrqARC 1;
BA_ "GenSigSendType" SG_ 363 DrvIntndTtlBrkTrq 0;
BA_ "SignalType" SG_ 363 DrvIntndTtlBrkTrq "UNM";
BA_ "SignalLongName" SG_ 363 DrvIntndTtlBrkTrq "Driver Intended Total Brake Torque";
BA_ "VNSigAllNodes" SG_ 363 DrvIntndTtlBrkTrq 1;
BA_ "GenSigStartValue" SG_ 363 DrvIntndTtlBrkTrq 16383;
BA_ "GenSigSendType" SG_ 631 ElecPrkBrkStatChs 0;
BA_ "SignalType" SG_ 631 ElecPrkBrkStatChs "UNM";
BA_ "SignalLongName" SG_ 631 ElecPrkBrkStatChs "Electric Park Brake Status Checksum";
BA_ "VNSigAllNodes" SG_ 631 ElecPrkBrkStatChs 1;
BA_ "GenSigSendType" SG_ 631 ElecPrkBrkApplStatPV 0;
BA_ "SignalType" SG_ 631 ElecPrkBrkApplStatPV "UNM";
BA_ "SignalLongName" SG_ 631 ElecPrkBrkApplStatPV "Electric Park Brake Application Status Protection Value";
BA_ "VNSigAllNodes" SG_ 631 ElecPrkBrkApplStatPV 1;
BA_ "GenSigSendType" SG_ 631 ElecPrkBrkAvailStatPV 0;
BA_ "SignalType" SG_ 631 ElecPrkBrkAvailStatPV "UNM";
BA_ "SignalLongName" SG_ 631 ElecPrkBrkAvailStatPV "Electric Park Brake Availability Status Protection Value";
BA_ "VNSigAllNodes" SG_ 631 ElecPrkBrkAvailStatPV 1;
BA_ "GenSigSendType" SG_ 631 ElecPrkBrkAvailStat 0;
BA_ "SignalType" SG_ 631 ElecPrkBrkAvailStat "ENM";
BA_ "SignalLongName" SG_ 631 ElecPrkBrkAvailStat "Electric Park Brake Availability Status";
BA_ "VNSigAllNodes" SG_ 631 ElecPrkBrkAvailStat 1;
BA_ "GenSigSendType" SG_ 631 ElecPrkBrkStatARC 0;
BA_ "SignalType" SG_ 631 ElecPrkBrkStatARC "UNM";
BA_ "SignalLongName" SG_ 631 ElecPrkBrkStatARC "Electric Park Brake Status Alive Rolling Count";
BA_ "VNSigAllNodes" SG_ 631 ElecPrkBrkStatARC 1;
BA_ "GenSigSendType" SG_ 631 ElecPrkBrkApplStat 0;
BA_ "SignalType" SG_ 631 ElecPrkBrkApplStat "ENM";
BA_ "SignalLongName" SG_ 631 ElecPrkBrkApplStat "Electric Park Brake Application Status";
BA_ "VNSigAllNodes" SG_ 631 ElecPrkBrkApplStat 1;
BA_ "GenSigSendType" SG_ 631 PrtdEPBSwStat 0;
BA_ "SignalType" SG_ 631 PrtdEPBSwStat "ENM";
BA_ "SignalLongName" SG_ 631 PrtdEPBSwStat "Protected Electric Park Brake Switch Status";
BA_ "VNSigAllNodes" SG_ 631 PrtdEPBSwStat 1;
BA_ "GenSigSendType" SG_ 356 IBCVhclInf1Chs 0;
BA_ "SignalType" SG_ 356 IBCVhclInf1Chs "UNM";
BA_ "SignalLongName" SG_ 356 IBCVhclInf1Chs "IBC Vehicle Info 1 Checksum";
BA_ "VNSigAllNodes" SG_ 356 IBCVhclInf1Chs 1;
BA_ "GenSigSendType" SG_ 356 IBCVhclInf1ARC 0;
BA_ "SignalType" SG_ 356 IBCVhclInf1ARC "UNM";
BA_ "SignalLongName" SG_ 356 IBCVhclInf1ARC "IBC Vehicle Info 1 Alive Rolling Count";
BA_ "VNSigAllNodes" SG_ 356 IBCVhclInf1ARC 1;
BA_ "GenSigSendType" SG_ 356 AdptDrvrSeatStng 0;
BA_ "SignalType" SG_ 356 AdptDrvrSeatStng "ENM";
BA_ "SignalLongName" SG_ 356 AdptDrvrSeatStng "Adaptive Driver Seat Setting";
BA_ "VNSigAllNodes" SG_ 356 AdptDrvrSeatStng 1;
BA_ "GenSigSendType" SG_ 356 AdptPsngrSeatStng 0;
BA_ "SignalType" SG_ 356 AdptPsngrSeatStng "ENM";
BA_ "SignalLongName" SG_ 356 AdptPsngrSeatStng "Adaptive Passenger Seat Setting";
BA_ "VNSigAllNodes" SG_ 356 AdptPsngrSeatStng 1;
BA_ "GenSigSendType" SG_ 356 TnDrvTrCtrlOffUnbIO 0;
BA_ "SignalType" SG_ 356 TnDrvTrCtrlOffUnbIO "BLN";
BA_ "SignalLongName" SG_ 356 TnDrvTrCtrlOffUnbIO "Teen Driver Traction Control Off Unavailable Indication On";
BA_ "VNSigAllNodes" SG_ 356 TnDrvTrCtrlOffUnbIO 1;
BA_ "GenSigSendType" SG_ 356 TnDrvStblCtrlOffUnbIO 0;
BA_ "SignalType" SG_ 356 TnDrvStblCtrlOffUnbIO "BLN";
BA_ "SignalLongName" SG_ 356 TnDrvStblCtrlOffUnbIO "Teen Driver Stability Control Off Unavailable Indication On";
BA_ "VNSigAllNodes" SG_ 356 TnDrvStblCtrlOffUnbIO 1;
BA_ "GenSigSendType" SG_ 356 VehRollAngleV 0;
BA_ "SignalType" SG_ 356 VehRollAngleV "ENM";
BA_ "SignalLongName" SG_ 356 VehRollAngleV "Vehicle Roll Angle Validity";
BA_ "VNSigAllNodes" SG_ 356 VehRollAngleV 1;
BA_ "GenSigSendType" SG_ 356 VehRollAngle 0;
BA_ "SignalType" SG_ 356 VehRollAngle "UNM";
BA_ "SignalLongName" SG_ 356 VehRollAngle "Vehicle Roll Angle";
BA_ "VNSigAllNodes" SG_ 356 VehRollAngle 1;
BA_ "GenSigStartValue" SG_ 356 VehRollAngle 127;
BA_ "GenSigSendType" SG_ 356 VehPitchAngleV 0;
BA_ "SignalType" SG_ 356 VehPitchAngleV "ENM";
BA_ "SignalLongName" SG_ 356 VehPitchAngleV "Vehicle Pitch Angle Validity";
BA_ "VNSigAllNodes" SG_ 356 VehPitchAngleV 1;
BA_ "GenSigSendType" SG_ 356 VehPitchAngle 0;
BA_ "SignalType" SG_ 356 VehPitchAngle "UNM";
BA_ "SignalLongName" SG_ 356 VehPitchAngle "Vehicle Pitch Angle";
BA_ "VNSigAllNodes" SG_ 356 VehPitchAngle 1;
BA_ "GenSigStartValue" SG_ 356 VehPitchAngle 127;
BA_ "GenSigSendType" SG_ 356 RdWhlAngV 0;
BA_ "SignalType" SG_ 356 RdWhlAngV "ENM";
BA_ "SignalLongName" SG_ 356 RdWhlAngV "Road Wheel Angle Validity";
BA_ "VNSigAllNodes" SG_ 356 RdWhlAngV 1;
BA_ "GenSigSendType" SG_ 356 RdWhlAng 0;
BA_ "SignalType" SG_ 356 RdWhlAng "UNM";
BA_ "SignalLongName" SG_ 356 RdWhlAng "Road Wheel Angle";
BA_ "VNSigAllNodes" SG_ 356 RdWhlAng 1;
BA_ "GenSigStartValue" SG_ 356 RdWhlAng 127;
BA_ "GenSigSendType" SG_ 356 PerfTrcCrnExStngVal 0;
BA_ "SignalType" SG_ 356 PerfTrcCrnExStngVal "ENM";
BA_ "SignalLongName" SG_ 356 PerfTrcCrnExStngVal "Performance Traction Corner Exit Setting Value";
BA_ "VNSigAllNodes" SG_ 356 PerfTrcCrnExStngVal 1;
BA_ "GenSigSendType" SG_ 368 IBCVhcStbChs 0;
BA_ "SignalLongName" SG_ 368 IBCVhcStbChs "IBC Vehicle Stability Checksum";
BA_ "GenSigSendType" SG_ 368 IBCVhcStbARC 0;
BA_ "SignalLongName" SG_ 368 IBCVhcStbARC "IBC Vehicle Stability Alive Rolling Count";
BA_ "GenSigSendType" SG_ 368 VSELongAccLoResV 0;
BA_ "SignalType" SG_ 368 VSELongAccLoResV "ENM";
BA_ "SignalLongName" SG_ 368 VSELongAccLoResV "Vehicle Stability Enhancement Longitudinal Acceleration Low Resolution Validity";
BA_ "VNSigAllNodes" SG_ 368 VSELongAccLoResV 1;
BA_ "GenSigSendType" SG_ 368 VSELongAccLoRes 0;
BA_ "GenSigStartValue" SG_ 368 VSELongAccLoRes 1023;
BA_ "SignalType" SG_ 368 VSELongAccLoRes "SNM";
BA_ "SignalLongName" SG_ 368 VSELongAccLoRes "Vehicle Stability Enhancement Longitudinal Acceleration Low Resolution";
BA_ "VNSigAllNodes" SG_ 368 VSELongAccLoRes 1;
BA_ "GenSigSendType" SG_ 368 StrAngSnsPolRat 0;
BA_ "SignalType" SG_ 368 StrAngSnsPolRat "ENM";
BA_ "SignalLongName" SG_ 368 StrAngSnsPolRat "Steering Angle Sensor Polarity Rationality";
BA_ "VNSigAllNodes" SG_ 368 StrAngSnsPolRat 1;
BA_ "GenSigSendType" SG_ 368 LatAccSnsPolRat 0;
BA_ "SignalType" SG_ 368 LatAccSnsPolRat "ENM";
BA_ "SignalLongName" SG_ 368 LatAccSnsPolRat "Lateral Acceleration Sensor Polarity Rationality";
BA_ "VNSigAllNodes" SG_ 368 LatAccSnsPolRat 1;
BA_ "GenSigSendType" SG_ 390 RedntVSEAct 0;
BA_ "SignalType" SG_ 390 RedntVSEAct "BLN";
BA_ "SignalLongName" SG_ 390 RedntVSEAct "Redundant Vehicle Stability Enhancement System Active";
BA_ "VNSigAllNodes" SG_ 390 RedntVSEAct 1;
BA_ "GenSigSendType" SG_ 390 HilRlbkCtrlActIO 0;
BA_ "SignalType" SG_ 390 HilRlbkCtrlActIO "BLN";
BA_ "SignalLongName" SG_ 390 HilRlbkCtrlActIO "Hill Rollback Control Active Indiction On";
BA_ "VNSigAllNodes" SG_ 390 HilRlbkCtrlActIO 1;
BA_ "GenSigSendType" SG_ 390 AutoBrkngAvlbl 0;
BA_ "SignalType" SG_ 390 AutoBrkngAvlbl "BLN";
BA_ "SignalLongName" SG_ 390 AutoBrkngAvlbl "Automatic Braking Available";
BA_ "VNSigAllNodes" SG_ 390 AutoBrkngAvlbl 1;
BA_ "GenSigSendType" SG_ 390 ABSAutnmsBrkReq 0;
BA_ "SignalType" SG_ 390 ABSAutnmsBrkReq "BLN";
BA_ "SignalLongName" SG_ 390 ABSAutnmsBrkReq "Antilock Brake System Autonomous Braking Request";
BA_ "VNSigAllNodes" SG_ 390 ABSAutnmsBrkReq 1;
BA_ "GenSigSendType" SG_ 390 HlStrAssActIO 0;
BA_ "SignalType" SG_ 390 HlStrAssActIO "BLN";
BA_ "SignalLongName" SG_ 390 HlStrAssActIO "Hill Start Assist Active Indication On";
BA_ "VNSigAllNodes" SG_ 390 HlStrAssActIO 1;
BA_ "GenSigSendType" SG_ 390 ABSActvProt 0;
BA_ "SignalType" SG_ 390 ABSActvProt "BLN";
BA_ "SignalLongName" SG_ 390 ABSActvProt "Antilock Brake System Active Protected";
BA_ "VNSigAllNodes" SG_ 390 ABSActvProt 1;
BA_ "GenSigSendType" SG_ 390 BrkSysAutBrkFld 0;
BA_ "SignalType" SG_ 390 BrkSysAutBrkFld "BLN";
BA_ "SignalLongName" SG_ 390 BrkSysAutBrkFld "Brake System Automatic Braking Failed";
BA_ "VNSigAllNodes" SG_ 390 BrkSysAutBrkFld 1;
BA_ "GenSigSendType" SG_ 390 IntBrkAssPreFilReq 0;
BA_ "SignalType" SG_ 390 IntBrkAssPreFilReq "BLN";
BA_ "SignalLongName" SG_ 390 IntBrkAssPreFilReq "Inteligent Brake Assist Pre-Fil Request";
BA_ "VNSigAllNodes" SG_ 390 IntBrkAssPreFilReq 1;
BA_ "GenSigSendType" SG_ 390 BrkSysMalFuncIndOn 0;
BA_ "SignalType" SG_ 390 BrkSysMalFuncIndOn "BLN";
BA_ "SignalLongName" SG_ 390 BrkSysMalFuncIndOn "Brake System Malfunction Indication On";
BA_ "VNSigAllNodes" SG_ 390 BrkSysMalFuncIndOn 1;
BA_ "GenSigSendType" SG_ 390 IBCPdlStChs 0;
BA_ "SignalType" SG_ 390 IBCPdlStChs "UNM";
BA_ "SignalLongName" SG_ 390 IBCPdlStChs "IBC Pedal Status Checksum";
BA_ "VNSigAllNodes" SG_ 390 IBCPdlStChs 1;
BA_ "GenSigSendType" SG_ 390 BPDAPS_BkPDrvApPV 0;
BA_ "SignalType" SG_ 390 BPDAPS_BkPDrvApPV "ENM";
BA_ "PacketOrder" SG_ 390 BPDAPS_BkPDrvApPV 2;
BA_ "SignalLongName" SG_ 390 BPDAPS_BkPDrvApPV "Brake Pedal Driver Applied Pressure Status : Brake Pedal Driver Applied Pressure Validity";
BA_ "VNSigAllNodes" SG_ 390 BPDAPS_BkPDrvApPV 1;
BA_ "GenSigSendType" SG_ 390 BPDAPS_BkPDrvApP 0;
BA_ "SignalType" SG_ 390 BPDAPS_BkPDrvApP "UNM";
BA_ "PacketOrder" SG_ 390 BPDAPS_BkPDrvApP 1;
BA_ "SignalLongName" SG_ 390 BPDAPS_BkPDrvApP "Brake Pedal Driver Applied Pressure Status : Brake Pedal Driver Applied Pressure";
BA_ "VNSigAllNodes" SG_ 390 BPDAPS_BkPDrvApP 1;
BA_ "GenSigStartValue" SG_ 390 BPDAPS_BkPDrvApP 255;
BA_ "GenSigSendType" SG_ 390 IBCPdlStARC 0;
BA_ "SignalType" SG_ 390 IBCPdlStARC "UNM";
BA_ "SignalLongName" SG_ 390 IBCPdlStARC "IBC Pedal Status Alive Rolling Count";
BA_ "VNSigAllNodes" SG_ 390 IBCPdlStARC 1;
BA_ "GenSigSendType" SG_ 390 BrkFldLvlLwV 0;
BA_ "SignalType" SG_ 390 BrkFldLvlLwV "ENM";
BA_ "SignalLongName" SG_ 390 BrkFldLvlLwV "Brake Fluid Level Low Validity";
BA_ "VNSigAllNodes" SG_ 390 BrkFldLvlLwV 1;
BA_ "GenSigSendType" SG_ 390 AutoBrkngAct 0;
BA_ "SignalType" SG_ 390 AutoBrkngAct "BLN";
BA_ "SignalLongName" SG_ 390 AutoBrkngAct "Automatic Braking Active";
BA_ "VNSigAllNodes" SG_ 390 AutoBrkngAct 1;
BA_ "GenSigSendType" SG_ 390 BrkFldLvlLw 0;
BA_ "SignalType" SG_ 390 BrkFldLvlLw "BLN";
BA_ "SignalLongName" SG_ 390 BrkFldLvlLw "Brake Fluid Level Low";
BA_ "VNSigAllNodes" SG_ 390 BrkFldLvlLw 1;
BA_ "GenSigSendType" SG_ 630 ElecPrkBrkCmdChs 0;
BA_ "SignalType" SG_ 630 ElecPrkBrkCmdChs "UNM";
BA_ "SignalLongName" SG_ 630 ElecPrkBrkCmdChs "Electric Park Brake Command Checksum";
BA_ "VNSigAllNodes" SG_ 630 ElecPrkBrkCmdChs 1;
BA_ "GenSigSendType" SG_ 630 ElecPrkBrkSwStatV 0;
BA_ "SignalType" SG_ 630 ElecPrkBrkSwStatV "ENM";
BA_ "SignalLongName" SG_ 630 ElecPrkBrkSwStatV "Electric Park Brake Switch Status Validity";
BA_ "VNSigAllNodes" SG_ 630 ElecPrkBrkSwStatV 1;
BA_ "GenSigSendType" SG_ 630 ElecPrkBrkCmdARC 0;
BA_ "SignalType" SG_ 630 ElecPrkBrkCmdARC "UNM";
BA_ "SignalLongName" SG_ 630 ElecPrkBrkCmdARC "Electric Park Brake Command Alive Rolling Count";
BA_ "VNSigAllNodes" SG_ 630 ElecPrkBrkCmdARC 1;
BA_ "GenSigSendType" SG_ 630 ElecPrkBrkSwStat 0;
BA_ "SignalType" SG_ 630 ElecPrkBrkSwStat "ENM";
BA_ "SignalLongName" SG_ 630 ElecPrkBrkSwStat "Electric Park Brake Switch Status";
BA_ "VNSigAllNodes" SG_ 630 ElecPrkBrkSwStat 1;
BA_ "GenSigSendType" SG_ 630 AllNodesVNA 0;
BA_ "VNSigSLHS_VNReq" SG_ 630 AllNodesVNA 1;
BA_ "SignalType" SG_ 630 AllNodesVNA "ENM";
BA_ "SignalLongName" SG_ 630 AllNodesVNA "All Nodes Virtual Network Activation";
BA_ "VNSigAllNodes" SG_ 630 AllNodesVNA 1;
BA_ "GenSigSendType" SG_ 630 StpOnBrkToRelPBIndOn 0;
BA_ "SignalType" SG_ 630 StpOnBrkToRelPBIndOn "BLN";
BA_ "SignalLongName" SG_ 630 StpOnBrkToRelPBIndOn "Step On Brake To Release Park Brake Indication On";
BA_ "VNSigAllNodes" SG_ 630 StpOnBrkToRelPBIndOn 1;
BA_ "GenSigSendType" SG_ 630 EPBC_EPBAccRq 0;
BA_ "GenSigStartValue" SG_ 630 EPBC_EPBAccRq 4095;
BA_ "SignalType" SG_ 630 EPBC_EPBAccRq "SNM";
BA_ "PacketOrder" SG_ 630 EPBC_EPBAccRq 2;
BA_ "SignalLongName" SG_ 630 EPBC_EPBAccRq "Electric Park Brake Command : Electric Park Brake Acceleration Requested";
BA_ "VNSigAllNodes" SG_ 630 EPBC_EPBAccRq 1;
BA_ "GenSigSendType" SG_ 630 EPBC_EPBrkAutBrkRq 0;
BA_ "SignalType" SG_ 630 EPBC_EPBrkAutBrkRq "BLN";
BA_ "PacketOrder" SG_ 630 EPBC_EPBrkAutBrkRq 1;
BA_ "SignalLongName" SG_ 630 EPBC_EPBrkAutBrkRq "Electric Park Brake Command : Electric Park Brake Automatic Braking Requested";
BA_ "VNSigAllNodes" SG_ 630 EPBC_EPBrkAutBrkRq 1;
BA_ "GenSigSendType" SG_ 630 EPBSysDspMsgReq 0;
BA_ "SignalType" SG_ 630 EPBSysDspMsgReq "ENM";
BA_ "SignalLongName" SG_ 630 EPBSysDspMsgReq "Electric Park Brake System Display Message Request";
BA_ "VNSigAllNodes" SG_ 630 EPBSysDspMsgReq 1;
BA_ "GenSigSendType" SG_ 630 EPBSysAudWarnReq 0;
BA_ "SignalType" SG_ 630 EPBSysAudWarnReq "ENM";
BA_ "SignalLongName" SG_ 630 EPBSysAudWarnReq "Electric Park Brake System Audible Warning Request";
BA_ "VNSigAllNodes" SG_ 630 EPBSysAudWarnReq 1;
BA_ "GenSigSendType" SG_ 630 ElecPrkBrkStat 0;
BA_ "SignalType" SG_ 630 ElecPrkBrkStat "ENM";
BA_ "SignalLongName" SG_ 630 ElecPrkBrkStat "Electric Park Brake Status";
BA_ "VNSigAllNodes" SG_ 630 ElecPrkBrkStat 1;
BA_ "GenSigSendType" SG_ 630 EPBCrsCanRq 0;
BA_ "SignalType" SG_ 630 EPBCrsCanRq "BLN";
BA_ "SignalLongName" SG_ 630 EPBCrsCanRq "Electric Park Brake Cruise Control Cancel Requested";
BA_ "VNSigAllNodes" SG_ 630 EPBCrsCanRq 1;
BA_ "GenSigSendType" SG_ 630 EPBSysStatIndReq 0;
BA_ "SignalType" SG_ 630 EPBSysStatIndReq "ENM";
BA_ "SignalLongName" SG_ 630 EPBSysStatIndReq "Electric Park Brake System Status Indication Request";
BA_ "VNSigAllNodes" SG_ 630 EPBSysStatIndReq 1;
BA_ "GenSigSendType" SG_ 630 EPBSysWrnIndReq 0;
BA_ "SignalType" SG_ 630 EPBSysWrnIndReq "ENM";
BA_ "SignalLongName" SG_ 630 EPBSysWrnIndReq "Electric Park Brake System Warning Indication Request";
BA_ "VNSigAllNodes" SG_ 630 EPBSysWrnIndReq 1;
BA_ "GenSigSendType" SG_ 630 EPBSysBrkLtsReq 0;
BA_ "SignalType" SG_ 630 EPBSysBrkLtsReq "BLN";
BA_ "SignalLongName" SG_ 630 EPBSysBrkLtsReq "Electric Park Brake System Brake Lights Requested";
BA_ "VNSigAllNodes" SG_ 630 EPBSysBrkLtsReq 1;
BA_ "GenSigSendType" SG_ 1825 DgnInf 1;
BA_ "VNSigSLHSSharedDiagnostic" SG_ 1825 DgnInf 1;
BA_ "SignalType" SG_ 1825 DgnInf "UNM";
BA_ "SignalLongName" SG_ 1825 DgnInf "Diagnostic Information";
BA_ "VNSigAllNodes" SG_ 1825 DgnInf 1;
BA_ "GenSigSendType" SG_ 1502 DgnInf 1;
BA_ "VNSigSLHSSharedDiagnostic" SG_ 1502 DgnInf 1;
BA_ "SignalType" SG_ 1502 DgnInf "UNM";
BA_ "SignalLongName" SG_ 1502 DgnInf "Diagnostic Information";
BA_ "VNSigAllNodes" SG_ 1502 DgnInf 1;
BA_ "GenSigSendType" SG_ 1602 DgnInf 1;
BA_ "VNSigSLHSSharedDiagnostic" SG_ 1602 DgnInf 1;
BA_ "SignalType" SG_ 1602 DgnInf "UNM";
BA_ "SignalLongName" SG_ 1602 DgnInf "Diagnostic Information";
BA_ "VNSigAllNodes" SG_ 1602 DgnInf 1;
BA_ "SignalLongName" SG_ 300 WndscrnWshWtrSt "Windscreen Wash Water State";
BA_ "GenSigSendType" SG_ 300 WndscrnWshWtrSt 0;
BA_ "SignalLongName" SG_ 300 BCUIntLghtSt "BCU Interior Lighting Status";
BA_ "GenSigSendType" SG_ 300 BCUIntLghtSt 0;
BA_ "SignalType" SG_ 300 DrStOccpncV "ENM";
BA_ "SignalLongName" SG_ 300 DrStOccpncV "Driver Seat Occupancy Validity";
BA_ "VNSigAllNodes" SG_ 300 DrStOccpncV 1;
BA_ "GenSigSendType" SG_ 300 DrStOccpncV 0;
BA_ "SignalType" SG_ 300 DrStOccpnc "BLN";
BA_ "SignalLongName" SG_ 300 DrStOccpnc "Driver Seat Occupancy";
BA_ "VNSigAllNodes" SG_ 300 DrStOccpnc 1;
BA_ "GenSigSendType" SG_ 300 DrStOccpnc 0;
BA_ "GenSigSendType" SG_ 300 BCUIntErrSt 0;
BA_ "GenSigStartValue" SG_ 300 BCUIntErrSt 3;
BA_ "SignalLongName" SG_ 300 BCUIntErrSt "BCU Internal Error Status";
BA_ "GenSigSendType" SG_ 300 BrkLtsAtv 0;
BA_ "SignalType" SG_ 300 BrkLtsAtv "BLN";
BA_ "SignalLongName" SG_ 300 BrkLtsAtv "Brake Lights Active";
BA_ "VNSigAllNodes" SG_ 300 BrkLtsAtv 1;
BA_ "GenSigSendType" SG_ 300 RrFogLmpsAct 0;
BA_ "SignalType" SG_ 300 RrFogLmpsAct "BLN";
BA_ "SignalLongName" SG_ 300 RrFogLmpsAct "Rear Fog Lamps Active";
BA_ "VNSigAllNodes" SG_ 300 RrFogLmpsAct 1;
BA_ "GenSigSendType" SG_ 300 TrnSwAct 0;
BA_ "SignalType" SG_ 300 TrnSwAct "ENM";
BA_ "SignalLongName" SG_ 300 TrnSwAct "Turn Switch Activation";
BA_ "VNSigAllNodes" SG_ 300 TrnSwAct 1;
BA_ "GenSigSendType" SG_ 300 OtsdAmbtLtLvlStatV 0;
BA_ "SignalType" SG_ 300 OtsdAmbtLtLvlStatV "ENM";
BA_ "SignalLongName" SG_ 300 OtsdAmbtLtLvlStatV "Outside Ambient Light Level Status Validity";
BA_ "VNSigAllNodes" SG_ 300 OtsdAmbtLtLvlStatV 1;
BA_ "GenSigSendType" SG_ 300 OtsdAmbtLtLvlStat 0;
BA_ "SignalType" SG_ 300 OtsdAmbtLtLvlStat "ENM";
BA_ "SignalLongName" SG_ 300 OtsdAmbtLtLvlStat "Outside Ambient Light Level Status";
BA_ "VNSigAllNodes" SG_ 300 OtsdAmbtLtLvlStat 1;
BA_ "GenSigSendType" SG_ 300 MainLghtSw 0;
BA_ "SignalType" SG_ 300 MainLghtSw "ENM";
BA_ "SignalLongName" SG_ 300 MainLghtSw "Main Light Switch";
BA_ "VNSigAllNodes" SG_ 300 MainLghtSw 1;
BA_ "GenSigSendType" SG_ 300 LowBmAct 0;
BA_ "SignalType" SG_ 300 LowBmAct "BLN";
BA_ "SignalLongName" SG_ 300 LowBmAct "Low Beam Active";
BA_ "VNSigAllNodes" SG_ 300 LowBmAct 1;
BA_ "GenSigSendType" SG_ 300 HighBmAct 0;
BA_ "SignalType" SG_ 300 HighBmAct "BLN";
BA_ "SignalLongName" SG_ 300 HighBmAct "High Beam Active";
BA_ "VNSigAllNodes" SG_ 300 HighBmAct 1;
BA_ "GenSigSendType" SG_ 300 HdlmpBmSelectStat 0;
BA_ "SignalType" SG_ 300 HdlmpBmSelectStat "ENM";
BA_ "SignalLongName" SG_ 300 HdlmpBmSelectStat "Headlamp Beam Select Status";
BA_ "VNSigAllNodes" SG_ 300 HdlmpBmSelectStat 1;
BA_ "GenSigSendType" SG_ 300 FlToPsSwAtv 0;
BA_ "SignalType" SG_ 300 FlToPsSwAtv "BLN";
BA_ "SignalLongName" SG_ 300 FlToPsSwAtv "Flash To Pass Switch Active";
BA_ "VNSigAllNodes" SG_ 300 FlToPsSwAtv 1;
BA_ "GenSigSendType" SG_ 300 FrFogLmpsAct 0;
BA_ "SignalType" SG_ 300 FrFogLmpsAct "BLN";
BA_ "SignalLongName" SG_ 300 FrFogLmpsAct "Front Fog Lamps Active";
BA_ "VNSigAllNodes" SG_ 300 FrFogLmpsAct 1;
BA_ "GenSigSendType" SG_ 300 AutLghtCtrl 0;
BA_ "SignalType" SG_ 300 AutLghtCtrl "BLN";
BA_ "SignalLongName" SG_ 300 AutLghtCtrl "Auto Light Control";
BA_ "VNSigAllNodes" SG_ 300 AutLghtCtrl 1;
BA_ "GenSigSendType" SG_ 300 TCSysDisSwAtvV 0;
BA_ "SignalType" SG_ 300 TCSysDisSwAtvV "ENM";
BA_ "SignalLongName" SG_ 300 TCSysDisSwAtvV "Traction Control System Disable Switch Active Validity";
BA_ "VNSigAllNodes" SG_ 300 TCSysDisSwAtvV 1;
BA_ "GenSigSendType" SG_ 300 TCSysDisSwAtv 0;
BA_ "SignalType" SG_ 300 TCSysDisSwAtv "BLN";
BA_ "SignalLongName" SG_ 300 TCSysDisSwAtv "Traction Control System Disable Switch Active";
BA_ "VNSigAllNodes" SG_ 300 TCSysDisSwAtv 1;
BA_ "GenSigSendType" SG_ 300 WSWprAct 0;
BA_ "SignalType" SG_ 300 WSWprAct "BLN";
BA_ "SignalLongName" SG_ 300 WSWprAct "Windshield Wiper Active";
BA_ "VNSigAllNodes" SG_ 300 WSWprAct 1;
BA_ "GenSigSendType" SG_ 300 WSWshSwAtv 0;
BA_ "SignalType" SG_ 300 WSWshSwAtv "BLN";
BA_ "SignalLongName" SG_ 300 WSWshSwAtv "Windshield Washer Switch Active";
BA_ "VNSigAllNodes" SG_ 300 WSWshSwAtv 1;
BA_ "GenSigSendType" SG_ 300 BCUInfCks 0;
BA_ "SignalLongName" SG_ 300 BCUInfCks "BCU Info Checksum";
BA_ "GenSigSendType" SG_ 300 VhclLckSt 0;
BA_ "SignalLongName" SG_ 300 VhclLckSt "Vehicle Lock State";
BA_ "GenSigSendType" SG_ 300 BCUInfARC 0;
BA_ "SignalType" SG_ 300 BCUInfARC "UNM";
BA_ "SignalLongName" SG_ 300 BCUInfARC "BCU Info Alive Rolling Count";
BA_ "VNSigAllNodes" SG_ 300 BCUInfARC 1;
BA_ "GenSigSendType" SG_ 300 PsSbltAtcV 0;
BA_ "SignalType" SG_ 300 PsSbltAtcV "ENM";
BA_ "SignalLongName" SG_ 300 PsSbltAtcV "Passenger Seatbelt Attached Validity";
BA_ "VNSigAllNodes" SG_ 300 PsSbltAtcV 1;
BA_ "GenSigSendType" SG_ 300 PsSbltAtc 0;
BA_ "SignalType" SG_ 300 PsSbltAtc "BLN";
BA_ "SignalLongName" SG_ 300 PsSbltAtc "Passenger Seatbelt Attached";
BA_ "VNSigAllNodes" SG_ 300 PsSbltAtc 1;
BA_ "GenSigSendType" SG_ 300 DrSbltAtcV 0;
BA_ "SignalType" SG_ 300 DrSbltAtcV "ENM";
BA_ "SignalLongName" SG_ 300 DrSbltAtcV "Driver Seatbelt Attached Validity";
BA_ "VNSigAllNodes" SG_ 300 DrSbltAtcV 1;
BA_ "GenSigSendType" SG_ 300 DrSbltAtc 0;
BA_ "SignalType" SG_ 300 DrSbltAtc "BLN";
BA_ "SignalLongName" SG_ 300 DrSbltAtc "Driver Seatbelt Attached";
BA_ "VNSigAllNodes" SG_ 300 DrSbltAtc 1;
BA_ "GenSigSendType" SG_ 1350 VehIdNmDig2_9 0;
BA_ "SignalType" SG_ 1350 VehIdNmDig2_9 "ASC";
BA_ "SignalLongName" SG_ 1350 VehIdNmDig2_9 "Vehicle Identification Number Digits 2-9";
BA_ "VNSigAllNodes" SG_ 1350 VehIdNmDig2_9 1;
BA_ "GenSigSendType" SG_ 1398 IBCVhclOdmtrCks 0;
BA_ "SignalLongName" SG_ 1398 IBCVhclOdmtrCks "IBC Vehicle Odometer Checksum";
BA_ "GenSigSendType" SG_ 1398 IBCVhclOdmtrARC 0;
BA_ "SignalLongName" SG_ 1398 IBCVhclOdmtrARC "IBC Vehicle Odometer Alive Rolling Count";
BA_ "GenSigSendType" SG_ 1398 VehOdo 0;
BA_ "SignalType" SG_ 1398 VehOdo "UNM";
BA_ "SignalLongName" SG_ 1398 VehOdo "Vehicle Odometer";
BA_ "VNSigAllNodes" SG_ 1398 VehOdo 1;
BA_ "GenSigSendType" SG_ 1398 VehOdoV 0;
BA_ "SignalType" SG_ 1398 VehOdoV "ENM";
BA_ "SignalLongName" SG_ 1398 VehOdoV "Vehicle Odometer Validity";
BA_ "VNSigAllNodes" SG_ 1398 VehOdoV 1;
BA_ "GenSigSendType" SG_ 151 IBCNDrvWhlVlctChs 0;
BA_ "SignalLongName" SG_ 151 IBCNDrvWhlVlctChs "IBC Non Driven Wheel Velocity Checksum";
BA_ "GenSigSendType" SG_ 151 IBCNDrvWhlVlctARC 0;
BA_ "SignalLongName" SG_ 151 IBCNDrvWhlVlctARC "IBC Non Driven Wheel Velocity Alive Rolling Count";
BA_ "GenSigSendType" SG_ 151 WhlRotDrctnlSRtNDrvn 0;
BA_ "SignalType" SG_ 151 WhlRotDrctnlSRtNDrvn "ENM";
BA_ "SignalLongName" SG_ 151 WhlRotDrctnlSRtNDrvn "Wheel Rotational Directional Status Right Non Driven";
BA_ "VNSigAllNodes" SG_ 151 WhlRotDrctnlSRtNDrvn 1;
BA_ "GenSigSendType" SG_ 151 WhlRotDrctnlStLfNDrvn 0;
BA_ "SignalType" SG_ 151 WhlRotDrctnlStLfNDrvn "ENM";
BA_ "SignalLongName" SG_ 151 WhlRotDrctnlStLfNDrvn "Wheel Rotational Directional Status Left Non Driven";
BA_ "VNSigAllNodes" SG_ 151 WhlRotDrctnlStLfNDrvn 1;
BA_ "GenSigSendType" SG_ 151 WhlGrndVlctyRtNnDrvnV 0;
BA_ "SignalType" SG_ 151 WhlGrndVlctyRtNnDrvnV "ENM";
BA_ "SignalLongName" SG_ 151 WhlGrndVlctyRtNnDrvnV "Wheel Ground Velocity Right Non Driven Validity";
BA_ "VNSigAllNodes" SG_ 151 WhlGrndVlctyRtNnDrvnV 1;
BA_ "GenSigSendType" SG_ 151 WhlGrndVlctyRtNnDrvn 0;
BA_ "SignalType" SG_ 151 WhlGrndVlctyRtNnDrvn "UNM";
BA_ "SignalLongName" SG_ 151 WhlGrndVlctyRtNnDrvn "Wheel Ground Velocity Right Non Driven";
BA_ "VNSigAllNodes" SG_ 151 WhlGrndVlctyRtNnDrvn 1;
BA_ "GenSigStartValue" SG_ 151 WhlGrndVlctyRtNnDrvn 16383;
BA_ "GenSigSendType" SG_ 151 WhlGrndVlctyLftNnDrvnV 0;
BA_ "SignalType" SG_ 151 WhlGrndVlctyLftNnDrvnV "ENM";
BA_ "SignalLongName" SG_ 151 WhlGrndVlctyLftNnDrvnV "Wheel Ground Velocity Left Non Driven Validity";
BA_ "VNSigAllNodes" SG_ 151 WhlGrndVlctyLftNnDrvnV 1;
BA_ "GenSigSendType" SG_ 151 WhlGrndVlctyLftNnDrvn 0;
BA_ "SignalType" SG_ 151 WhlGrndVlctyLftNnDrvn "UNM";
BA_ "SignalLongName" SG_ 151 WhlGrndVlctyLftNnDrvn "Wheel Ground Velocity Left Non Driven";
BA_ "VNSigAllNodes" SG_ 151 WhlGrndVlctyLftNnDrvn 1;
BA_ "GenSigStartValue" SG_ 151 WhlGrndVlctyLftNnDrvn 16383;
BA_ "GenSigSendType" SG_ 1888 DgnInf 1;
BA_ "VNSigSLHSSharedDiagnostic" SG_ 1888 DgnInf 1;
BA_ "SignalType" SG_ 1888 DgnInf "UNM";
BA_ "SignalLongName" SG_ 1888 DgnInf "Diagnostic Information";
BA_ "VNSigAllNodes" SG_ 1888 DgnInf 1;
BA_ "GenSigSendType" SG_ 1351 VehIdNmDig10_17 0;
BA_ "SignalType" SG_ 1351 VehIdNmDig10_17 "ASC";
BA_ "SignalLongName" SG_ 1351 VehIdNmDig10_17 "Vehicle Identification Number Digits 10-17";
BA_ "VNSigAllNodes" SG_ 1351 VehIdNmDig10_17 1;
BA_ "GenSigSendType" SG_ 150 IBCDrvWhlVlctChs 0;
BA_ "SignalLongName" SG_ 150 IBCDrvWhlVlctChs "IBC Driven Wheel Velocity Checksum";
BA_ "GenSigSendType" SG_ 150 IBCDrvWhlVlctARC 0;
BA_ "SignalLongName" SG_ 150 IBCDrvWhlVlctARC "IBC Driven Wheel Velocity Alive Rolling Count";
BA_ "GenSigSendType" SG_ 150 WhlRotDrctnlStLftDrvn 0;
BA_ "SignalType" SG_ 150 WhlRotDrctnlStLftDrvn "ENM";
BA_ "SignalLongName" SG_ 150 WhlRotDrctnlStLftDrvn "Wheel Rotational Directional Status Left Driven";
BA_ "VNSigAllNodes" SG_ 150 WhlRotDrctnlStLftDrvn 1;
BA_ "GenSigSendType" SG_ 150 WhlRotDrctnlStRtDrvn 0;
BA_ "SignalType" SG_ 150 WhlRotDrctnlStRtDrvn "ENM";
BA_ "SignalLongName" SG_ 150 WhlRotDrctnlStRtDrvn "Wheel Rotational Directional Status Right Driven";
BA_ "VNSigAllNodes" SG_ 150 WhlRotDrctnlStRtDrvn 1;
BA_ "GenSigSendType" SG_ 150 WhlGrndVlctyRtDrvnV 0;
BA_ "SignalType" SG_ 150 WhlGrndVlctyRtDrvnV "ENM";
BA_ "SignalLongName" SG_ 150 WhlGrndVlctyRtDrvnV "Wheel Ground Velocity Right Driven Validity";
BA_ "VNSigAllNodes" SG_ 150 WhlGrndVlctyRtDrvnV 1;
BA_ "GenSigSendType" SG_ 150 WhlGrndVlctyRtDrvn 0;
BA_ "SignalType" SG_ 150 WhlGrndVlctyRtDrvn "UNM";
BA_ "SignalLongName" SG_ 150 WhlGrndVlctyRtDrvn "Wheel Ground Velocity Right Driven";
BA_ "VNSigAllNodes" SG_ 150 WhlGrndVlctyRtDrvn 1;
BA_ "GenSigStartValue" SG_ 150 WhlGrndVlctyRtDrvn 16383;
BA_ "GenSigSendType" SG_ 150 WhlGrndVlctyLftDrvnV 0;
BA_ "SignalType" SG_ 150 WhlGrndVlctyLftDrvnV "ENM";
BA_ "SignalLongName" SG_ 150 WhlGrndVlctyLftDrvnV "Wheel Ground Velocity Left Driven Validity";
BA_ "VNSigAllNodes" SG_ 150 WhlGrndVlctyLftDrvnV 1;
BA_ "GenSigSendType" SG_ 150 WhlGrndVlctyLftDrvn 0;
BA_ "SignalType" SG_ 150 WhlGrndVlctyLftDrvn "UNM";
BA_ "SignalLongName" SG_ 150 WhlGrndVlctyLftDrvn "Wheel Ground Velocity Left Driven";
BA_ "VNSigAllNodes" SG_ 150 WhlGrndVlctyLftDrvn 1;
BA_ "GenSigStartValue" SG_ 150 WhlGrndVlctyLftDrvn 16383;
BA_ "GenSigSendType" SG_ 355 TC1Chs 0;
BA_ "SignalType" SG_ 355 TC1Chs "UNM";
BA_ "SignalLongName" SG_ 355 TC1Chs "Traction Control 1 Checksum";
BA_ "VNSigAllNodes" SG_ 355 TC1Chs 1;
BA_ "GenSigSendType" SG_ 355 CSETRER_TorqReqVal 0;
BA_ "SignalType" SG_ 355 CSETRER_TorqReqVal "UNM";
BA_ "PacketOrder" SG_ 355 CSETRER_TorqReqVal 2;
BA_ "SignalLongName" SG_ 355 CSETRER_TorqReqVal "Chassis System Engine Torque Request Extended Range : Torque Request Value";
BA_ "VNSigAllNodes" SG_ 355 CSETRER_TorqReqVal 1;
BA_ "GenSigStartValue" SG_ 355 CSETRER_TorqReqVal 32767;
BA_ "GenSigSendType" SG_ 355 CSETRER_TqIntvnTyp 0;
BA_ "SignalType" SG_ 355 CSETRER_TqIntvnTyp "ENM";
BA_ "PacketOrder" SG_ 355 CSETRER_TqIntvnTyp 1;
BA_ "SignalLongName" SG_ 355 CSETRER_TqIntvnTyp "Chassis System Engine Torque Request Extended Range : Torque Intervention Type";
BA_ "VNSigAllNodes" SG_ 355 CSETRER_TqIntvnTyp 1;
BA_ "GenSigSendType" SG_ 355 TracCntrlMaxTorqIncRt 0;
BA_ "SignalType" SG_ 355 TracCntrlMaxTorqIncRt "UNM";
BA_ "SignalLongName" SG_ 355 TracCntrlMaxTorqIncRt "Traction Control Maximum Torque Increase Rate";
BA_ "GenSigStartValue" SG_ 355 TracCntrlMaxTorqIncRt 63;
BA_ "VNSigAllNodes" SG_ 355 TracCntrlMaxTorqIncRt 1;
BA_ "GenSigSendType" SG_ 355 TC1ARC 0;
BA_ "SignalType" SG_ 355 TC1ARC "UNM";
BA_ "SignalLongName" SG_ 355 TC1ARC "Traction Control 1 Alive Rolling Count";
BA_ "VNSigAllNodes" SG_ 355 TC1ARC 1;
BA_ "GenSigSendType" SG_ 355 ChsSysEngTrqReqProt 0;
BA_ "SignalType" SG_ 355 ChsSysEngTrqReqProt "UNM";
BA_ "SignalLongName" SG_ 355 ChsSysEngTrqReqProt "Chassis System Engine Torque Request Protection";
BA_ "VNSigAllNodes" SG_ 355 ChsSysEngTrqReqProt 1;
BA_ "GenSigSendType" SG_ 360 EnhDrvMdSwChUseRq 0;
BA_ "SignalType" SG_ 360 EnhDrvMdSwChUseRq "BLN";
BA_ "SignalLongName" SG_ 360 EnhDrvMdSwChUseRq "Enhanced Driver Selected Mode Switch Chassis Use Requested";
BA_ "VNSigAllNodes" SG_ 360 EnhDrvMdSwChUseRq 1;
BA_ "GenSigSendType" SG_ 360 IMUDataMsk 0;
BA_ "SignalType" SG_ 360 IMUDataMsk "BLN";
BA_ "SignalLongName" SG_ 360 IMUDataMsk "Inertial Measurement Unit Data Mask";
BA_ "VNSigAllNodes" SG_ 360 IMUDataMsk 1;
BA_ "GenSigSendType" SG_ 360 DrvIndpntBrkAppAct 0;
BA_ "SignalType" SG_ 360 DrvIndpntBrkAppAct "BLN";
BA_ "SignalLongName" SG_ 360 DrvIndpntBrkAppAct "Driver Independent Brake Apply Active";
BA_ "VNSigAllNodes" SG_ 360 DrvIndpntBrkAppAct 1;
BA_ "GenSigSendType" SG_ 360 WhlSlpSt 0;
BA_ "SignalType" SG_ 360 WhlSlpSt "ENM";
BA_ "SignalLongName" SG_ 360 WhlSlpSt "Wheel Slip Status";
BA_ "VNSigAllNodes" SG_ 360 WhlSlpSt 1;
BA_ "GenSigSendType" SG_ 360 BSTGRReqdGear 0;
BA_ "SignalType" SG_ 360 BSTGRReqdGear "ENM";
BA_ "PacketOrder" SG_ 360 BSTGRReqdGear 2;
BA_ "SignalLongName" SG_ 360 BSTGRReqdGear "Brake System Transmission Gear Request : Requested Gear";
BA_ "VNSigAllNodes" SG_ 360 BSTGRReqdGear 1;
BA_ "GenSigSendType" SG_ 360 BSTGRReqType 0;
BA_ "SignalType" SG_ 360 BSTGRReqType "ENM";
BA_ "PacketOrder" SG_ 360 BSTGRReqType 1;
BA_ "SignalLongName" SG_ 360 BSTGRReqType "Brake System Transmission Gear Request : Request Type";
BA_ "VNSigAllNodes" SG_ 360 BSTGRReqType 1;
BA_ "GenSigSendType" SG_ 360 VehDynOvrUndrStr 0;
BA_ "GenSigStartValue" SG_ 360 VehDynOvrUndrStr 1023;
BA_ "SignalType" SG_ 360 VehDynOvrUndrStr "SNM";
BA_ "SignalLongName" SG_ 360 VehDynOvrUndrStr "Vehicle Dynamics Over Under Steer";
BA_ "VNSigAllNodes" SG_ 360 VehDynOvrUndrStr 1;
BA_ "GenSigSendType" SG_ 360 VSELatAccV 0;
BA_ "SignalType" SG_ 360 VSELatAccV "ENM";
BA_ "SignalLongName" SG_ 360 VSELatAccV "Vehicle Stability Enhancement Lateral Acceleration Validity";
BA_ "VNSigAllNodes" SG_ 360 VSELatAccV 1;
BA_ "GenSigSendType" SG_ 360 VSELatAcc 0;
BA_ "SignalType" SG_ 360 VSELatAcc "SNM";
BA_ "SignalLongName" SG_ 360 VSELatAcc "Vehicle Stability Enhancement Lateral Acceleration";
BA_ "GenSigStartValue" SG_ 360 VSELatAcc 4095;
BA_ "VNSigAllNodes" SG_ 360 VSELatAcc 1;
BA_ "GenSigSendType" SG_ 360 VSEAct 0;
BA_ "SignalType" SG_ 360 VSEAct "BLN";
BA_ "SignalLongName" SG_ 360 VSEAct "Vehicle Stability Enhancement System Active";
BA_ "VNSigAllNodes" SG_ 360 VSEAct 1;
BA_ "GenSigSendType" SG_ 360 VhDynCntlSysSt 0;
BA_ "SignalType" SG_ 360 VhDynCntlSysSt "ENM";
BA_ "SignalLongName" SG_ 360 VhDynCntlSysSt "Vehicle Dynamics Control System Status";
BA_ "VNSigAllNodes" SG_ 360 VhDynCntlSysSt 1;
BA_ "GenSigSendType" SG_ 360 VehDynYawRateV 0;
BA_ "SignalType" SG_ 360 VehDynYawRateV "ENM";
BA_ "SignalLongName" SG_ 360 VehDynYawRateV "Vehicle Dynamics Yaw Rate Validity";
BA_ "VNSigAllNodes" SG_ 360 VehDynYawRateV 1;
BA_ "GenSigSendType" SG_ 360 VehDynYawRate 0;
BA_ "GenSigStartValue" SG_ 360 VehDynYawRate 4095;
BA_ "SignalType" SG_ 360 VehDynYawRate "SNM";
BA_ "SignalLongName" SG_ 360 VehDynYawRate "Vehicle Dynamics Yaw Rate";
BA_ "VNSigAllNodes" SG_ 360 VehDynYawRate 1;
BA_ "GenSigSendType" SG_ 360 TrnsBrkSysCltchRelRqd 0;
BA_ "SignalType" SG_ 360 TrnsBrkSysCltchRelRqd "BLN";
BA_ "SignalLongName" SG_ 360 TrnsBrkSysCltchRelRqd "Transmission Brake System Clutch Release Requested";
BA_ "VNSigAllNodes" SG_ 360 TrnsBrkSysCltchRelRqd 1;
BA_ "GenSigSendType" SG_ 360 TracCntrlSysDrIntnt 0;
BA_ "SignalType" SG_ 360 TracCntrlSysDrIntnt "ENM";
BA_ "SignalLongName" SG_ 360 TracCntrlSysDrIntnt "Traction Control System Driver Intent";
BA_ "VNSigAllNodes" SG_ 360 TracCntrlSysDrIntnt 1;
BA_ "GenSigSendType" SG_ 360 VehDynOvrUndrStrV 0;
BA_ "SignalType" SG_ 360 VehDynOvrUndrStrV "ENM";
BA_ "SignalLongName" SG_ 360 VehDynOvrUndrStrV "Vehicle Dynamics Over Under Steer Validity";
BA_ "VNSigAllNodes" SG_ 360 VehDynOvrUndrStrV 1;
BA_ "GenSigSendType" SG_ 360 TCSysEnbld 0;
BA_ "SignalType" SG_ 360 TCSysEnbld "BLN";
BA_ "SignalLongName" SG_ 360 TCSysEnbld "Traction Control System Enabled";
BA_ "VNSigAllNodes" SG_ 360 TCSysEnbld 1;
BA_ "GenSigSendType" SG_ 360 TCSysAtv 0;
BA_ "SignalType" SG_ 360 TCSysAtv "BLN";
BA_ "SignalLongName" SG_ 360 TCSysAtv "Traction Control System Active";
BA_ "VNSigAllNodes" SG_ 360 TCSysAtv 1;
BA_ "GenSigSendType" SG_ 360 BrkPdlDrvAppPrsDetcdV 0;
BA_ "SignalType" SG_ 360 BrkPdlDrvAppPrsDetcdV "ENM";
BA_ "SignalLongName" SG_ 360 BrkPdlDrvAppPrsDetcdV "Brake Pedal Driver Applied Pressure Detected Validity";
BA_ "VNSigAllNodes" SG_ 360 BrkPdlDrvAppPrsDetcdV 1;
BA_ "GenSigSendType" SG_ 360 BrkPdlDrvAppPrsDetcd 0;
BA_ "SignalType" SG_ 360 BrkPdlDrvAppPrsDetcd "BLN";
BA_ "SignalLongName" SG_ 360 BrkPdlDrvAppPrsDetcd "Brake Pedal Driver Applied Pressure Detected";
BA_ "GenSigStartValue" SG_ 360 BrkPdlDrvAppPrsDetcd 1;
BA_ "VNSigAllNodes" SG_ 360 BrkPdlDrvAppPrsDetcd 1;
BA_ "GenSigSendType" SG_ 360 ACCBrkngAct 0;
BA_ "SignalType" SG_ 360 ACCBrkngAct "BLN";
BA_ "SignalLongName" SG_ 360 ACCBrkngAct "Adaptive Cruise Control Braking Active";
BA_ "VNSigAllNodes" SG_ 360 ACCBrkngAct 1;
BA_ "GenSigSendType" SG_ 360 ABSFld 0;
BA_ "SignalType" SG_ 360 ABSFld "BLN";
BA_ "SignalLongName" SG_ 360 ABSFld "Antilock Brake System Failed";
BA_ "VNSigAllNodes" SG_ 360 ABSFld 1;
BA_ "GenSigSendType" SG_ 360 ABSAtv 0;
BA_ "SignalType" SG_ 360 ABSAtv "BLN";
BA_ "SignalLongName" SG_ 360 ABSAtv "Antilock Brake System Active";
BA_ "VNSigAllNodes" SG_ 360 ABSAtv 1;
BA_ "GenSigSendType" SG_ 350 IBCABSStChs 0;
BA_ "SignalLongName" SG_ 350 IBCABSStChs "IBC ABS Status Checksum";
BA_ "GenSigSendType" SG_ 350 IBCABSStARC 0;
BA_ "SignalLongName" SG_ 350 IBCABSStARC "IBC ABS Status Alive Rolling Count";
BA_ "GenSigSendType" SG_ 350 HillDesCtrlRedVehSpIO 0;
BA_ "SignalType" SG_ 350 HillDesCtrlRedVehSpIO "BLN";
BA_ "SignalLongName" SG_ 350 HillDesCtrlRedVehSpIO "Hill Descent Control Reduce Vehicle Speed Indication On";
BA_ "VNSigAllNodes" SG_ 350 HillDesCtrlRedVehSpIO 1;
BA_ "GenSigSendType" SG_ 350 EBDFailed 0;
BA_ "SignalType" SG_ 350 EBDFailed "BLN";
BA_ "SignalLongName" SG_ 350 EBDFailed "Electronic Brake Distribution Failed";
BA_ "VNSigAllNodes" SG_ 350 EBDFailed 1;
BA_ "GenSigSendType" SG_ 350 StWhAnVDA 0;
BA_ "SignalType" SG_ 350 StWhAnVDA "ENM";
BA_ "SignalLongName" SG_ 350 StWhAnVDA "Steering Wheel Angle Virtual Device Availability";
BA_ "GenSigStartValue" SG_ 350 StWhAnVDA 1;
BA_ "VNSigAllNodes" SG_ 350 StWhAnVDA 1;
BA_ "GenSigSendType" SG_ 350 TirePrsLowIO 0;
BA_ "SignalType" SG_ 350 TirePrsLowIO "BLN";
BA_ "SignalLongName" SG_ 350 TirePrsLowIO "Tire Pressure Low Indication On";
BA_ "VNSigAllNodes" SG_ 350 TirePrsLowIO 1;
BA_ "GenSigSendType" SG_ 350 VaccBoostFailure 0;
BA_ "SignalType" SG_ 350 VaccBoostFailure "BLN";
BA_ "SignalLongName" SG_ 350 VaccBoostFailure "Vaccum Boost Failure";
BA_ "VNSigAllNodes" SG_ 350 VaccBoostFailure 1;
BA_ "GenSigSendType" SG_ 350 VSESysPrs 0;
BA_ "SignalType" SG_ 350 VSESysPrs "BLN";
BA_ "SignalLongName" SG_ 350 VSESysPrs "Vehicle Stability Enhancement System Present";
BA_ "VNSigAllNodes" SG_ 350 VSESysPrs 1;
BA_ "GenSigSendType" SG_ 350 HalfSysFail 0;
BA_ "SignalType" SG_ 350 HalfSysFail "BLN";
BA_ "SignalLongName" SG_ 350 HalfSysFail "Half System Failure";
BA_ "VNSigAllNodes" SG_ 350 HalfSysFail 1;
BA_ "GenSigSendType" SG_ 350 ActVehAccel 0;
BA_ "GenSigStartValue" SG_ 350 ActVehAccel 4095;
BA_ "SignalType" SG_ 350 ActVehAccel "SNM";
BA_ "SignalLongName" SG_ 350 ActVehAccel "Actual Vehicle Acceleration";
BA_ "VNSigAllNodes" SG_ 350 ActVehAccel 1;
BA_ "GenSigSendType" SG_ 350 ActVehAccelV 0;
BA_ "SignalType" SG_ 350 ActVehAccelV "ENM";
BA_ "SignalLongName" SG_ 350 ActVehAccelV "Actual Vehicle Acceleration Validity";
BA_ "VNSigAllNodes" SG_ 350 ActVehAccelV 1;
BA_ "GenSigSendType" SG_ 350 BksOvht 0;
BA_ "SignalType" SG_ 350 BksOvht "BLN";
BA_ "SignalLongName" SG_ 350 BksOvht "Brakes Overheated";
BA_ "VNSigAllNodes" SG_ 350 BksOvht 1;
BA_ "GenSigSendType" SG_ 350 TCSysPr 0;
BA_ "SignalType" SG_ 350 TCSysPr "BLN";
BA_ "SignalLongName" SG_ 350 TCSysPr "Traction Control System Present";
BA_ "VNSigAllNodes" SG_ 350 TCSysPr 1;
BA_ "GenSigSendType" SG_ 350 ABSPr 0;
BA_ "SignalType" SG_ 350 ABSPr "BLN";
BA_ "SignalLongName" SG_ 350 ABSPr "Antilock Brake System Present";
BA_ "VNSigAllNodes" SG_ 350 ABSPr 1;
BA_ "GenSigSendType" SG_ 350 TreInfMonSysRstPrfmd 0;
BA_ "SignalType" SG_ 350 TreInfMonSysRstPrfmd "BLN";
BA_ "SignalLongName" SG_ 350 TreInfMonSysRstPrfmd "Tire Inflation Monitoring System Reset Performed";
BA_ "VNSigAllNodes" SG_ 350 TreInfMonSysRstPrfmd 1;
BA_ "GenSigSendType" SG_ 350 ABSIO 0;
BA_ "SignalType" SG_ 350 ABSIO "BLN";
BA_ "SignalLongName" SG_ 350 ABSIO "Antilock Brake System Indication On";
BA_ "VNSigAllNodes" SG_ 350 ABSIO 1;
BA_ "GenSigSendType" SG_ 350 BrkPadWrnIO 0;
BA_ "SignalType" SG_ 350 BrkPadWrnIO "BLN";
BA_ "SignalLongName" SG_ 350 BrkPadWrnIO "Brake Pad Worn Indication On";
BA_ "VNSigAllNodes" SG_ 350 BrkPadWrnIO 1;
BA_ "GenSigSendType" SG_ 350 VehStabEnhmntMd 0;
BA_ "SignalType" SG_ 350 VehStabEnhmntMd "ENM";
BA_ "SignalLongName" SG_ 350 VehStabEnhmntMd "Vehicle Stability Enhancement Mode";
BA_ "VNSigAllNodes" SG_ 350 VehStabEnhmntMd 1;
BA_ "GenSigSendType" SG_ 350 VehStabEnhmntStat 0;
BA_ "SignalType" SG_ 350 VehStabEnhmntStat "ENM";
BA_ "SignalLongName" SG_ 350 VehStabEnhmntStat "Vehicle Stability Enhancement Status";
BA_ "VNSigAllNodes" SG_ 350 VehStabEnhmntStat 1;
BA_ "GenSigSendType" SG_ 350 TCSysOpMd 0;
BA_ "SignalType" SG_ 350 TCSysOpMd "ENM";
BA_ "SignalLongName" SG_ 350 TCSysOpMd "Traction Control System Operating Mode";
BA_ "VNSigAllNodes" SG_ 350 TCSysOpMd 1;
BA_ "GenSigSendType" SG_ 350 TCSysOpStat 0;
BA_ "SignalType" SG_ 350 TCSysOpStat "ENM";
BA_ "SignalLongName" SG_ 350 TCSysOpStat "Traction Control System Operating Status";
BA_ "VNSigAllNodes" SG_ 350 TCSysOpStat 1;
BA_ "GenSigSendType" SG_ 350 BrkSysVTopSpdLimVal 0;
BA_ "SignalType" SG_ 350 BrkSysVTopSpdLimVal "UNM";
BA_ "SignalLongName" SG_ 350 BrkSysVTopSpdLimVal "Braking System Vehicle Top Speed Limit Value";
BA_ "GenSigStartValue" SG_ 350 BrkSysVTopSpdLimVal 255;
BA_ "VNSigAllNodes" SG_ 350 BrkSysVTopSpdLimVal 1;
BA_ "GenSigSendType" SG_ 350 BrkSysRedBrkTlltlReq 0;
BA_ "SignalType" SG_ 350 BrkSysRedBrkTlltlReq "BLN";
BA_ "SignalLongName" SG_ 350 BrkSysRedBrkTlltlReq "Brake System Red Brake Telltale Request";
BA_ "VNSigAllNodes" SG_ 350 BrkSysRedBrkTlltlReq 1;
BA_ "GenSigSendType" SG_ 350 BrkSysBrkLtsReqd 0;
BA_ "SignalType" SG_ 350 BrkSysBrkLtsReqd "BLN";
BA_ "SignalLongName" SG_ 350 BrkSysBrkLtsReqd "Brake System Brake Lights Requested";
BA_ "VNSigAllNodes" SG_ 350 BrkSysBrkLtsReqd 1;
BA_ "GenSigSendType" SG_ 157 IBCBrkApStChs 0;
BA_ "SignalLongName" SG_ 157 IBCBrkApStChs "IBC Brake Apply Status Checksum";
BA_ "GenSigSendType" SG_ 157 NotEventStat 0;
BA_ "SignalType" SG_ 157 NotEventStat "ENM";
BA_ "SignalLongName" SG_ 157 NotEventStat "Notification Event Status";
BA_ "VNSigAllNodes" SG_ 157 NotEventStat 1;
BA_ "GenSigSendType" SG_ 157 BrkPdlChkData 0;
BA_ "SignalType" SG_ 157 BrkPdlChkData "UNM";
BA_ "SignalLongName" SG_ 157 BrkPdlChkData "Brake Pedal Check Data";
BA_ "VNSigAllNodes" SG_ 157 BrkPdlChkData 1;
BA_ "GenSigSendType" SG_ 157 BrkAppSnsrHmPosLrnd 0;
BA_ "SignalType" SG_ 157 BrkAppSnsrHmPosLrnd "BLN";
BA_ "SignalLongName" SG_ 157 BrkAppSnsrHmPosLrnd "Brake Apply Sensor Home Position Learned";
BA_ "VNSigAllNodes" SG_ 157 BrkAppSnsrHmPosLrnd 1;
BA_ "GenSigSendType" SG_ 157 BrkPedTrvlAchvd 0;
BA_ "SignalType" SG_ 157 BrkPedTrvlAchvd "BLN";
BA_ "PacketOrder" SG_ 157 BrkPedTrvlAchvd 1;
BA_ "SignalLongName" SG_ 157 BrkPedTrvlAchvd "Brake Pedal Initial Travel Achieved Status : Brake Pedal Initial Travel Achieved";
BA_ "VNSigAllNodes" SG_ 157 BrkPedTrvlAchvd 1;
BA_ "GenSigSendType" SG_ 157 BrkPedTrvlAchvdV 0;
BA_ "SignalType" SG_ 157 BrkPedTrvlAchvdV "ENM";
BA_ "PacketOrder" SG_ 157 BrkPedTrvlAchvdV 2;
BA_ "SignalLongName" SG_ 157 BrkPedTrvlAchvdV "Brake Pedal Initial Travel Achieved Status : Brake Pedal Initial Travel Achieved Validity";
BA_ "VNSigAllNodes" SG_ 157 BrkPedTrvlAchvdV 1;
BA_ "GenSigSendType" SG_ 157 BrkPdlPosGrad 0;
BA_ "GenSigStartValue" SG_ 157 BrkPdlPosGrad 255;
BA_ "SignalType" SG_ 157 BrkPdlPosGrad "SNM";
BA_ "SignalLongName" SG_ 157 BrkPdlPosGrad "Brake Pedal Position Gradient";
BA_ "VNSigAllNodes" SG_ 157 BrkPdlPosGrad 1;
BA_ "GenSigSendType" SG_ 157 BrkPdlPos 0;
BA_ "SignalType" SG_ 157 BrkPdlPos "UNM";
BA_ "SignalLongName" SG_ 157 BrkPdlPos "Brake Pedal Position";
BA_ "VNSigAllNodes" SG_ 157 BrkPdlPos 1;
BA_ "GenSigSendType" SG_ 157 IBCBrApStARC 0;
BA_ "SignalType" SG_ 157 IBCBrApStARC "UNM";
BA_ "SignalLongName" SG_ 157 IBCBrApStARC "IBC Brake Apply Status Alive Rolling Count";
BA_ "VNSigAllNodes" SG_ 157 IBCBrApStARC 1;
BA_ "GenSigSendType" SG_ 157 BrkPdlModTrvlV 0;
BA_ "SignalType" SG_ 157 BrkPdlModTrvlV "ENM";
BA_ "SignalLongName" SG_ 157 BrkPdlModTrvlV "Brake Pedal Moderate Travel Achieved Validity";
BA_ "VNSigAllNodes" SG_ 157 BrkPdlModTrvlV 1;
BA_ "GenSigSendType" SG_ 157 BrkPdlModTrvl 0;
BA_ "SignalType" SG_ 157 BrkPdlModTrvl "BLN";
BA_ "SignalLongName" SG_ 157 BrkPdlModTrvl "Brake Pedal Moderate Travel Achieved";
BA_ "VNSigAllNodes" SG_ 157 BrkPdlModTrvl 1;
BA_ "GenSigSendType" SG_ 157 BrkPdlInTrvPrt 0;
BA_ "SignalType" SG_ 157 BrkPdlInTrvPrt "UNM";
BA_ "SignalLongName" SG_ 157 BrkPdlInTrvPrt "Brake Pedal Initial Travel Achieved Protection";
BA_ "VNSigAllNodes" SG_ 157 BrkPdlInTrvPrt 1;
BA_ "GenSigSendType" SG_ 1833 DgnInf 1;
BA_ "VNSigSLHSSharedDiagnostic" SG_ 1833 DgnInf 1;
BA_ "SignalType" SG_ 1833 DgnInf "UNM";
BA_ "SignalLongName" SG_ 1833 DgnInf "Diagnostic Information";
BA_ "VNSigAllNodes" SG_ 1833 DgnInf 1;
BA_REL_ "GenSigSuprvResp" BU_SG_REL_ IBC SG_ 300 BCUInfARC 1;
BA_REL_ "GenSigTimeoutMsg" BU_SG_REL_ IBC SG_ 300 BCUInfARC 298;
BA_REL_ "GenSigTimeoutTime" BU_SG_REL_ IBC SG_ 300 BCUInfARC 250;
BA_REL_ "GenSigSuprvResp" BU_SG_REL_ IBC SG_ 300 PsSbltAtc 1;
BA_REL_ "GenSigTimeoutMsg" BU_SG_REL_ IBC SG_ 300 PsSbltAtc 298;
BA_REL_ "GenSigTimeoutTime" BU_SG_REL_ IBC SG_ 300 PsSbltAtc 250;
BA_REL_ "GenSigSuprvResp" BU_SG_REL_ IBC SG_ 1350 VehIdNmDig2_9 1;
BA_REL_ "GenSigTimeoutMsg" BU_SG_REL_ IBC SG_ 1350 VehIdNmDig2_9 1300;
BA_REL_ "GenSigTimeoutTime" BU_SG_REL_ IBC SG_ 1350 VehIdNmDig2_9 2500;
BA_REL_ "GenSigSuprvResp" BU_SG_REL_ IBC SG_ 1351 VehIdNmDig10_17 1;
BA_REL_ "GenSigTimeoutMsg" BU_SG_REL_ IBC SG_ 1351 VehIdNmDig10_17 1249;
BA_REL_ "GenSigTimeoutTime" BU_SG_REL_ IBC SG_ 1351 VehIdNmDig10_17 2500;
VAL_ 177 AccPdlPstn 1023 "sna" 1022 "error" ;
VAL_ 766 Fct_Int_Flag_HV_emergency 3 "SNA" 2 "ERROR" 1 "INTERVENTION" 0 "NO INTERVENTION" ;
VAL_ 766 Fct_Int_Flag_shifter 3 "SNA" 2 "ERROR" 1 "INTERVENTION" 0 "NO INTERVENTION" ;
VAL_ 766 Fct_Int_Flag_throttle 3 "SNA" 2 "ERROR" 1 "INTERVENTION" 0 "NO INTERVENTION" ;
VAL_ 766 eLCVDADDrvRqSt 15 "sna" 14 "error" 5 "Autonomous Drive" 4 "Failure" 3 "Shutdown" 2 "Inhibit" 1 "Active" 0 "Init" ;
VAL_ 162 Fct_Int_Flag_EPS 3 "SNA" 2 "ERROR" 1 "INTERVENTION" 0 "NO INTERVENTION" ;
VAL_ 107 Fct_Int_Flag_ECD 3 "SNA" 2 "ERROR" 1 "INTERVENTION" 0 "NO INTERVENTION" ;
VAL_ 107 Fct_Int_Flag_ESC 3 "SNA" 2 "ERROR" 1 "INTERVENTION" 0 "NO INTERVENTION" ;
VAL_ 107 Fct_Int_Flag_TC 3 "SNA" 2 "ERROR" 1 "INTERVENTION" 0 "NO INTERVENTION" ;
VAL_ 107 Fct_Int_Flag_ABS 3 "SNA" 2 "ERROR" 1 "INTERVENTION" 0 "NO INTERVENTION" ;
VAL_ 107 Fct_Int_Flag_stabilization 3 "SNA" 2 "ERROR" 1 "INTERVENTION" 0 "NO INTERVENTION" ;
VAL_ 107 Fct_Int_Flag_brake_emergency 3 "SNA" 2 "ERROR" 1 "INTERVENTION" 0 "NO INTERVENTION" ;
VAL_ 107 Fct_Int_Flag_EPB_button 3 "SNA" 2 "ERROR" 1 "INTERVENTION" 0 "NO INTERVENTION" ;
VAL_ 107 Fct_Int_Flag_brake_pedal 3 "SNA" 2 "ERROR" 1 "INTERVENTION" 0 "NO INTERVENTION" ;
VAL_ 99 DM_LDW 3 "High" 2 "Medium" 1 "Low" 0 "Off" ;
VAL_ 99 DM_SFS 4 "Level_5" 3 "Level_4" 2 "Level_3" 1 "Level_2" 0 "Level_1" ;
VAL_ 99 DM_AD_Activation_Clamp 3 "SNA" 2 "ERROR" 1 "ON" 0 "OFF" ;
VAL_ 99 DM_Mode_AD_HMI 4 "AD ERROR" 3 "AD MEAS ON" 2 "AD ON" 1 "AD READY" 0 "AD OFF" ;
VAL_ 101 VCUADYwTrqRqRrVldt 1 "Invalid" 0 "Valid" ;
VAL_ 101 VCUADYwTrqRqFrtVldt 1 "Invalid" 0 "Valid" ;
VAL_ 800 ExTirePressSupport 3 "Not Available/Not Supported" 2 "Error" 1 "Using Extended Tire Pressure" 0 "Not Using Extended Tire Pressure" ;
VAL_ 800 TirePressThresholdDetection_13 7 "NotAvailable" 6 "ErrorIndicator" 5 "NotDefined" 4 "ExtrmUndrPrssTrPrssrIsAtALvlWhr" 3 "UndrPrssTrPrssrIsLwrThnThPrssrD" 2 "NWrnngPrssTrPrssrIsWthnThThrshl" 1 "OvrPrssTrPrssrIsHghrThnThPrssrD" 0 "ExtrmOvrPrssTrPrssrIsAtALvlWhrT" ;
VAL_ 800 TirePressThresholdDetection_12 7 "NotAvailable" 6 "ErrorIndicator" 5 "NotDefined" 4 "ExtrmUndrPrssTrPrssrIsAtALvlWhr" 3 "UndrPrssTrPrssrIsLwrThnThPrssrD" 2 "NWrnngPrssTrPrssrIsWthnThThrshl" 1 "OvrPrssTrPrssrIsHghrThnThPrssrD" 0 "ExtrmOvrPrssTrPrssrIsAtALvlWhrT" ;
VAL_ 800 TirePressThresholdDetection_11 7 "NotAvailable" 6 "ErrorIndicator" 5 "NotDefined" 4 "ExtrmUndrPrssTrPrssrIsAtALvlWhr" 3 "UndrPrssTrPrssrIsLwrThnThPrssrD" 2 "NWrnngPrssTrPrssrIsWthnThThrshl" 1 "OvrPrssTrPrssrIsHghrThnThPrssrD" 0 "ExtrmOvrPrssTrPrssrIsAtALvlWhrT" ;
VAL_ 800 TirePressThresholdDetection_10 7 "NotAvailable" 6 "ErrorIndicator" 5 "NotDefined" 4 "ExtrmUndrPrssTrPrssrIsAtALvlWhr" 3 "UndrPrssTrPrssrIsLwrThnThPrssrD" 2 "NWrnngPrssTrPrssrIsWthnThThrshl" 1 "OvrPrssTrPrssrIsHghrThnThPrssrD" 0 "ExtrmOvrPrssTrPrssrIsAtALvlWhrT" ;
VAL_ 800 TirePressThresholdDetection_01 7 "NotAvailable" 6 "ErrorIndicator" 5 "NotDefined" 4 "ExtrmUndrPrssTrPrssrIsAtALvlWhr" 3 "UndrPrssTrPrssrIsLwrThnThPrssrD" 2 "NWrnngPrssTrPrssrIsWthnThThrshl" 1 "OvrPrssTrPrssrIsHghrThnThPrssrD" 0 "ExtrmOvrPrssTrPrssrIsAtALvlWhrT" ;
VAL_ 800 CTIWheelSensorStatus_33 3 "NotSupported" 2 "NotDefined" 1 "On" 0 "Off_IsolatedFromCTIPressCtrl" ;
VAL_ 800 CTIWheelSensorStatus_32 3 "NotSupported" 2 "NotDefined" 1 "On" 0 "Off_IsolatedFromCTIPressCtrl" ;
VAL_ 800 CTIWheelSensorStatus_31 3 "NotSupported" 2 "NotDefined" 1 "On" 0 "Off_IsolatedFromCTIPressCtrl" ;
VAL_ 800 CTIWheelSensorStatus_30 3 "NotSupported" 2 "NotDefined" 1 "On" 0 "Off_IsolatedFromCTIPressCtrl" ;
VAL_ 800 CTIWheelSensorStatus_23 3 "NotSupported" 2 "NotDefined" 1 "On" 0 "Off_IsolatedFromCTIPressCtrl" ;
VAL_ 800 CTIWheelSensorStatus_22 3 "NotSupported" 2 "NotDefined" 1 "On" 0 "Off_IsolatedFromCTIPressCtrl" ;
VAL_ 800 CTIWheelSensorStatus_21 3 "NotSupported" 2 "NotDefined" 1 "On" 0 "Off_IsolatedFromCTIPressCtrl" ;
VAL_ 800 CTIWheelSensorStatus_20 3 "NotSupported" 2 "NotDefined" 1 "On" 0 "Off_IsolatedFromCTIPressCtrl" ;
VAL_ 800 CTIWheelSensorStatus_13 3 "NotSupported" 2 "NotDefined" 1 "On" 0 "Off_IsolatedFromCTIPressCtrl" ;
VAL_ 800 CTIWheelSensorStatus_12 3 "NotSupported" 2 "NotDefined" 1 "On" 0 "Off_IsolatedFromCTIPressCtrl" ;
VAL_ 800 CTIWheelSensorStatus_11 3 "NotSupported" 2 "NotDefined" 1 "On" 0 "Off_IsolatedFromCTIPressCtrl" ;
VAL_ 800 CTIWheelSensorStatus_10 3 "NotSupported" 2 "NotDefined" 1 "On" 0 "Off_IsolatedFromCTIPressCtrl" ;
VAL_ 800 CTIWheelSensorStatus_01 3 "NotSupported" 2 "NotDefined" 1 "On" 0 "Off_IsolatedFromCTIPressCtrl" ;
VAL_ 800 CTIWheelEndElectricalFault_33 3 "NotSupported" 2 "Error" 1 "NotDefined" 0 "Ok" ;
VAL_ 800 CTIWheelEndElectricalFault_32 3 "NotSupported" 2 "Error" 1 "NotDefined" 0 "Ok" ;
VAL_ 800 CTIWheelEndElectricalFault_31 3 "NotSupported" 2 "Error" 1 "NotDefined" 0 "Ok" ;
VAL_ 800 CTIWheelEndElectricalFault_30 3 "NotSupported" 2 "Error" 1 "NotDefined" 0 "Ok" ;
VAL_ 800 CTIWheelEndElectricalFault_23 3 "NotSupported" 2 "Error" 1 "NotDefined" 0 "Ok" ;
VAL_ 800 CTIWheelEndElectricalFault_22 3 "NotSupported" 2 "Error" 1 "NotDefined" 0 "Ok" ;
VAL_ 800 CTIWheelEndElectricalFault_21 3 "NotSupported" 2 "Error" 1 "NotDefined" 0 "Ok" ;
VAL_ 800 CTIWheelEndElectricalFault_20 3 "NotSupported" 2 "Error" 1 "NotDefined" 0 "Ok" ;
VAL_ 800 CTIWheelEndElectricalFault_13 3 "NotSupported" 2 "Error" 1 "NotDefined" 0 "Ok" ;
VAL_ 800 CTIWheelEndElectricalFault_12 3 "NotSupported" 2 "Error" 1 "NotDefined" 0 "Ok" ;
VAL_ 800 CTIWheelEndElectricalFault_11 3 "NotSupported" 2 "Error" 1 "NotDefined" 0 "Ok" ;
VAL_ 800 CTIWheelEndElectricalFault_10 3 "NotSupported" 2 "Error" 1 "NotDefined" 0 "Ok" ;
VAL_ 800 CTIWheelEndElectricalFault_01 3 "NotSupported" 2 "Error" 1 "NotDefined" 0 "Ok" ;
VAL_ 800 CTITireStatus_33 3 "NotSupported" 2 "Error" 1 "TireLeakDetected" 0 "Ok" ;
VAL_ 800 CTITireStatus_32 3 "NotSupported" 2 "Error" 1 "TireLeakDetected" 0 "Ok" ;
VAL_ 800 CTITireStatus_31 3 "NotSupported" 2 "Error" 1 "TireLeakDetected" 0 "Ok" ;
VAL_ 800 CTITireStatus_30 3 "NotSupported" 2 "Error" 1 "TireLeakDetected" 0 "Ok" ;
VAL_ 800 CTITireStatus_23 3 "NotSupported" 2 "Error" 1 "TireLeakDetected" 0 "Ok" ;
VAL_ 800 CTITireStatus_22 3 "NotSupported" 2 "Error" 1 "TireLeakDetected" 0 "Ok" ;
VAL_ 800 CTITireStatus_21 3 "NotSupported" 2 "Error" 1 "TireLeakDetected" 0 "Ok" ;
VAL_ 800 CTITireStatus_20 3 "NotSupported" 2 "Error" 1 "TireLeakDetected" 0 "Ok" ;
VAL_ 800 CTITireStatus_13 3 "NotSupported" 2 "Error" 1 "TireLeakDetected" 0 "Ok" ;
VAL_ 800 CTITireStatus_12 3 "NotSupported" 2 "Error" 1 "TireLeakDetected" 0 "Ok" ;
VAL_ 800 CTITireStatus_11 3 "NotSupported" 2 "Error" 1 "TireLeakDetected" 0 "Ok" ;
VAL_ 800 CTITireStatus_10 3 "NotSupported" 2 "Error" 1 "TireLeakDetected" 0 "Ok" ;
VAL_ 800 CTITireStatus_01 3 "NotSupported" 2 "Error" 1 "TireLeakDetected" 0 "Ok" ;
VAL_ 800 TirePressThresholdDetection_33 7 "NotAvailable" 6 "ErrorIndicator" 5 "NotDefined" 4 "ExtrmUndrPrssTrPrssrIsAtALvlWhr" 3 "UndrPrssTrPrssrIsLwrThnThPrssrD" 2 "NWrnngPrssTrPrssrIsWthnThThrshl" 1 "OvrPrssTrPrssrIsHghrThnThPrssrD" 0 "ExtrmOvrPrssTrPrssrIsAtALvlWhrT" ;
VAL_ 800 TirePressThresholdDetection_32 7 "NotAvailable" 6 "ErrorIndicator" 5 "NotDefined" 4 "ExtrmUndrPrssTrPrssrIsAtALvlWhr" 3 "UndrPrssTrPrssrIsLwrThnThPrssrD" 2 "NWrnngPrssTrPrssrIsWthnThThrshl" 1 "OvrPrssTrPrssrIsHghrThnThPrssrD" 0 "ExtrmOvrPrssTrPrssrIsAtALvlWhrT" ;
VAL_ 800 TirePressThresholdDetection_31 7 "NotAvailable" 6 "ErrorIndicator" 5 "NotDefined" 4 "ExtrmUndrPrssTrPrssrIsAtALvlWhr" 3 "UndrPrssTrPrssrIsLwrThnThPrssrD" 2 "NWrnngPrssTrPrssrIsWthnThThrshl" 1 "OvrPrssTrPrssrIsHghrThnThPrssrD" 0 "ExtrmOvrPrssTrPrssrIsAtALvlWhrT" ;
VAL_ 800 TirePressThresholdDetection_30 7 "NotAvailable" 6 "ErrorIndicator" 5 "NotDefined" 4 "ExtrmUndrPrssTrPrssrIsAtALvlWhr" 3 "UndrPrssTrPrssrIsLwrThnThPrssrD" 2 "NWrnngPrssTrPrssrIsWthnThThrshl" 1 "OvrPrssTrPrssrIsHghrThnThPrssrD" 0 "ExtrmOvrPrssTrPrssrIsAtALvlWhrT" ;
VAL_ 800 TirePressThresholdDetection_23 7 "NotAvailable" 6 "ErrorIndicator" 5 "NotDefined" 4 "ExtrmUndrPrssTrPrssrIsAtALvlWhr" 3 "UndrPrssTrPrssrIsLwrThnThPrssrD" 2 "NWrnngPrssTrPrssrIsWthnThThrshl" 1 "OvrPrssTrPrssrIsHghrThnThPrssrD" 0 "ExtrmOvrPrssTrPrssrIsAtALvlWhrT" ;
VAL_ 800 TirePressThresholdDetection_22 7 "NotAvailable" 6 "ErrorIndicator" 5 "NotDefined" 4 "ExtrmUndrPrssTrPrssrIsAtALvlWhr" 3 "UndrPrssTrPrssrIsLwrThnThPrssrD" 2 "NWrnngPrssTrPrssrIsWthnThThrshl" 1 "OvrPrssTrPrssrIsHghrThnThPrssrD" 0 "ExtrmOvrPrssTrPrssrIsAtALvlWhrT" ;
VAL_ 800 TirePressThresholdDetection_21 7 "NotAvailable" 6 "ErrorIndicator" 5 "NotDefined" 4 "ExtrmUndrPrssTrPrssrIsAtALvlWhr" 3 "UndrPrssTrPrssrIsLwrThnThPrssrD" 2 "NWrnngPrssTrPrssrIsWthnThThrshl" 1 "OvrPrssTrPrssrIsHghrThnThPrssrD" 0 "ExtrmOvrPrssTrPrssrIsAtALvlWhrT" ;
VAL_ 800 TirePressThresholdDetection_20 7 "NotAvailable" 6 "ErrorIndicator" 5 "NotDefined" 4 "ExtrmUndrPrssTrPrssrIsAtALvlWhr" 3 "UndrPrssTrPrssrIsLwrThnThPrssrD" 2 "NWrnngPrssTrPrssrIsWthnThThrshl" 1 "OvrPrssTrPrssrIsHghrThnThPrssrD" 0 "ExtrmOvrPrssTrPrssrIsAtALvlWhrT" ;
VAL_ 800 TirePressThresholdDetection_00 7 "NotAvailable" 6 "ErrorIndicator" 5 "NotDefined" 4 "ExtrmUndrPrssTrPrssrIsAtALvlWhr" 3 "UndrPrssTrPrssrIsLwrThnThPrssrD" 2 "NWrnngPrssTrPrssrIsWthnThThrshl" 1 "OvrPrssTrPrssrIsHghrThnThPrssrD" 0 "ExtrmOvrPrssTrPrssrIsAtALvlWhrT" ;
VAL_ 800 CTIWheelSensorStatus_00 3 "NotSupported" 2 "NotDefined" 1 "On" 0 "Off_IsolatedFromCTIPressCtrl" ;
VAL_ 800 CTIWheelEndElectricalFault_00 3 "NotSupported" 2 "Error" 1 "NotDefined" 0 "Ok" ;
VAL_ 800 CTITireStatus_00 3 "NotSupported" 2 "Error" 1 "TireLeakDetected" 0 "Ok" ;
VAL_ 800 TireLocation 51 "TirePress_33_MUX_51" 50 "TirePress_32_MUX_50" 49 "TirePress_31_MUX_49" 48 "TirePress_30_MUX_48" 35 "TirePress_23_MUX_35" 34 "TirePress_22_MUX_34" 33 "TirePress_21_MUX_33" 32 "TirePress_20_MUX_32" 19 "TirePress_13_MUX_19" 18 "TirePress_12_MUX_18" 17 "TirePress_11_MUX_17" 16 "TirePress_10_MUX_16" 1 "TirePress_01_MUX_1" 0 "TirePress_00_MUX_0" ;
VAL_ 160 StrWhlAngSenCalStat 2 "Calibrated" 1 "Estimated" 0 "Unknown" ;
VAL_ 160 StrWhAngGrd 4095 "sna" 4094 "error" ;
VAL_ 160 StrWhAng 65535 "sna" 65534 "error" ;
VAL_ 1000 TM_PTcoolingFluidTempOutlet 255 "sna" 254 "error (sensor defect)" ;
VAL_ 1000 TM_PTcoolingFluidTempInlet 255 "sna" 254 "error (sensor defect)" ;
VAL_ 1000 TM_ESScoolingFluidTempOutlet 255 "sna" 254 "error (sensor defect)" ;
VAL_ 1000 TM_ESScoolingFluidTempInlet 255 "sna" 254 "error (sensor defect)" ;
VAL_ 1000 TM_PassengerCabineAirTemperature 255 "sna" 254 "error (sensor defect)" ;
VAL_ 1000 TM_DriverCabineAirTemperature 255 "sna" 254 "error (sensor defect)" ;
VAL_ 1000 TM_AmbientAirTemperature 255 "sna" 254 "error (sensor defect)" ;
VAL_ 544 Checksum_220 0 "Init" ;
VAL_ 544 MessageCounter_220 0 "Init" ;
VAL_ 544 DC1_VoltageHV 1023 "Failure" 1022 "Init" ;
VAL_ 544 DC1_CurrentLV 2047 "Failure" 2046 "Init" ;
VAL_ 544 DC1_Mode 7 "Failure" 6 "Init" 4 "Precharge" 0 "Off" 1 "Buck" 2 "Boost" 3 "UdcLnkDischarge" ;
VAL_ 544 DC1_CurrentHV 2047 "Failure" 2046 "Init" ;
VAL_ 544 DC1_Temp 254 "Init" 255 "Error" ;
VAL_ 544 DC1_VoltageLV 511 "Failure" 510 "Init" ;
VAL_ 306 CCUCLacc 1 "active" 0 "not active" ;
VAL_ 306 CCUCL15L 1 "active" 0 "not active" ;
VAL_ 306 CCUCL50 1 "active" 0 "not active" ;
VAL_ 306 CCUCL15 1 "active" 0 "not active" ;
VAL_ 111 VCU_EPS_AC_Demand 524287 "sna" 524286 "error" ;
VAL_ 111 VCU_EPS_AC_Request 1 "Active" 0 "Not Active" ;
VAL_ 110 VCU_EPS_TO_Demand_Direction 1 "Negative" 0 "Positive" ;
VAL_ 110 VCU_EPS_TO_Demand 1023 "sna" 1022 "error" ;
VAL_ 110 VCU_EPS_TO_Request 1 "Active" 0 "Not Active" ;
VAL_ 167 EPSSWA 65535 "sna" 65534 "error" ;
VAL_ 167 EPSFltrdVhclSpd 2047 "sna" 2046 "error" ;
VAL_ 166 EPSDrvrTrqCld 2047 "sna" 2046 "error" ;
VAL_ 166 EPSMtrTrqEstmt 2047 "sna" 2046 "error" ;
VAL_ 166 EPSMtrVlct 65535 "sna" 65534 "error" ;
VAL_ 161 EPSLdwFdbk 3 "High_Active" 2 "Medium_Active" 1 "Low_Active" 0 "Inactive" ;
VAL_ 161 EPSSfsFdbk 5 "Default_Active" 4 "Level_5_Active" 3 "Level_4_Active" 2 "Level_3_Active" 1 "Level_2_Active" 0 "Level_1_Active" ;
VAL_ 161 SPCMtrTrqDmndLmtd 1 "MOT_Limited" 0 "MOT_NotLimited" ;
VAL_ 161 SPCAngVlctRqstLmtd 1 "SPC_Limited" 0 "SPC_NotLimited" ;
VAL_ 161 SPCAngRqstLmtd 1 "SPC_Limited" 0 "SPC_NotLimited" ;
VAL_ 161 SPCTrqRqstLmtd 1 "SPC_Limited" 0 "SPC_NotLimited" ;
VAL_ 161 EPSIntErrSt 3 "sna" 2 "red" 1 "yellow" 0 "green" ;
VAL_ 161 EPSDrvStrIntfrDtcd 3 "sna" 2 "error" 1 "true" 0 "false" ;
VAL_ 161 EPSDgrdtnLvl 127 "sna" 126 "error" ;
VAL_ 161 EPSAssstAvlbl 3 "EPS_Failed" 2 "EPS_Shutdown" 1 "EPS_Normal_Operation" 0 "EPS_Init" ;
VAL_ 161 EPSAnglCtrlIntrfcSt 4 "Permanently failed" 0 "init" 1 "Temp inhibit" 2 "Available for control" 3 "Active" ;
VAL_ 161 EPSHndsOnDtctn 1 "DriverHandsNotOnWheel" 0 "DriverHandsOnWheel" ;
VAL_ 161 EPSTrqOvrlyIntfcSt 3 "Permanently Failed" 2 "Temporarily Limited" 1 "Active" 0 "Inactive" ;
VAL_ 161 EPSDrvrTrq 2047 "sna" 2046 "error" ;
VAL_ 357 GlobalRealTimeGSVALID 1 "Valid" 0 "Invalid" ;
VAL_ 357 VhclDrctnlStCOG 0 "Unknown" 1 "Forward" 2 "Reverse" 3 "Not Supported" 4 "Failed" 5 "Reserved 1" 6 "Reserved 2" 7 "Reserved 3" ;
VAL_ 357 VhclVlctCOGV 1 "Invalid" 0 "Valid" ;
VAL_ 357 VhStndDtc 1 "Standstill detected" 0 "Driving" ;
VAL_ 375 IBCADCOGLtPsVldt 3 "sna" 2 "error" 1 "Invalid" 0 "Valid" ;
VAL_ 375 IBCADCOGLngPsVldt 3 "sna" 2 "error" 1 "Invalid" 0 "Valid" ;
VAL_ 375 IBCADVhclWghtVldt 3 "sna" 2 "error" 1 "Invalid" 0 "Valid" ;
VAL_ 100 VCUADSsmMd 3 "n/a" 2 "Hold" 1 "Apply park brake" 0 "No standstill request" ;
VAL_ 100 VCUADBrkRqMd 3 "n/a" 2 "Brake per torque" 1 "Brake per deceleration" 0 "No braking" ;
VAL_ 100 VCUADBrkChc 1 "Emergency" 0 "Normal" ;
VAL_ 100 VCUADTrqRqVldt 1 "Invalid" 0 "Valid" ;
VAL_ 100 VCUADaRqVldt 1 "Invalid" 0 "Valid" ;
VAL_ 105 IBCADMnAvBrkTrq 65535 "sna" 65534 "error" ;
VAL_ 105 IBCADMxAvBrkTrq 65535 "sna" 65534 "error" ;
VAL_ 105 IBCADYwRqSt 15 "sna" 14 "error" 5 "Autonomous Drive" 4 "Failure" 3 "Shutdown" 2 "Inhibit" 1 "Active" 0 "Init" ;
VAL_ 105 IBCADBrkRqSt 15 "sna" 14 "error" 5 "Autonomous Drive" 4 "Failure" 3 "Shutdown" 2 "Inhibit" 1 "Active" 0 "Init" ;
VAL_ 777 eLCVDDrvTrqRq 2047 "sna" 2046 "error" ;
VAL_ 783 CAN_PLock_EmgPathVolt 255 "SNA" 254 "ERROR" ;
VAL_ 783 CAN_PLock_EmgDiagState 7 "SNA" 6 "ERROR" 5 "NDEF" 4 "NA" 3 "FAULT" 2 "FINISH" 1 "ACTIVE" 0 "IDLE" ;
VAL_ 783 CAN_PLock_EmgPathState 3 "SNA" 2 "ERROR" 1 "CLOSE" 0 "OPEN" ;
VAL_ 783 CAN_PLock_AdaptDataSens_high 1023 "SNA" 1022 "ERROR" ;
VAL_ 783 CAN_PLock_AdaptDataSens_low 1023 "SNA" 1022 "ERROR" ;
VAL_ 783 CAN_PLock_Adapted 1 "TRUE" 0 "FALSE" ;
VAL_ 783 CAN_PLock_ActCurr 255 "SNA" 254 "ERROR" ;
VAL_ 783 CAN_PLock_SensVolt 255 "SNA" 254 "ERROR" ;
VAL_ 783 CAN_PLock_State 15 "SNA" 14 "ERROR" 4 "DISENGANGING" 3 "DISENGAGED" 2 "ENGAGING" 1 "ENGAGED" 0 "IDLE" ;
VAL_ 776 INV9_EMOperatingModeIndication 14 "error" 15 "sna" 8 "ChargeFromZero" 7 "InverterInhibit" 6 "Offsetangle-Adaption-Acknowledge" 3 "VoltageMode" 2 "SpeedMode(TrqLimit)" 1 "TorqueMode" 0 "Standby" ;
VAL_ 776 INV9_EMTorqueMinAvailable 8191 "sna" 8190 "error" ;
VAL_ 776 INV9_EMTorqueMaxAvailable 8191 "sna" 8190 "error" ;
VAL_ 770 INV3_INVDeratingIndication 32768 "Derating_ErrMeasurment" 65535 "sna" 65534 "error" 512 "Derating_FreqNorm" 256 "Derating_VoltNorm" 4 "Derating_Pulse" 128 "Derating_FreqMax" 64 "Derating_VoltMax" 32 "Derating_Coolant" 16 "Derating_PCB" 8 "Derating_DCB" 2 "Derating_Default" 1 "Derating_TakeUp" 0 "No_Derating" ;
VAL_ 770 INV3_ECUModeIndication 14 "error" 15 "sna" 5 "init failure" 4 "shutdown" 3 "afterrun" 2 "command mode (run)" 1 "precharge" 0 "initialisation" ;
VAL_ 770 INV3_EMDeratingIndication 65535 "sna" 65534 "error" 16384 "derating Pdc" 8192 "derating time" 4096 "derating Iphase" 2048 "derating swing" 1024 "derating specfied" 512 "derating temperature EM rotor" 256 "derating temperature EM stator" 128 "derating torque (neg)" 64 "derating torque (pos)" 32 "derating DC current (neg)" 16 "derating DC current (pos)" 8 "derating speed (neg)" 4 "derating speed (pos)" 2 "derating DC voltage (max)" 1 "derating DC voltage (min)" 0 "no derating" ;
VAL_ 768 INV1_EMSpeedIndication 65535 "sna" 65534 "error" ;
VAL_ 768 INV1_EMTorqueIndication 16383 "sna" 16382 "error" ;
VAL_ 778 eLCVDRegenBrkAxTorqCapDec 1 "error" 0 "sna" ;
VAL_ 778 eLCVDRegenBrkAxTorqCapAcc 16383 "sna" 16382 "error" ;
VAL_ 778 eLCVDRegenBrkAxTrqAch 32767 "sna" 32766 "error" ;
VAL_ 780 eLCVDRlsdShftPos 7 "sna" 6 "error" 3 "P" 2 "R" 1 "D" 0 "N" ;
VAL_ 780 eLCVDActShftPos 7 "sna" 6 "error" 3 "P" 2 "R" 1 "D" 0 "N" ;
VAL_ 1402 IBCIntErrSt 3 "sna" 2 "red" 1 "yellow" 0 "green" ;
VAL_ 256 IBCRegenBrkSt 3 "sna" 2 "error" 1 "active" 0 "passive" ;
VAL_ 256 IBCRegenBrkAxTrqRqst 1 "error" 0 "sna" ;
VAL_ 850 IMUProtYawRtM 0 "Don't Use Data" 1 "Use Data" ;
VAL_ 850 IMUProtYawRt 4095 "sna" 4094 "error" ;
VAL_ 850 IMUProtLonAccM 0 "Don't Use Data" 1 "Use Data" ;
VAL_ 850 IMUProtLonAcc 1023 "sna" 1022 "error" ;
VAL_ 850 IMUProtLatAccM 0 "Don't Use Data" 1 "Use Data" ;
VAL_ 850 IMUProtLatAcc 4095 "sna" 4094 "error" ;
VAL_ 363 ChsBrkPdlPsERltdV 1 "Invalid" 0 "Valid" ;
VAL_ 363 DrvIntndTtlBrkTrq 16383 "sna" 16382 "error" ;
VAL_ 631 ElecPrkBrkAvailStat 7 "Unused and Reserved 3" 6 "Unused and Reserved 2" 5 "Unused and Reserved 1" 4 "Unavailable, Failed other" 3 "Unavailable, Failed Released" 2 "Unavailable, Failed Applied" 1 "Available, Not Failed" 0 "Unavailable, Not Failed" ;
VAL_ 631 ElecPrkBrkApplStat 3 "Park Brake Application in Progress" 2 "Park brake Released" 1 "Park Brake Applied" 0 "Unknown" ;
VAL_ 631 PrtdEPBSwStat 2 "Apply" 1 "Release" 0 "Not Active" ;
VAL_ 356 AdptDrvrSeatStng 7 "Performance Mode 7" 6 "Performance Mode 6" 5 "Performance Mode 5" 4 "Performance Mode 4" 3 "Performance Mode 3" 2 "Performance Mode 2" 1 "Performance Mode 1" 0 "No Action" ;
VAL_ 356 AdptPsngrSeatStng 7 "Performance Mode 7" 6 "Performance Mode 6" 5 "Performance Mode 5" 4 "Performance Mode 4" 3 "Performance Mode 3" 2 "Performance Mode 2" 1 "Performance Mode 1" 0 "No Action" ;
VAL_ 356 TnDrvTrCtrlOffUnbIO 1 "true" 0 "false" ;
VAL_ 356 TnDrvStblCtrlOffUnbIO 1 "true" 0 "false" ;
VAL_ 356 VehRollAngleV 1 "Invalid" 0 "Valid" ;
VAL_ 356 VehRollAngle 127 "sna" 126 "error" ;
VAL_ 356 VehPitchAngleV 1 "Invalid" 0 "Valid" ;
VAL_ 356 VehPitchAngle 127 "sna" 126 "error" ;
VAL_ 356 RdWhlAngV 1 "Invalid" 0 "Valid" ;
VAL_ 356 RdWhlAng 127 "sna" 126 "error" ;
VAL_ 356 PerfTrcCrnExStngVal 0 "No Action" 1 "Off" 2 "Setting 1" 3 "Setting 2" 4 "Setting 3" 5 "Setting 4" 6 "Setting 5" 7 "Setting 6" 8 "Setting 7" 9 "Setting 8" 10 "Setting 9" 11 "Setting 10" 12 "Setting 11" 13 "Setting 12" 14 "Setting 13" 15 "Setting 14" 16 "Setting 15" ;
VAL_ 368 VSELongAccLoResV 1 "Invalid" 0 "Valid" ;
VAL_ 368 VSELongAccLoRes 1023 "sna" 1022 "error" ;
VAL_ 368 StrAngSnsPolRat 0 "Not Passed" 1 "Passed" ;
VAL_ 368 LatAccSnsPolRat 0 "Not Passed" 1 "Passed" ;
VAL_ 390 RedntVSEAct 1 "true" 0 "false" ;
VAL_ 390 HilRlbkCtrlActIO 1 "true" 0 "false" ;
VAL_ 390 AutoBrkngAvlbl 1 "true" 0 "false" ;
VAL_ 390 ABSAutnmsBrkReq 1 "true" 0 "false" ;
VAL_ 390 HlStrAssActIO 1 "true" 0 "false" ;
VAL_ 390 ABSActvProt 1 "true" 0 "false" ;
VAL_ 390 BrkSysAutBrkFld 1 "true" 0 "false" ;
VAL_ 390 IntBrkAssPreFilReq 1 "true" 0 "false" ;
VAL_ 390 BrkSysMalFuncIndOn 1 "true" 0 "false" ;
VAL_ 390 BPDAPS_BkPDrvApPV 1 "Invalid" 0 "Valid" ;
VAL_ 390 BPDAPS_BkPDrvApP 255 "sna" 254 "error" ;
VAL_ 390 BrkFldLvlLwV 1 "Invalid" 0 "Valid" ;
VAL_ 390 AutoBrkngAct 1 "true" 0 "false" ;
VAL_ 390 BrkFldLvlLw 1 "true" 0 "false" ;
VAL_ 630 ElecPrkBrkSwStatV 1 "Invalid" 0 "Valid" ;
VAL_ 630 ElecPrkBrkSwStat 2 "Apply" 1 "Release" 0 "NotActive" ;
VAL_ 630 AllNodesVNA 1 "Activate Virtual Network" 0 "No Activation" ;
VAL_ 630 StpOnBrkToRelPBIndOn 1 "true" 0 "false" ;
VAL_ 630 EPBC_EPBAccRq 4095 "sna" 4094 "error" ;
VAL_ 630 EPBC_EPBrkAutBrkRq 1 "true" 0 "false" ;
VAL_ 630 EPBSysDspMsgReq 7 "Message #7" 6 "Message #6" 5 "Message #5" 4 "Message #4" 3 "Message #3" 2 "Message #2" 1 "Message #1" 0 "Off" ;
VAL_ 630 EPBSysAudWarnReq 2 "Warning #2" 1 "Warning #1" 0 "Off" ;
VAL_ 630 ElecPrkBrkStat 2 "Fault" 1 "Applied" 0 "Released" ;
VAL_ 630 EPBCrsCanRq 1 "true" 0 "false" ;
VAL_ 630 EPBSysStatIndReq 3 "Flash Rate 2 Indication" 2 "Flash Rate 1 Indication" 1 "Continuous Indication" 0 "No Indication" ;
VAL_ 630 EPBSysWrnIndReq 3 "Flash Rate #2 Indication" 2 "Flash Rate #1 Indication" 1 "Continuous Indication" 0 "No Indication" ;
VAL_ 630 EPBSysBrkLtsReq 1 "true" 0 "false" ;
VAL_ 300 WndscrnWshWtrSt 1 "not empty" 0 "empty" ;
VAL_ 300 BCUIntLghtSt 3 "sna" 2 "on" 1 "dimmed" 0 "off" ;
VAL_ 300 DrStOccpncV 1 "Invalid" 0 "Valid" ;
VAL_ 300 DrStOccpnc 1 "true" 0 "false" ;
VAL_ 300 BCUIntErrSt 3 "sna" 2 "red" 1 "yellow" 0 "green" ;
VAL_ 300 BrkLtsAtv 1 "true" 0 "false" ;
VAL_ 300 RrFogLmpsAct 1 "true" 0 "false" ;
VAL_ 300 TrnSwAct 3 "Hazard Lights" 2 "Right" 1 "Left" 0 "No Activation" ;
VAL_ 300 OtsdAmbtLtLvlStatV 1 "Invalid" 0 "Valid" ;
VAL_ 300 OtsdAmbtLtLvlStat 2 "Day" 1 "Night" 0 "Unknown" ;
VAL_ 300 MainLghtSw 3 "HEADLAMP" 2 "PARKLAMP" 1 "OFF" 0 "AUTO" ;
VAL_ 300 LowBmAct 1 "true" 0 "false" ;
VAL_ 300 HighBmAct 1 "true" 0 "false" ;
VAL_ 300 HdlmpBmSelectStat 2 "High Beams" 1 "Low Beams" 0 "Unknown" ;
VAL_ 300 FlToPsSwAtv 1 "true" 0 "false" ;
VAL_ 300 FrFogLmpsAct 1 "true" 0 "false" ;
VAL_ 300 AutLghtCtrl 1 "true" 0 "false" ;
VAL_ 300 TCSysDisSwAtvV 1 "Invalid" 0 "Valid" ;
VAL_ 300 TCSysDisSwAtv 1 "true" 0 "false" ;
VAL_ 300 WSWprAct 1 "true" 0 "false" ;
VAL_ 300 WSWshSwAtv 1 "true" 0 "false" ;
VAL_ 300 VhclLckSt 1 "locked" 0 "unlocked" ;
VAL_ 300 PsSbltAtcV 1 "Invalid" 0 "Valid" ;
VAL_ 300 PsSbltAtc 1 "true" 0 "false" ;
VAL_ 300 DrSbltAtcV 1 "Invalid" 0 "Valid" ;
VAL_ 300 DrSbltAtc 1 "true" 0 "false" ;
VAL_ 1398 VehOdoV 1 "Invalid" 0 "Valid" ;
VAL_ 151 WhlRotDrctnlSRtNDrvn 0 "Unknown" 1 "Forward" 2 "Reverse" 3 "Not Supported" 4 "Failed" 5 "Reserved 1" 6 "Reserved 2" 7 "Reserved 3" ;
VAL_ 151 WhlRotDrctnlStLfNDrvn 0 "Unknown" 1 "Forward" 2 "Reverse" 3 "Not Supported" 4 "Failed" 5 "Reserved 1" 6 "Reserved 2" 7 "Reserved 3" ;
VAL_ 151 WhlGrndVlctyRtNnDrvnV 1 "Invalid" 0 "Valid" ;
VAL_ 151 WhlGrndVlctyRtNnDrvn 16383 "sna" 16382 "error" ;
VAL_ 151 WhlGrndVlctyLftNnDrvnV 1 "Invalid" 0 "Valid" ;
VAL_ 151 WhlGrndVlctyLftNnDrvn 16383 "sna" 16382 "error" ;
VAL_ 150 WhlRotDrctnlStLftDrvn 0 "Unknown" 1 "Forward" 2 "Reverse" 3 "Not Supported" 4 "Failed" 5 "Reserved 1" 6 "Reserved 2" 7 "Reserved 3" ;
VAL_ 150 WhlRotDrctnlStRtDrvn 0 "Unknown" 1 "Forward" 2 "Reverse" 3 "Not Supported" 4 "Failed" 5 "Reserved 1" 6 "Reserved 2" 7 "Reserved 3" ;
VAL_ 150 WhlGrndVlctyRtDrvnV 1 "Invalid" 0 "Valid" ;
VAL_ 150 WhlGrndVlctyRtDrvn 16383 "sna" 16382 "error" ;
VAL_ 150 WhlGrndVlctyLftDrvnV 1 "Invalid" 0 "Valid" ;
VAL_ 150 WhlGrndVlctyLftDrvn 16383 "sna" 16382 "error" ;
VAL_ 355 CSETRER_TorqReqVal 32767 "sna" 32766 "error" ;
VAL_ 355 CSETRER_TqIntvnTyp 2 "Increase Torque" 1 "Reduce Torque" 0 "No Intervention" ;
VAL_ 355 TracCntrlMaxTorqIncRt 63 "sna" 62 "error" ;
VAL_ 360 EnhDrvMdSwChUseRq 1 "true" 0 "false" ;
VAL_ 360 IMUDataMsk 1 "true" 0 "false" ;
VAL_ 360 DrvIndpntBrkAppAct 1 "true" 0 "false" ;
VAL_ 360 WhlSlpSt 3 "Slip Detection Fault" 2 "Positive Slip Detected" 1 "Negative Slip Detected" 0 "No Slip Detected" ;
VAL_ 360 BSTGRReqdGear 8 "Eighth Gear" 7 "Seventh Gear" 6 "Sixth Gear" 5 "Fifth Gear" 4 "Fourth Gear" 3 "Third Gear" 2 "Second Gear" 1 "First Gear" 0 "No Action" ;
VAL_ 360 BSTGRReqType 3 "Hold Gear" 2 "Min Gear Request" 1 "Max Gear Request" 0 "No Action" ;
VAL_ 360 VehDynOvrUndrStr 1023 "sna" 1022 "error" ;
VAL_ 360 VSELatAccV 1 "Invalid" 0 "Valid" ;
VAL_ 360 VSELatAcc 4095 "sna" 4094 "error" ;
VAL_ 360 VSEAct 1 "true" 0 "false" ;
VAL_ 360 VhDynCntlSysSt 7 "Driver Disabled" 6 "Enhanced Operation" 5 "Calibrating" 4 "Warming Up" 3 "Permanently Failed" 2 "Temporarily Inhibited" 1 "Reduced Function" 0 "Normal Operation" ;
VAL_ 360 VehDynYawRateV 1 "Invalid" 0 "Valid" ;
VAL_ 360 VehDynYawRate 4095 "sna" 4094 "error" ;
VAL_ 360 TrnsBrkSysCltchRelRqd 1 "true" 0 "false" ;
VAL_ 360 TracCntrlSysDrIntnt 1 "Enabled" 0 "Disabled" ;
VAL_ 360 VehDynOvrUndrStrV 1 "Invalid" 0 "Valid" ;
VAL_ 360 TCSysEnbld 1 "true" 0 "false" ;
VAL_ 360 TCSysAtv 1 "true" 0 "false" ;
VAL_ 360 BrkPdlDrvAppPrsDetcdV 1 "Invalid" 0 "Valid" ;
VAL_ 360 BrkPdlDrvAppPrsDetcd 1 "true" 0 "false" ;
VAL_ 360 ACCBrkngAct 1 "true" 0 "false" ;
VAL_ 360 ABSFld 1 "true" 0 "false" ;
VAL_ 360 ABSAtv 1 "true" 0 "false" ;
VAL_ 350 HillDesCtrlRedVehSpIO 1 "true" 0 "false" ;
VAL_ 350 EBDFailed 1 "true" 0 "false" ;
VAL_ 350 StWhAnVDA 1 "VirtualDeviceAvailable" 0 "VirtualDeviceUnavailable" ;
VAL_ 350 TirePrsLowIO 1 "true" 0 "false" ;
VAL_ 350 VaccBoostFailure 1 "true" 0 "false" ;
VAL_ 350 VSESysPrs 1 "true" 0 "false" ;
VAL_ 350 HalfSysFail 1 "true" 0 "false" ;
VAL_ 350 ActVehAccel 4095 "sna" 4094 "error" ;
VAL_ 350 ActVehAccelV 1 "Invalid" 0 "Valid" ;
VAL_ 350 BksOvht 1 "true" 0 "false" ;
VAL_ 350 TCSysPr 1 "true" 0 "false" ;
VAL_ 350 ABSPr 1 "true" 0 "false" ;
VAL_ 350 TreInfMonSysRstPrfmd 1 "true" 0 "false" ;
VAL_ 350 ABSIO 1 "true" 0 "false" ;
VAL_ 350 BrkPadWrnIO 1 "true" 0 "false" ;
VAL_ 350 VehStabEnhmntMd 2 "Competitive" 1 "Normal" 0 "Off" ;
VAL_ 350 VehStabEnhmntStat 4 "Not Ready" 3 "Warming Up" 2 "Fault" 1 "Active" 0 "Inactive" ;
VAL_ 350 TCSysOpMd 2 "Off Road" 1 "Normal" 0 "Off" ;
VAL_ 350 TCSysOpStat 2 "Fault" 1 "Active" 0 "Inactive" ;
VAL_ 350 BrkSysVTopSpdLimVal 255 "sna" 254 "error" ;
VAL_ 350 BrkSysRedBrkTlltlReq 1 "true" 0 "false" ;
VAL_ 350 BrkSysBrkLtsReqd 1 "true" 0 "false" ;
VAL_ 157 NotEventStat 2 "Pretensioner Deployment Event" 1 "Near Deployment Event" 0 "No Event" 3 "Airbag Deployment Event" ;
VAL_ 157 BrkAppSnsrHmPosLrnd 1 "true" 0 "false" ;
VAL_ 157 BrkPedTrvlAchvd 1 "true" 0 "false" ;
VAL_ 157 BrkPedTrvlAchvdV 1 "Invalid" 0 "Valid" ;
VAL_ 157 BrkPdlPosGrad 255 "sna" 254 "error" ;
VAL_ 157 BrkPdlModTrvlV 1 "Invalid" 0 "Valid" ;
VAL_ 157 BrkPdlModTrvl 1 "true" 0 "false" ;
SIG_GROUP_ 766 SG_eLCVD_VCU_AD_Info 1 : Fct_Int_Flag_HV_emergency Fct_Int_Flag_shifter Fct_Int_Flag_throttle eLCVDADDrvRqSt eLCVDVCUADInfChs eLCVDVCUADInfARC;
SIG_GROUP_ 162 SG_EPS_AD_Switch 1 : Fct_Int_Flag_EPS EPSADSwARC EPSADSwChs;
SIG_GROUP_ 107 SG_IBC_AD_Switch 1 : Fct_Int_Flag_ECD Fct_Int_Flag_ESC Fct_Int_Flag_TC Fct_Int_Flag_ABS Fct_Int_Flag_stabilization Fct_Int_Flag_brake_emergency Fct_Int_Flag_EPB_button Fct_Int_Flag_brake_pedal IBCADSwChs IBCADSwARC;
SIG_GROUP_ 99 SG_VCU_Driving_Mode 1 : DM_LDW DM_SFS VCU_DM_ARC VCU_DM_Chs DM_Mode_AD_HMI DM_AD_Activation_Clamp;
SIG_GROUP_ 160 SG_EPS_Steering_Wheel_Angle 1 : StrWhlAngSenCalStat StWhlAngChksm StrWhAngGrd StWhlAngAliveRollCnt StrWhAng;
SIG_GROUP_ 544 SG_DCDC12_Info_1 1 : Checksum_220 MessageCounter_220 DC1_VoltageHV DC1_CurrentLV DC1_Mode DC1_CurrentHV DC1_Temp DC1_VoltageLV;
SIG_GROUP_ 1399 SG_HMI_Info 1 : HMI_calender_year HMI_calender_month HMI_calender_day HMI_time_hour HMI_time_minute HMI_time_second HMI_Info_ALC HMI_Info_Chs;
SIG_GROUP_ 112 SG_VCU_EPS_AD_Limit 1 : VCU_EPS_Limit_Chs VCU_EPS_Limit_ARC VCU_EPS_Steering_Rate_Limit VCU_EPS_Upper_Torque_Limit VCU_EPS_Lower_Torque_Limit;
SIG_GROUP_ 111 SG_VCU_EPS_Angle_Control 1 : VCU_EPS_AC_Chs VCU_EPS_AC_ARC VCU_EPS_AC_Haptic_Factor_2 VCU_EPS_AC_Haptic_Factor_1 VCU_EPS_AC_Demand VCU_EPS_AC_Request;
SIG_GROUP_ 110 SG_VCU_EPS_Torque_Overlay 1 : VCU_EPS_TO_Chs VCU_EPS_TO_ARC VCU_EPS_TO_Demand_Direction VCU_EPS_TO_Demand VCU_EPS_TO_Request;
SIG_GROUP_ 161 SG_EPS_Info 1 : EPSLdwFdbk EPSSfsFdbk EPSDrvrTrq EPSTrqOvrlyIntfcSt EPSHndsOnDtctn EPSInfARC EPSInfChs EPSAnglCtrlIntrfcSt EPSAssstAvlbl EPSDgrdtnLvl EPSDrvStrIntfrDtcd EPSIntErrSt SPCTrqRqstLmtd SPCAngRqstLmtd SPCAngVlctRqstLmtd SPCMtrTrqDmndLmtd;
SIG_GROUP_ 357 SG_IBC_Vehicle_Info_2 1 : GlobalRealTimeGS GlobalRealTimeGSVALID VhclDrctnlStCOG IBCVhclInf2Chs IBCVhclInf2ARC VhclVlctCOGV VhclVlctCOG VhStndDtc;
SIG_GROUP_ 850 SG_IBC_IMU 1 : IMUProtYawRtM IMUProtYawRt IMUProtLonAccM IMUProtLonAcc IMUProtLatAccM IMUProtLatAcc IMUProtChksum IMUProtARC;
SIG_GROUP_ 390 BrkPdDrvAppPrsStat 1 : BPDAPS_BkPDrvApPV BPDAPS_BkPDrvApP;
SIG_GROUP_ 630 ElecPrkBrkCmd 1 : EPBC_EPBAccRq EPBC_EPBrkAutBrkRq;
SIG_GROUP_ 1398 SG_IBC_Vehicle_Odometer 1 : IBCVhclOdmtrCks IBCVhclOdmtrARC VehOdo VehOdoV;
SIG_GROUP_ 151 SG_IBC_NonDriven_Wheel_Velocity 1 : IBCNDrvWhlVlctChs IBCNDrvWhlVlctARC WhlRotDrctnlSRtNDrvn WhlRotDrctnlStLfNDrvn WhlGrndVlctyRtNnDrvnV WhlGrndVlctyRtNnDrvn WhlGrndVlctyLftNnDrvnV WhlGrndVlctyLftNnDrvn;
SIG_GROUP_ 150 SG_IBC_Driven_Wheel_Velocity 1 : IBCDrvWhlVlctChs IBCDrvWhlVlctARC WhlRotDrctnlStLftDrvn WhlRotDrctnlStRtDrvn WhlGrndVlctyRtDrvnV WhlGrndVlctyRtDrvn WhlGrndVlctyLftDrvnV WhlGrndVlctyLftDrvn;
SIG_GROUP_ 355 ChsSysEngTorqReqER 1 : CSETRER_TorqReqVal CSETRER_TqIntvnTyp;
SIG_GROUP_ 360 BrkSysTransGearReq 1 : BSTGRReqdGear BSTGRReqType;
SIG_GROUP_ 157 BrkPedInitTrvlAchvdStat 1 : BrkPedTrvlAchvd BrkPedTrvlAchvdV;
